VERSION ""

NS_ :

BS_:

BU_:  Inverter  Battery  Charger  Host

BO_ 2626158596 BATT_diagnosticVBricksB_4: 8 Battery
 SG_ BATT_vBrick06_4 : 16|16@1+ (7.6e-05,0) [0|4.98066] "V" Host
 SG_ BATT_vBrick07_4 : 32|16@1+ (7.6e-05,0) [0|4.98066] "V" Host
 SG_ BATT_vBrick05_4 : 0|16@1+ (7.6e-05,0) [0|4.98066] "V" Host
 SG_ BATT_vBrick08_4 : 48|16@1+ (7.6e-05,0) [0|4.98066] "V" Host

BO_ 2626158597 BATT_diagnosticVBricksB_5: 8 Battery
 SG_ BATT_vBrick06_5 : 16|16@1+ (7.6e-05,0) [0|4.98066] "V" Host
 SG_ BATT_vBrick07_5 : 32|16@1+ (7.6e-05,0) [0|4.98066] "V" Host
 SG_ BATT_vBrick05_5 : 0|16@1+ (7.6e-05,0) [0|4.98066] "V" Host
 SG_ BATT_vBrick08_5 : 48|16@1+ (7.6e-05,0) [0|4.98066] "V" Host

BO_ 2626158598 BATT_diagnosticVBricksB_6: 8 Battery
 SG_ BATT_vBrick06_6 : 16|16@1+ (7.6e-05,0) [0|4.98066] "V" Host
 SG_ BATT_vBrick07_6 : 32|16@1+ (7.6e-05,0) [0|4.98066] "V" Host
 SG_ BATT_vBrick05_6 : 0|16@1+ (7.6e-05,0) [0|4.98066] "V" Host
 SG_ BATT_vBrick08_6 : 48|16@1+ (7.6e-05,0) [0|4.98066] "V" Host

BO_ 2626158599 BATT_diagnosticVBricksB_7: 8 Battery
 SG_ BATT_vBrick06_7 : 16|16@1+ (7.6e-05,0) [0|4.98066] "V" Host
 SG_ BATT_vBrick07_7 : 32|16@1+ (7.6e-05,0) [0|4.98066] "V" Host
 SG_ BATT_vBrick05_7 : 0|16@1+ (7.6e-05,0) [0|4.98066] "V" Host
 SG_ BATT_vBrick08_7 : 48|16@1+ (7.6e-05,0) [0|4.98066] "V" Host

BO_ 2626420736 BATT_diagnosticVBricksC_0: 8 Battery
 SG_ BATT_vBrick12_0 : 48|16@1+ (7.6e-05,0) [0|4.98066] "V" Host
 SG_ BATT_vBrick11_0 : 32|16@1+ (7.6e-05,0) [0|4.98066] "V" Host
 SG_ BATT_vBrick10_0 : 16|16@1+ (7.6e-05,0) [0|4.98066] "V" Host
 SG_ BATT_vBrick09_0 : 0|16@1+ (7.6e-05,0) [0|4.98066] "V" Host

BO_ 2626420737 BATT_diagnosticVBricksC_1: 8 Battery
 SG_ BATT_vBrick12_1 : 48|16@1+ (7.6e-05,0) [0|4.98066] "V" Host
 SG_ BATT_vBrick11_1 : 32|16@1+ (7.6e-05,0) [0|4.98066] "V" Host
 SG_ BATT_vBrick10_1 : 16|16@1+ (7.6e-05,0) [0|4.98066] "V" Host
 SG_ BATT_vBrick09_1 : 0|16@1+ (7.6e-05,0) [0|4.98066] "V" Host

BO_ 2626420738 BATT_diagnosticVBricksC_2: 8 Battery
 SG_ BATT_vBrick12_2 : 48|16@1+ (7.6e-05,0) [0|4.98066] "V" Host
 SG_ BATT_vBrick11_2 : 32|16@1+ (7.6e-05,0) [0|4.98066] "V" Host
 SG_ BATT_vBrick10_2 : 16|16@1+ (7.6e-05,0) [0|4.98066] "V" Host
 SG_ BATT_vBrick09_2 : 0|16@1+ (7.6e-05,0) [0|4.98066] "V" Host

BO_ 2626420739 BATT_diagnosticVBricksC_3: 8 Battery
 SG_ BATT_vBrick12_3 : 48|16@1+ (7.6e-05,0) [0|4.98066] "V" Host
 SG_ BATT_vBrick11_3 : 32|16@1+ (7.6e-05,0) [0|4.98066] "V" Host
 SG_ BATT_vBrick10_3 : 16|16@1+ (7.6e-05,0) [0|4.98066] "V" Host
 SG_ BATT_vBrick09_3 : 0|16@1+ (7.6e-05,0) [0|4.98066] "V" Host

BO_ 2626420740 BATT_diagnosticVBricksC_4: 8 Battery
 SG_ BATT_vBrick12_4 : 48|16@1+ (7.6e-05,0) [0|4.98066] "V" Host
 SG_ BATT_vBrick11_4 : 32|16@1+ (7.6e-05,0) [0|4.98066] "V" Host
 SG_ BATT_vBrick10_4 : 16|16@1+ (7.6e-05,0) [0|4.98066] "V" Host
 SG_ BATT_vBrick09_4 : 0|16@1+ (7.6e-05,0) [0|4.98066] "V" Host

BO_ 2626420741 BATT_diagnosticVBricksC_5: 8 Battery
 SG_ BATT_vBrick12_5 : 48|16@1+ (7.6e-05,0) [0|4.98066] "V" Host
 SG_ BATT_vBrick11_5 : 32|16@1+ (7.6e-05,0) [0|4.98066] "V" Host
 SG_ BATT_vBrick10_5 : 16|16@1+ (7.6e-05,0) [0|4.98066] "V" Host
 SG_ BATT_vBrick09_5 : 0|16@1+ (7.6e-05,0) [0|4.98066] "V" Host

BO_ 2626420742 BATT_diagnosticVBricksC_6: 8 Battery
 SG_ BATT_vBrick12_6 : 48|16@1+ (7.6e-05,0) [0|4.98066] "V" Host
 SG_ BATT_vBrick11_6 : 32|16@1+ (7.6e-05,0) [0|4.98066] "V" Host
 SG_ BATT_vBrick10_6 : 16|16@1+ (7.6e-05,0) [0|4.98066] "V" Host
 SG_ BATT_vBrick09_6 : 0|16@1+ (7.6e-05,0) [0|4.98066] "V" Host

BO_ 2626420743 BATT_diagnosticVBricksC_7: 8 Battery
 SG_ BATT_vBrick12_7 : 48|16@1+ (7.6e-05,0) [0|4.98066] "V" Host
 SG_ BATT_vBrick11_7 : 32|16@1+ (7.6e-05,0) [0|4.98066] "V" Host
 SG_ BATT_vBrick10_7 : 16|16@1+ (7.6e-05,0) [0|4.98066] "V" Host
 SG_ BATT_vBrick09_7 : 0|16@1+ (7.6e-05,0) [0|4.98066] "V" Host

BO_ 2626682880 BATT_diagnosticVBricksD_0: 4 Battery
 SG_ BATT_vBrick14_0 : 16|16@1+ (7.6e-05,0) [0|4.98066] "V" Host
 SG_ BATT_vBrick13_0 : 0|16@1+ (7.6e-05,0) [0|4.98066] "V" Host

BO_ 2626682881 BATT_diagnosticVBricksD_1: 4 Battery
 SG_ BATT_vBrick14_1 : 16|16@1+ (7.6e-05,0) [0|4.98066] "V" Host
 SG_ BATT_vBrick13_1 : 0|16@1+ (7.6e-05,0) [0|4.98066] "V" Host

BO_ 2626682882 BATT_diagnosticVBricksD_2: 4 Battery
 SG_ BATT_vBrick14_2 : 16|16@1+ (7.6e-05,0) [0|4.98066] "V" Host
 SG_ BATT_vBrick13_2 : 0|16@1+ (7.6e-05,0) [0|4.98066] "V" Host

BO_ 2626682883 BATT_diagnosticVBricksD_3: 4 Battery
 SG_ BATT_vBrick14_3 : 16|16@1+ (7.6e-05,0) [0|4.98066] "V" Host
 SG_ BATT_vBrick13_3 : 0|16@1+ (7.6e-05,0) [0|4.98066] "V" Host

BO_ 2626682884 BATT_diagnosticVBricksD_4: 4 Battery
 SG_ BATT_vBrick14_4 : 16|16@1+ (7.6e-05,0) [0|4.98066] "V" Host
 SG_ BATT_vBrick13_4 : 0|16@1+ (7.6e-05,0) [0|4.98066] "V" Host

BO_ 2626682885 BATT_diagnosticVBricksD_5: 4 Battery
 SG_ BATT_vBrick14_5 : 16|16@1+ (7.6e-05,0) [0|4.98066] "V" Host
 SG_ BATT_vBrick13_5 : 0|16@1+ (7.6e-05,0) [0|4.98066] "V" Host

BO_ 2626682886 BATT_diagnosticVBricksD_6: 4 Battery
 SG_ BATT_vBrick14_6 : 16|16@1+ (7.6e-05,0) [0|4.98066] "V" Host
 SG_ BATT_vBrick13_6 : 0|16@1+ (7.6e-05,0) [0|4.98066] "V" Host

BO_ 2626682887 BATT_diagnosticVBricksD_7: 4 Battery
 SG_ BATT_vBrick14_7 : 16|16@1+ (7.6e-05,0) [0|4.98066] "V" Host
 SG_ BATT_vBrick13_7 : 0|16@1+ (7.6e-05,0) [0|4.98066] "V" Host

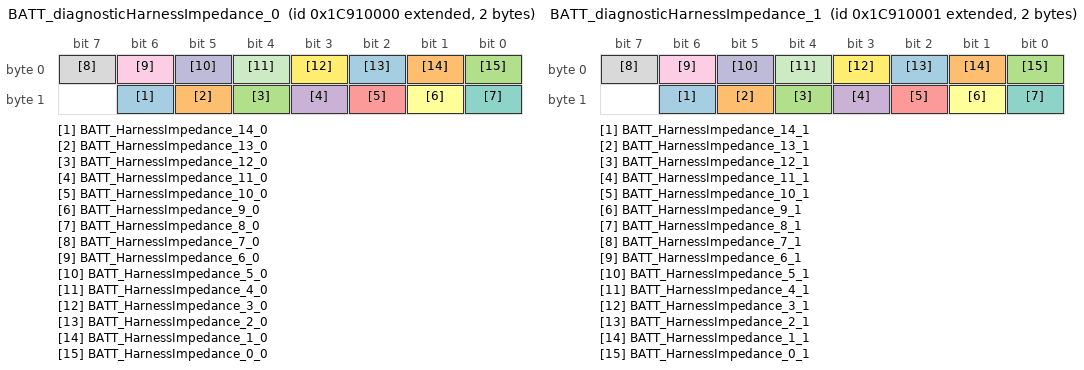
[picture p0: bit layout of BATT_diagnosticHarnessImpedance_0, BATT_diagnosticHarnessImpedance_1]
BO_ 2626748416 BATT_diagnosticHarnessImpedance_0: 2 Battery
 SG_ BATT_HarnessImpedance_14_0 : 14|1@1+ (1,0) [0|1] "mOhms" Host
 SG_ BATT_HarnessImpedance_13_0 : 13|1@1+ (1,0) [0|1] "mOhms" Host
 SG_ BATT_HarnessImpedance_12_0 : 12|1@1+ (1,0) [0|1] "mOhms" Host
 SG_ BATT_HarnessImpedance_11_0 : 11|1@1+ (1,0) [0|1] "mOhms" Host
 SG_ BATT_HarnessImpedance_10_0 : 10|1@1+ (1,0) [0|1] "mOhms" Host
 SG_ BATT_HarnessImpedance_9_0 : 9|1@1+ (1,0) [0|1] "mOhms" Host
 SG_ BATT_HarnessImpedance_8_0 : 8|1@1+ (1,0) [0|1] "mOhms" Host
 SG_ BATT_HarnessImpedance_7_0 : 7|1@1+ (1,0) [0|1] "mOhms" Host
 SG_ BATT_HarnessImpedance_6_0 : 6|1@1+ (1,0) [0|1] "mOhms" Host
 SG_ BATT_HarnessImpedance_5_0 : 5|1@1+ (1,0) [0|1] "mOhms" Host
 SG_ BATT_HarnessImpedance_4_0 : 4|1@1+ (1,0) [0|1] "mOhms" Host
 SG_ BATT_HarnessImpedance_3_0 : 3|1@1+ (1,0) [0|1] "mOhms" Host
 SG_ BATT_HarnessImpedance_2_0 : 2|1@1+ (1,0) [0|1] "mOhms" Host
 SG_ BATT_HarnessImpedance_1_0 : 1|1@1+ (1,0) [0|1] "mOhms" Host
 SG_ BATT_HarnessImpedance_0_0 : 0|1@1+ (1,0) [0|1] "mOhms" Host

BO_ 2626748417 BATT_diagnosticHarnessImpedance_1: 2 Battery
 SG_ BATT_HarnessImpedance_14_1 : 14|1@1+ (1,0) [0|1] "mOhms" Host
 SG_ BATT_HarnessImpedance_13_1 : 13|1@1+ (1,0) [0|1] "mOhms" Host
 SG_ BATT_HarnessImpedance_12_1 : 12|1@1+ (1,0) [0|1] "mOhms" Host
 SG_ BATT_HarnessImpedance_11_1 : 11|1@1+ (1,0) [0|1] "mOhms" Host
 SG_ BATT_HarnessImpedance_10_1 : 10|1@1+ (1,0) [0|1] "mOhms" Host
 SG_ BATT_HarnessImpedance_9_1 : 9|1@1+ (1,0) [0|1] "mOhms" Host
 SG_ BATT_HarnessImpedance_8_1 : 8|1@1+ (1,0) [0|1] "mOhms" Host
 SG_ BATT_HarnessImpedance_7_1 : 7|1@1+ (1,0) [0|1] "mOhms" Host
 SG_ BATT_HarnessImpedance_6_1 : 6|1@1+ (1,0) [0|1] "mOhms" Host
 SG_ BATT_HarnessImpedance_5_1 : 5|1@1+ (1,0) [0|1] "mOhms" Host
 SG_ BATT_HarnessImpedance_4_1 : 4|1@1+ (1,0) [0|1] "mOhms" Host
 SG_ BATT_HarnessImpedance_3_1 : 3|1@1+ (1,0) [0|1] "mOhms" Host
 SG_ BATT_HarnessImpedance_2_1 : 2|1@1+ (1,0) [0|1] "mOhms" Host
 SG_ BATT_HarnessImpedance_1_1 : 1|1@1+ (1,0) [0|1] "mOhms" Host
 SG_ BATT_HarnessImpedance_0_1 : 0|1@1+ (1,0) [0|1] "mOhms" Host

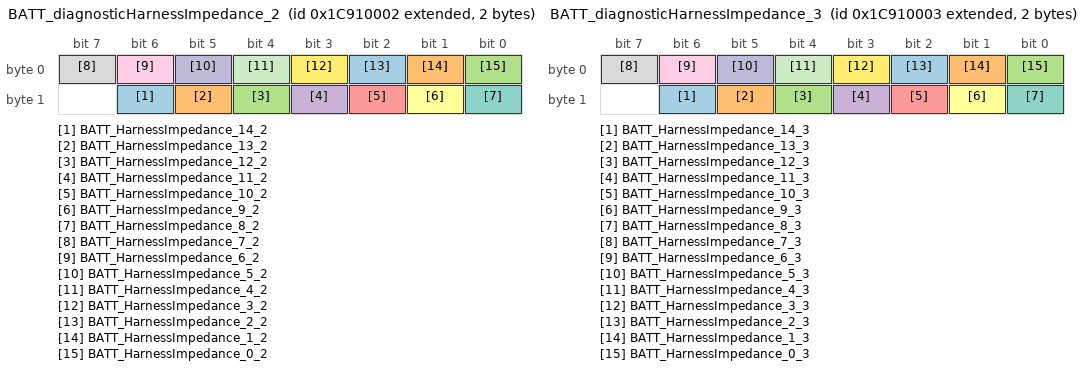
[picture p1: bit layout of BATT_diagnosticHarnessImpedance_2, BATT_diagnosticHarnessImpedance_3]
BO_ 2626748418 BATT_diagnosticHarnessImpedance_2: 2 Battery
 SG_ BATT_HarnessImpedance_14_2 : 14|1@1+ (1,0) [0|1] "mOhms" Host
 SG_ BATT_HarnessImpedance_13_2 : 13|1@1+ (1,0) [0|1] "mOhms" Host
 SG_ BATT_HarnessImpedance_12_2 : 12|1@1+ (1,0) [0|1] "mOhms" Host
 SG_ BATT_HarnessImpedance_11_2 : 11|1@1+ (1,0) [0|1] "mOhms" Host
 SG_ BATT_HarnessImpedance_10_2 : 10|1@1+ (1,0) [0|1] "mOhms" Host
 SG_ BATT_HarnessImpedance_9_2 : 9|1@1+ (1,0) [0|1] "mOhms" Host
 SG_ BATT_HarnessImpedance_8_2 : 8|1@1+ (1,0) [0|1] "mOhms" Host
 SG_ BATT_HarnessImpedance_7_2 : 7|1@1+ (1,0) [0|1] "mOhms" Host
 SG_ BATT_HarnessImpedance_6_2 : 6|1@1+ (1,0) [0|1] "mOhms" Host
 SG_ BATT_HarnessImpedance_5_2 : 5|1@1+ (1,0) [0|1] "mOhms" Host
 SG_ BATT_HarnessImpedance_4_2 : 4|1@1+ (1,0) [0|1] "mOhms" Host
 SG_ BATT_HarnessImpedance_3_2 : 3|1@1+ (1,0) [0|1] "mOhms" Host
 SG_ BATT_HarnessImpedance_2_2 : 2|1@1+ (1,0) [0|1] "mOhms" Host
 SG_ BATT_HarnessImpedance_1_2 : 1|1@1+ (1,0) [0|1] "mOhms" Host
 SG_ BATT_HarnessImpedance_0_2 : 0|1@1+ (1,0) [0|1] "mOhms" Host

BO_ 2626748419 BATT_diagnosticHarnessImpedance_3: 2 Battery
 SG_ BATT_HarnessImpedance_14_3 : 14|1@1+ (1,0) [0|1] "mOhms" Host
 SG_ BATT_HarnessImpedance_13_3 : 13|1@1+ (1,0) [0|1] "mOhms" Host
 SG_ BATT_HarnessImpedance_12_3 : 12|1@1+ (1,0) [0|1] "mOhms" Host
 SG_ BATT_HarnessImpedance_11_3 : 11|1@1+ (1,0) [0|1] "mOhms" Host
 SG_ BATT_HarnessImpedance_10_3 : 10|1@1+ (1,0) [0|1] "mOhms" Host
 SG_ BATT_HarnessImpedance_9_3 : 9|1@1+ (1,0) [0|1] "mOhms" Host
 SG_ BATT_HarnessImpedance_8_3 : 8|1@1+ (1,0) [0|1] "mOhms" Host
 SG_ BATT_HarnessImpedance_7_3 : 7|1@1+ (1,0) [0|1] "mOhms" Host
 SG_ BATT_HarnessImpedance_6_3 : 6|1@1+ (1,0) [0|1] "mOhms" Host
 SG_ BATT_HarnessImpedance_5_3 : 5|1@1+ (1,0) [0|1] "mOhms" Host
 SG_ BATT_HarnessImpedance_4_3 : 4|1@1+ (1,0) [0|1] "mOhms" Host
 SG_ BATT_HarnessImpedance_3_3 : 3|1@1+ (1,0) [0|1] "mOhms" Host
 SG_ BATT_HarnessImpedance_2_3 : 2|1@1+ (1,0) [0|1] "mOhms" Host
 SG_ BATT_HarnessImpedance_1_3 : 1|1@1+ (1,0) [0|1] "mOhms" Host
 SG_ BATT_HarnessImpedance_0_3 : 0|1@1+ (1,0) [0|1] "mOhms" Host

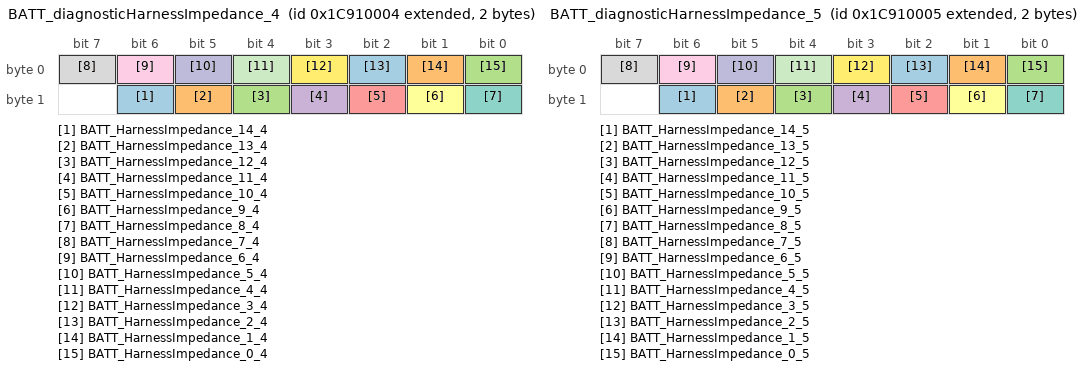
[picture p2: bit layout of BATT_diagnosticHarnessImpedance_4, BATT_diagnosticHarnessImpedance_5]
BO_ 2626748420 BATT_diagnosticHarnessImpedance_4: 2 Battery
 SG_ BATT_HarnessImpedance_14_4 : 14|1@1+ (1,0) [0|1] "mOhms" Host
 SG_ BATT_HarnessImpedance_13_4 : 13|1@1+ (1,0) [0|1] "mOhms" Host
 SG_ BATT_HarnessImpedance_12_4 : 12|1@1+ (1,0) [0|1] "mOhms" Host
 SG_ BATT_HarnessImpedance_11_4 : 11|1@1+ (1,0) [0|1] "mOhms" Host
 SG_ BATT_HarnessImpedance_10_4 : 10|1@1+ (1,0) [0|1] "mOhms" Host
 SG_ BATT_HarnessImpedance_9_4 : 9|1@1+ (1,0) [0|1] "mOhms" Host
 SG_ BATT_HarnessImpedance_8_4 : 8|1@1+ (1,0) [0|1] "mOhms" Host
 SG_ BATT_HarnessImpedance_7_4 : 7|1@1+ (1,0) [0|1] "mOhms" Host
 SG_ BATT_HarnessImpedance_6_4 : 6|1@1+ (1,0) [0|1] "mOhms" Host
 SG_ BATT_HarnessImpedance_5_4 : 5|1@1+ (1,0) [0|1] "mOhms" Host
 SG_ BATT_HarnessImpedance_4_4 : 4|1@1+ (1,0) [0|1] "mOhms" Host
 SG_ BATT_HarnessImpedance_3_4 : 3|1@1+ (1,0) [0|1] "mOhms" Host
 SG_ BATT_HarnessImpedance_2_4 : 2|1@1+ (1,0) [0|1] "mOhms" Host
 SG_ BATT_HarnessImpedance_1_4 : 1|1@1+ (1,0) [0|1] "mOhms" Host
 SG_ BATT_HarnessImpedance_0_4 : 0|1@1+ (1,0) [0|1] "mOhms" Host

BO_ 2626748421 BATT_diagnosticHarnessImpedance_5: 2 Battery
 SG_ BATT_HarnessImpedance_14_5 : 14|1@1+ (1,0) [0|1] "mOhms" Host
 SG_ BATT_HarnessImpedance_13_5 : 13|1@1+ (1,0) [0|1] "mOhms" Host
 SG_ BATT_HarnessImpedance_12_5 : 12|1@1+ (1,0) [0|1] "mOhms" Host
 SG_ BATT_HarnessImpedance_11_5 : 11|1@1+ (1,0) [0|1] "mOhms" Host
 SG_ BATT_HarnessImpedance_10_5 : 10|1@1+ (1,0) [0|1] "mOhms" Host
 SG_ BATT_HarnessImpedance_9_5 : 9|1@1+ (1,0) [0|1] "mOhms" Host
 SG_ BATT_HarnessImpedance_8_5 : 8|1@1+ (1,0) [0|1] "mOhms" Host
 SG_ BATT_HarnessImpedance_7_5 : 7|1@1+ (1,0) [0|1] "mOhms" Host
 SG_ BATT_HarnessImpedance_6_5 : 6|1@1+ (1,0) [0|1] "mOhms" Host
 SG_ BATT_HarnessImpedance_5_5 : 5|1@1+ (1,0) [0|1] "mOhms" Host
 SG_ BATT_HarnessImpedance_4_5 : 4|1@1+ (1,0) [0|1] "mOhms" Host
 SG_ BATT_HarnessImpedance_3_5 : 3|1@1+ (1,0) [0|1] "mOhms" Host
 SG_ BATT_HarnessImpedance_2_5 : 2|1@1+ (1,0) [0|1] "mOhms" Host
 SG_ BATT_HarnessImpedance_1_5 : 1|1@1+ (1,0) [0|1] "mOhms" Host
 SG_ BATT_HarnessImpedance_0_5 : 0|1@1+ (1,0) [0|1] "mOhms" Host

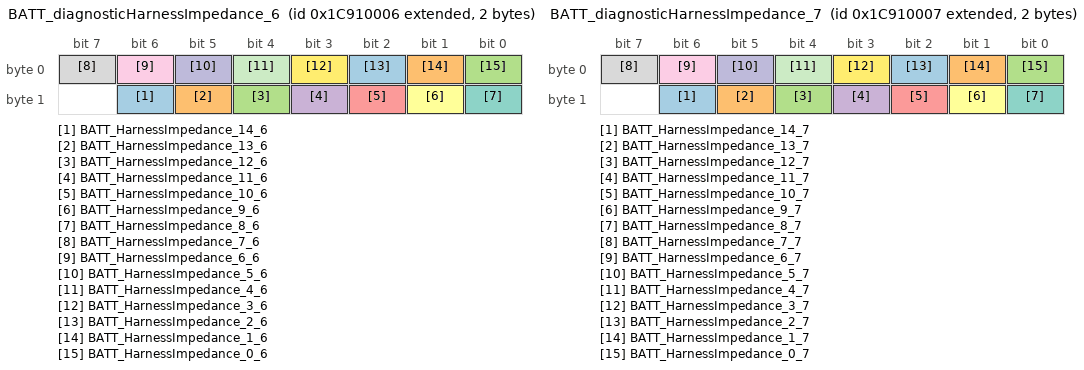
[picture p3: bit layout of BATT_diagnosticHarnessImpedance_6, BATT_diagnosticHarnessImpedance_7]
BO_ 2626748422 BATT_diagnosticHarnessImpedance_6: 2 Battery
 SG_ BATT_HarnessImpedance_14_6 : 14|1@1+ (1,0) [0|1] "mOhms" Host
 SG_ BATT_HarnessImpedance_13_6 : 13|1@1+ (1,0) [0|1] "mOhms" Host
 SG_ BATT_HarnessImpedance_12_6 : 12|1@1+ (1,0) [0|1] "mOhms" Host
 SG_ BATT_HarnessImpedance_11_6 : 11|1@1+ (1,0) [0|1] "mOhms" Host
 SG_ BATT_HarnessImpedance_10_6 : 10|1@1+ (1,0) [0|1] "mOhms" Host
 SG_ BATT_HarnessImpedance_9_6 : 9|1@1+ (1,0) [0|1] "mOhms" Host
 SG_ BATT_HarnessImpedance_8_6 : 8|1@1+ (1,0) [0|1] "mOhms" Host
 SG_ BATT_HarnessImpedance_7_6 : 7|1@1+ (1,0) [0|1] "mOhms" Host
 SG_ BATT_HarnessImpedance_6_6 : 6|1@1+ (1,0) [0|1] "mOhms" Host
 SG_ BATT_HarnessImpedance_5_6 : 5|1@1+ (1,0) [0|1] "mOhms" Host
 SG_ BATT_HarnessImpedance_4_6 : 4|1@1+ (1,0) [0|1] "mOhms" Host
 SG_ BATT_HarnessImpedance_3_6 : 3|1@1+ (1,0) [0|1] "mOhms" Host
 SG_ BATT_HarnessImpedance_2_6 : 2|1@1+ (1,0) [0|1] "mOhms" Host
 SG_ BATT_HarnessImpedance_1_6 : 1|1@1+ (1,0) [0|1] "mOhms" Host
 SG_ BATT_HarnessImpedance_0_6 : 0|1@1+ (1,0) [0|1] "mOhms" Host

BO_ 2626748423 BATT_diagnosticHarnessImpedance_7: 2 Battery
 SG_ BATT_HarnessImpedance_14_7 : 14|1@1+ (1,0) [0|1] "mOhms" Host
 SG_ BATT_HarnessImpedance_13_7 : 13|1@1+ (1,0) [0|1] "mOhms" Host
 SG_ BATT_HarnessImpedance_12_7 : 12|1@1+ (1,0) [0|1] "mOhms" Host
 SG_ BATT_HarnessImpedance_11_7 : 11|1@1+ (1,0) [0|1] "mOhms" Host
 SG_ BATT_HarnessImpedance_10_7 : 10|1@1+ (1,0) [0|1] "mOhms" Host
 SG_ BATT_HarnessImpedance_9_7 : 9|1@1+ (1,0) [0|1] "mOhms" Host
 SG_ BATT_HarnessImpedance_8_7 : 8|1@1+ (1,0) [0|1] "mOhms" Host
 SG_ BATT_HarnessImpedance_7_7 : 7|1@1+ (1,0) [0|1] "mOhms" Host
 SG_ BATT_HarnessImpedance_6_7 : 6|1@1+ (1,0) [0|1] "mOhms" Host
 SG_ BATT_HarnessImpedance_5_7 : 5|1@1+ (1,0) [0|1] "mOhms" Host
 SG_ BATT_HarnessImpedance_4_7 : 4|1@1+ (1,0) [0|1] "mOhms" Host
 SG_ BATT_HarnessImpedance_3_7 : 3|1@1+ (1,0) [0|1] "mOhms" Host
 SG_ BATT_HarnessImpedance_2_7 : 2|1@1+ (1,0) [0|1] "mOhms" Host
 SG_ BATT_HarnessImpedance_1_7 : 1|1@1+ (1,0) [0|1] "mOhms" Host
 SG_ BATT_HarnessImpedance_0_7 : 0|1@1+ (1,0) [0|1] "mOhms" Host

BO_ 2626813952 BATT_diagnosticHrnsImpDleta_0_0: 8 Battery
 SG_ BATT_HrnsImpDelta_3_0 : 48|16@1- (0.001,0) [-32.768|32.767] "mV" Host
 SG_ BATT_HrnsImpDelta_2_0 : 32|16@1- (0.001,0) [-32.768|32.767] "mV" Host
 SG_ BATT_HrnsImpDelta_1_0 : 16|16@1- (0.001,0) [-32.768|32.767] "mV" Host
 SG_ BATT_HrnsImpDelta_0_0 : 0|16@1- (0.001,0) [-32.768|32.767] "mV" Host

BO_ 2626813953 BATT_diagnosticHrnsImpDleta_0_1: 8 Battery
 SG_ BATT_HrnsImpDelta_3_1 : 48|16@1- (0.001,0) [-32.768|32.767] "mV" Host
 SG_ BATT_HrnsImpDelta_2_1 : 32|16@1- (0.001,0) [-32.768|32.767] "mV" Host
 SG_ BATT_HrnsImpDelta_1_1 : 16|16@1- (0.001,0) [-32.768|32.767] "mV" Host
 SG_ BATT_HrnsImpDelta_0_1 : 0|16@1- (0.001,0) [-32.768|32.767] "mV" Host

BO_ 2626813954 BATT_diagnosticHrnsImpDleta_0_2: 8 Battery
 SG_ BATT_HrnsImpDelta_3_2 : 48|16@1- (0.001,0) [-32.768|32.767] "mV" Host
 SG_ BATT_HrnsImpDelta_2_2 : 32|16@1- (0.001,0) [-32.768|32.767] "mV" Host
 SG_ BATT_HrnsImpDelta_1_2 : 16|16@1- (0.001,0) [-32.768|32.767] "mV" Host
 SG_ BATT_HrnsImpDelta_0_2 : 0|16@1- (0.001,0) [-32.768|32.767] "mV" Host

BO_ 2626813955 BATT_diagnosticHrnsImpDleta_0_3: 8 Battery
 SG_ BATT_HrnsImpDelta_3_3 : 48|16@1- (0.001,0) [-32.768|32.767] "mV" Host
 SG_ BATT_HrnsImpDelta_2_3 : 32|16@1- (0.001,0) [-32.768|32.767] "mV" Host
 SG_ BATT_HrnsImpDelta_1_3 : 16|16@1- (0.001,0) [-32.768|32.767] "mV" Host
 SG_ BATT_HrnsImpDelta_0_3 : 0|16@1- (0.001,0) [-32.768|32.767] "mV" Host

BO_ 2626813956 BATT_diagnosticHrnsImpDleta_0_4: 8 Battery
 SG_ BATT_HrnsImpDelta_3_4 : 48|16@1- (0.001,0) [-32.768|32.767] "mV" Host
 SG_ BATT_HrnsImpDelta_2_4 : 32|16@1- (0.001,0) [-32.768|32.767] "mV" Host
 SG_ BATT_HrnsImpDelta_1_4 : 16|16@1- (0.001,0) [-32.768|32.767] "mV" Host
 SG_ BATT_HrnsImpDelta_0_4 : 0|16@1- (0.001,0) [-32.768|32.767] "mV" Host

BO_ 2626813957 BATT_diagnosticHrnsImpDleta_0_5: 8 Battery
 SG_ BATT_HrnsImpDelta_3_5 : 48|16@1- (0.001,0) [-32.768|32.767] "mV" Host
 SG_ BATT_HrnsImpDelta_2_5 : 32|16@1- (0.001,0) [-32.768|32.767] "mV" Host
 SG_ BATT_HrnsImpDelta_1_5 : 16|16@1- (0.001,0) [-32.768|32.767] "mV" Host
 SG_ BATT_HrnsImpDelta_0_5 : 0|16@1- (0.001,0) [-32.768|32.767] "mV" Host

BO_ 2626813958 BATT_diagnosticHrnsImpDleta_0_6: 8 Battery
 SG_ BATT_HrnsImpDelta_3_6 : 48|16@1- (0.001,0) [-32.768|32.767] "mV" Host
 SG_ BATT_HrnsImpDelta_2_6 : 32|16@1- (0.001,0) [-32.768|32.767] "mV" Host
 SG_ BATT_HrnsImpDelta_1_6 : 16|16@1- (0.001,0) [-32.768|32.767] "mV" Host
 SG_ BATT_HrnsImpDelta_0_6 : 0|16@1- (0.001,0) [-32.768|32.767] "mV" Host

BO_ 2626813959 BATT_diagnosticHrnsImpDleta_0_7: 8 Battery
 SG_ BATT_HrnsImpDelta_3_7 : 48|16@1- (0.001,0) [-32.768|32.767] "mV" Host
 SG_ BATT_HrnsImpDelta_2_7 : 32|16@1- (0.001,0) [-32.768|32.767] "mV" Host
 SG_ BATT_HrnsImpDelta_1_7 : 16|16@1- (0.001,0) [-32.768|32.767] "mV" Host
 SG_ BATT_HrnsImpDelta_0_7 : 0|16@1- (0.001,0) [-32.768|32.767] "mV" Host

BO_ 2626818048 BATT_diagnosticHrnsImpDleta_1_0: 8 Battery
 SG_ BATT_HrnsImpDelta_7_0 : 48|16@1- (0.001,0) [-32.768|32.767] "mV" Host
 SG_ BATT_HrnsImpDelta_6_0 : 32|16@1- (0.001,0) [-32.768|32.767] "mV" Host
 SG_ BATT_HrnsImpDelta_5_0 : 16|16@1- (0.001,0) [-32.768|32.767] "mV" Host
 SG_ BATT_HrnsImpDelta_4_0 : 0|16@1- (0.001,0) [-32.768|32.767] "mV" Host

BO_ 2626818049 BATT_diagnosticHrnsImpDleta_1_1: 8 Battery
 SG_ BATT_HrnsImpDelta_7_1 : 48|16@1- (0.001,0) [-32.768|32.767] "mV" Host
 SG_ BATT_HrnsImpDelta_6_1 : 32|16@1- (0.001,0) [-32.768|32.767] "mV" Host
 SG_ BATT_HrnsImpDelta_5_1 : 16|16@1- (0.001,0) [-32.768|32.767] "mV" Host
 SG_ BATT_HrnsImpDelta_4_1 : 0|16@1- (0.001,0) [-32.768|32.767] "mV" Host

BO_ 2626818050 BATT_diagnosticHrnsImpDleta_1_2: 8 Battery
 SG_ BATT_HrnsImpDelta_7_2 : 48|16@1- (0.001,0) [-32.768|32.767] "mV" Host
 SG_ BATT_HrnsImpDelta_6_2 : 32|16@1- (0.001,0) [-32.768|32.767] "mV" Host
 SG_ BATT_HrnsImpDelta_5_2 : 16|16@1- (0.001,0) [-32.768|32.767] "mV" Host
 SG_ BATT_HrnsImpDelta_4_2 : 0|16@1- (0.001,0) [-32.768|32.767] "mV" Host

BO_ 2626818051 BATT_diagnosticHrnsImpDleta_1_3: 8 Battery
 SG_ BATT_HrnsImpDelta_7_3 : 48|16@1- (0.001,0) [-32.768|32.767] "mV" Host
 SG_ BATT_HrnsImpDelta_6_3 : 32|16@1- (0.001,0) [-32.768|32.767] "mV" Host
 SG_ BATT_HrnsImpDelta_5_3 : 16|16@1- (0.001,0) [-32.768|32.767] "mV" Host
 SG_ BATT_HrnsImpDelta_4_3 : 0|16@1- (0.001,0) [-32.768|32.767] "mV" Host

BO_ 2626818052 BATT_diagnosticHrnsImpDleta_1_4: 8 Battery
 SG_ BATT_HrnsImpDelta_7_4 : 48|16@1- (0.001,0) [-32.768|32.767] "mV" Host
 SG_ BATT_HrnsImpDelta_6_4 : 32|16@1- (0.001,0) [-32.768|32.767] "mV" Host
 SG_ BATT_HrnsImpDelta_5_4 : 16|16@1- (0.001,0) [-32.768|32.767] "mV" Host
 SG_ BATT_HrnsImpDelta_4_4 : 0|16@1- (0.001,0) [-32.768|32.767] "mV" Host

BO_ 2626818053 BATT_diagnosticHrnsImpDleta_1_5: 8 Battery
 SG_ BATT_HrnsImpDelta_7_5 : 48|16@1- (0.001,0) [-32.768|32.767] "mV" Host
 SG_ BATT_HrnsImpDelta_6_5 : 32|16@1- (0.001,0) [-32.768|32.767] "mV" Host
 SG_ BATT_HrnsImpDelta_5_5 : 16|16@1- (0.001,0) [-32.768|32.767] "mV" Host
 SG_ BATT_HrnsImpDelta_4_5 : 0|16@1- (0.001,0) [-32.768|32.767] "mV" Host

BO_ 2626818054 BATT_diagnosticHrnsImpDleta_1_6: 8 Battery
 SG_ BATT_HrnsImpDelta_7_6 : 48|16@1- (0.001,0) [-32.768|32.767] "mV" Host
 SG_ BATT_HrnsImpDelta_6_6 : 32|16@1- (0.001,0) [-32.768|32.767] "mV" Host
 SG_ BATT_HrnsImpDelta_5_6 : 16|16@1- (0.001,0) [-32.768|32.767] "mV" Host
 SG_ BATT_HrnsImpDelta_4_6 : 0|16@1- (0.001,0) [-32.768|32.767] "mV" Host

BO_ 2626818055 BATT_diagnosticHrnsImpDleta_1_7: 8 Battery
 SG_ BATT_HrnsImpDelta_7_7 : 48|16@1- (0.001,0) [-32.768|32.767] "mV" Host
 SG_ BATT_HrnsImpDelta_6_7 : 32|16@1- (0.001,0) [-32.768|32.767] "mV" Host
 SG_ BATT_HrnsImpDelta_5_7 : 16|16@1- (0.001,0) [-32.768|32.767] "mV" Host
 SG_ BATT_HrnsImpDelta_4_7 : 0|16@1- (0.001,0) [-32.768|32.767] "mV" Host

BO_ 2626822144 BATT_diagnosticHrnsImpDleta_2_0: 8 Battery
 SG_ BATT_HrnsImpDelta_11_0 : 48|16@1- (0.001,0) [-32.768|32.767] "mV" Host
 SG_ BATT_HrnsImpDelta_10_0 : 32|16@1- (0.001,0) [-32.768|32.767] "mV" Host
 SG_ BATT_HrnsImpDelta_9_0 : 16|16@1- (0.001,0) [-32.768|32.767] "mV" Host
 SG_ BATT_HrnsImpDelta_8_0 : 0|16@1- (0.001,0) [-32.768|32.767] "mV" Host

BO_ 2626822145 BATT_diagnosticHrnsImpDleta_2_1: 8 Battery
 SG_ BATT_HrnsImpDelta_11_1 : 48|16@1- (0.001,0) [-32.768|32.767] "mV" Host
 SG_ BATT_HrnsImpDelta_10_1 : 32|16@1- (0.001,0) [-32.768|32.767] "mV" Host
 SG_ BATT_HrnsImpDelta_9_1 : 16|16@1- (0.001,0) [-32.768|32.767] "mV" Host
 SG_ BATT_HrnsImpDelta_8_1 : 0|16@1- (0.001,0) [-32.768|32.767] "mV" Host

BO_ 2626822146 BATT_diagnosticHrnsImpDleta_2_2: 8 Battery
 SG_ BATT_HrnsImpDelta_11_2 : 48|16@1- (0.001,0) [-32.768|32.767] "mV" Host
 SG_ BATT_HrnsImpDelta_10_2 : 32|16@1- (0.001,0) [-32.768|32.767] "mV" Host
 SG_ BATT_HrnsImpDelta_9_2 : 16|16@1- (0.001,0) [-32.768|32.767] "mV" Host
 SG_ BATT_HrnsImpDelta_8_2 : 0|16@1- (0.001,0) [-32.768|32.767] "mV" Host

BO_ 2626822147 BATT_diagnosticHrnsImpDleta_2_3: 8 Battery
 SG_ BATT_HrnsImpDelta_11_3 : 48|16@1- (0.001,0) [-32.768|32.767] "mV" Host
 SG_ BATT_HrnsImpDelta_10_3 : 32|16@1- (0.001,0) [-32.768|32.767] "mV" Host
 SG_ BATT_HrnsImpDelta_9_3 : 16|16@1- (0.001,0) [-32.768|32.767] "mV" Host
 SG_ BATT_HrnsImpDelta_8_3 : 0|16@1- (0.001,0) [-32.768|32.767] "mV" Host

BO_ 2626822148 BATT_diagnosticHrnsImpDleta_2_4: 8 Battery
 SG_ BATT_HrnsImpDelta_11_4 : 48|16@1- (0.001,0) [-32.768|32.767] "mV" Host
 SG_ BATT_HrnsImpDelta_10_4 : 32|16@1- (0.001,0) [-32.768|32.767] "mV" Host
 SG_ BATT_HrnsImpDelta_9_4 : 16|16@1- (0.001,0) [-32.768|32.767] "mV" Host
 SG_ BATT_HrnsImpDelta_8_4 : 0|16@1- (0.001,0) [-32.768|32.767] "mV" Host

BO_ 2626822149 BATT_diagnosticHrnsImpDleta_2_5: 8 Battery
 SG_ BATT_HrnsImpDelta_11_5 : 48|16@1- (0.001,0) [-32.768|32.767] "mV" Host
 SG_ BATT_HrnsImpDelta_10_5 : 32|16@1- (0.001,0) [-32.768|32.767] "mV" Host
 SG_ BATT_HrnsImpDelta_9_5 : 16|16@1- (0.001,0) [-32.768|32.767] "mV" Host
 SG_ BATT_HrnsImpDelta_8_5 : 0|16@1- (0.001,0) [-32.768|32.767] "mV" Host

BO_ 2626822150 BATT_diagnosticHrnsImpDleta_2_6: 8 Battery
 SG_ BATT_HrnsImpDelta_11_6 : 48|16@1- (0.001,0) [-32.768|32.767] "mV" Host
 SG_ BATT_HrnsImpDelta_10_6 : 32|16@1- (0.001,0) [-32.768|32.767] "mV" Host
 SG_ BATT_HrnsImpDelta_9_6 : 16|16@1- (0.001,0) [-32.768|32.767] "mV" Host
 SG_ BATT_HrnsImpDelta_8_6 : 0|16@1- (0.001,0) [-32.768|32.767] "mV" Host

BO_ 2626822151 BATT_diagnosticHrnsImpDleta_2_7: 8 Battery
 SG_ BATT_HrnsImpDelta_11_7 : 48|16@1- (0.001,0) [-32.768|32.767] "mV" Host
 SG_ BATT_HrnsImpDelta_10_7 : 32|16@1- (0.001,0) [-32.768|32.767] "mV" Host
 SG_ BATT_HrnsImpDelta_9_7 : 16|16@1- (0.001,0) [-32.768|32.767] "mV" Host
 SG_ BATT_HrnsImpDelta_8_7 : 0|16@1- (0.001,0) [-32.768|32.767] "mV" Host

BO_ 2626826240 BATT_diagnosticHrnsImpDleta_3_0: 6 Battery
 SG_ BATT_HrnsImpDelta_14_0 : 32|16@1- (0.001,0) [-32.768|32.767] "mV" Host
 SG_ BATT_HrnsImpDelta_13_0 : 16|16@1- (0.001,0) [-32.768|32.767] "mV" Host
 SG_ BATT_HrnsImpDelta_12_0 : 0|16@1- (0.001,0) [-32.768|32.767] "mV" Host

BO_ 2626826241 BATT_diagnosticHrnsImpDleta_3_1: 6 Battery
 SG_ BATT_HrnsImpDelta_14_1 : 32|16@1- (0.001,0) [-32.768|32.767] "mV" Host
 SG_ BATT_HrnsImpDelta_13_1 : 16|16@1- (0.001,0) [-32.768|32.767] "mV" Host
 SG_ BATT_HrnsImpDelta_12_1 : 0|16@1- (0.001,0) [-32.768|32.767] "mV" Host

BO_ 2626826242 BATT_diagnosticHrnsImpDleta_3_2: 6 Battery
 SG_ BATT_HrnsImpDelta_14_2 : 32|16@1- (0.001,0) [-32.768|32.767] "mV" Host
 SG_ BATT_HrnsImpDelta_13_2 : 16|16@1- (0.001,0) [-32.768|32.767] "mV" Host
 SG_ BATT_HrnsImpDelta_12_2 : 0|16@1- (0.001,0) [-32.768|32.767] "mV" Host

BO_ 2626826243 BATT_diagnosticHrnsImpDleta_3_3: 6 Battery
 SG_ BATT_HrnsImpDelta_14_3 : 32|16@1- (0.001,0) [-32.768|32.767] "mV" Host
 SG_ BATT_HrnsImpDelta_13_3 : 16|16@1- (0.001,0) [-32.768|32.767] "mV" Host
 SG_ BATT_HrnsImpDelta_12_3 : 0|16@1- (0.001,0) [-32.768|32.767] "mV" Host

BO_ 2626826244 BATT_diagnosticHrnsImpDleta_3_4: 6 Battery
 SG_ BATT_HrnsImpDelta_14_4 : 32|16@1- (0.001,0) [-32.768|32.767] "mV" Host
 SG_ BATT_HrnsImpDelta_13_4 : 16|16@1- (0.001,0) [-32.768|32.767] "mV" Host
 SG_ BATT_HrnsImpDelta_12_4 : 0|16@1- (0.001,0) [-32.768|32.767] "mV" Host

BO_ 2626826245 BATT_diagnosticHrnsImpDleta_3_5: 6 Battery
 SG_ BATT_HrnsImpDelta_14_5 : 32|16@1- (0.001,0) [-32.768|32.767] "mV" Host
 SG_ BATT_HrnsImpDelta_13_5 : 16|16@1- (0.001,0) [-32.768|32.767] "mV" Host
 SG_ BATT_HrnsImpDelta_12_5 : 0|16@1- (0.001,0) [-32.768|32.767] "mV" Host

BO_ 2626826246 BATT_diagnosticHrnsImpDleta_3_6: 6 Battery
 SG_ BATT_HrnsImpDelta_14_6 : 32|16@1- (0.001,0) [-32.768|32.767] "mV" Host
 SG_ BATT_HrnsImpDelta_13_6 : 16|16@1- (0.001,0) [-32.768|32.767] "mV" Host
 SG_ BATT_HrnsImpDelta_12_6 : 0|16@1- (0.001,0) [-32.768|32.767] "mV" Host

BO_ 2626826247 BATT_diagnosticHrnsImpDleta_3_7: 6 Battery
 SG_ BATT_HrnsImpDelta_14_7 : 32|16@1- (0.001,0) [-32.768|32.767] "mV" Host
 SG_ BATT_HrnsImpDelta_13_7 : 16|16@1- (0.001,0) [-32.768|32.767] "mV" Host
 SG_ BATT_HrnsImpDelta_12_7 : 0|16@1- (0.001,0) [-32.768|32.767] "mV" Host

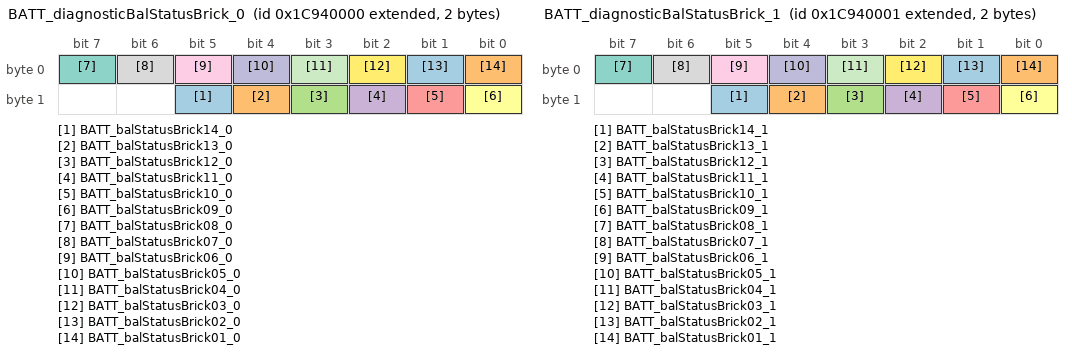
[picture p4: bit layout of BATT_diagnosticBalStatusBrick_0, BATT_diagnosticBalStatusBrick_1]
BO_ 2626945024 BATT_diagnosticBalStatusBrick_0: 2 Battery
 SG_ BATT_balStatusBrick14_0 : 13|1@1+ (1,0) [0|1] "" Host
 SG_ BATT_balStatusBrick13_0 : 12|1@1+ (1,0) [0|1] "" Host
 SG_ BATT_balStatusBrick12_0 : 11|1@1+ (1,0) [0|1] "" Host
 SG_ BATT_balStatusBrick11_0 : 10|1@1+ (1,0) [0|1] "" Host
 SG_ BATT_balStatusBrick10_0 : 9|1@1+ (1,0) [0|1] "" Host
 SG_ BATT_balStatusBrick09_0 : 8|1@1+ (1,0) [0|1] "" Host
 SG_ BATT_balStatusBrick08_0 : 7|1@1+ (1,0) [0|1] "" Host
 SG_ BATT_balStatusBrick07_0 : 6|1@1+ (1,0) [0|1] "" Host
 SG_ BATT_balStatusBrick06_0 : 5|1@1+ (1,0) [0|1] "" Host
 SG_ BATT_balStatusBrick05_0 : 4|1@1+ (1,0) [0|1] "" Host
 SG_ BATT_balStatusBrick04_0 : 3|1@1+ (1,0) [0|1] "" Host
 SG_ BATT_balStatusBrick03_0 : 2|1@1+ (1,0) [0|1] "" Host
 SG_ BATT_balStatusBrick02_0 : 1|1@1+ (1,0) [0|1] "" Host
 SG_ BATT_balStatusBrick01_0 : 0|1@1+ (1,0) [0|1] "" Host

BO_ 2626945025 BATT_diagnosticBalStatusBrick_1: 2 Battery
 SG_ BATT_balStatusBrick14_1 : 13|1@1+ (1,0) [0|1] "" Host
 SG_ BATT_balStatusBrick13_1 : 12|1@1+ (1,0) [0|1] "" Host
 SG_ BATT_balStatusBrick12_1 : 11|1@1+ (1,0) [0|1] "" Host
 SG_ BATT_balStatusBrick11_1 : 10|1@1+ (1,0) [0|1] "" Host
 SG_ BATT_balStatusBrick10_1 : 9|1@1+ (1,0) [0|1] "" Host
 SG_ BATT_balStatusBrick09_1 : 8|1@1+ (1,0) [0|1] "" Host
 SG_ BATT_balStatusBrick08_1 : 7|1@1+ (1,0) [0|1] "" Host
 SG_ BATT_balStatusBrick07_1 : 6|1@1+ (1,0) [0|1] "" Host
 SG_ BATT_balStatusBrick06_1 : 5|1@1+ (1,0) [0|1] "" Host
 SG_ BATT_balStatusBrick05_1 : 4|1@1+ (1,0) [0|1] "" Host
 SG_ BATT_balStatusBrick04_1 : 3|1@1+ (1,0) [0|1] "" Host
 SG_ BATT_balStatusBrick03_1 : 2|1@1+ (1,0) [0|1] "" Host
 SG_ BATT_balStatusBrick02_1 : 1|1@1+ (1,0) [0|1] "" Host
 SG_ BATT_balStatusBrick01_1 : 0|1@1+ (1,0) [0|1] "" Host

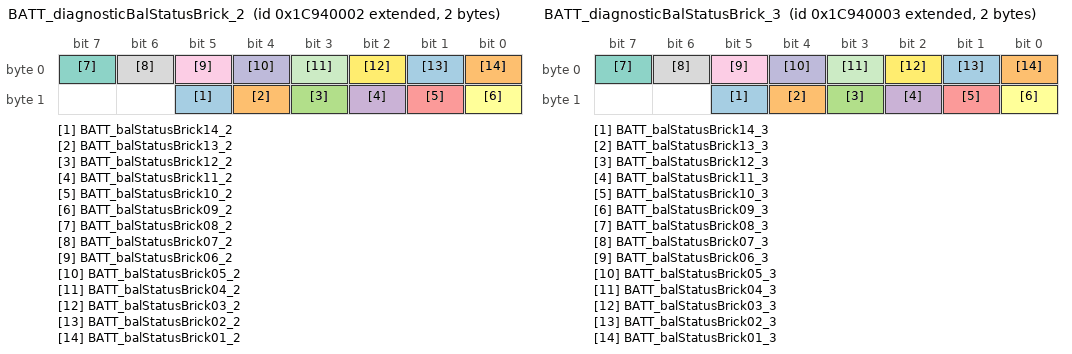
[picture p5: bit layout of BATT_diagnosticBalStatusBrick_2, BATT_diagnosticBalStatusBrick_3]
BO_ 2626945026 BATT_diagnosticBalStatusBrick_2: 2 Battery
 SG_ BATT_balStatusBrick14_2 : 13|1@1+ (1,0) [0|1] "" Host
 SG_ BATT_balStatusBrick13_2 : 12|1@1+ (1,0) [0|1] "" Host
 SG_ BATT_balStatusBrick12_2 : 11|1@1+ (1,0) [0|1] "" Host
 SG_ BATT_balStatusBrick11_2 : 10|1@1+ (1,0) [0|1] "" Host
 SG_ BATT_balStatusBrick10_2 : 9|1@1+ (1,0) [0|1] "" Host
 SG_ BATT_balStatusBrick09_2 : 8|1@1+ (1,0) [0|1] "" Host
 SG_ BATT_balStatusBrick08_2 : 7|1@1+ (1,0) [0|1] "" Host
 SG_ BATT_balStatusBrick07_2 : 6|1@1+ (1,0) [0|1] "" Host
 SG_ BATT_balStatusBrick06_2 : 5|1@1+ (1,0) [0|1] "" Host
 SG_ BATT_balStatusBrick05_2 : 4|1@1+ (1,0) [0|1] "" Host
 SG_ BATT_balStatusBrick04_2 : 3|1@1+ (1,0) [0|1] "" Host
 SG_ BATT_balStatusBrick03_2 : 2|1@1+ (1,0) [0|1] "" Host
 SG_ BATT_balStatusBrick02_2 : 1|1@1+ (1,0) [0|1] "" Host
 SG_ BATT_balStatusBrick01_2 : 0|1@1+ (1,0) [0|1] "" Host

BO_ 2626945027 BATT_diagnosticBalStatusBrick_3: 2 Battery
 SG_ BATT_balStatusBrick14_3 : 13|1@1+ (1,0) [0|1] "" Host
 SG_ BATT_balStatusBrick13_3 : 12|1@1+ (1,0) [0|1] "" Host
 SG_ BATT_balStatusBrick12_3 : 11|1@1+ (1,0) [0|1] "" Host
 SG_ BATT_balStatusBrick11_3 : 10|1@1+ (1,0) [0|1] "" Host
 SG_ BATT_balStatusBrick10_3 : 9|1@1+ (1,0) [0|1] "" Host
 SG_ BATT_balStatusBrick09_3 : 8|1@1+ (1,0) [0|1] "" Host
 SG_ BATT_balStatusBrick08_3 : 7|1@1+ (1,0) [0|1] "" Host
 SG_ BATT_balStatusBrick07_3 : 6|1@1+ (1,0) [0|1] "" Host
 SG_ BATT_balStatusBrick06_3 : 5|1@1+ (1,0) [0|1] "" Host
 SG_ BATT_balStatusBrick05_3 : 4|1@1+ (1,0) [0|1] "" Host
 SG_ BATT_balStatusBrick04_3 : 3|1@1+ (1,0) [0|1] "" Host
 SG_ BATT_balStatusBrick03_3 : 2|1@1+ (1,0) [0|1] "" Host
 SG_ BATT_balStatusBrick02_3 : 1|1@1+ (1,0) [0|1] "" Host
 SG_ BATT_balStatusBrick01_3 : 0|1@1+ (1,0) [0|1] "" Host

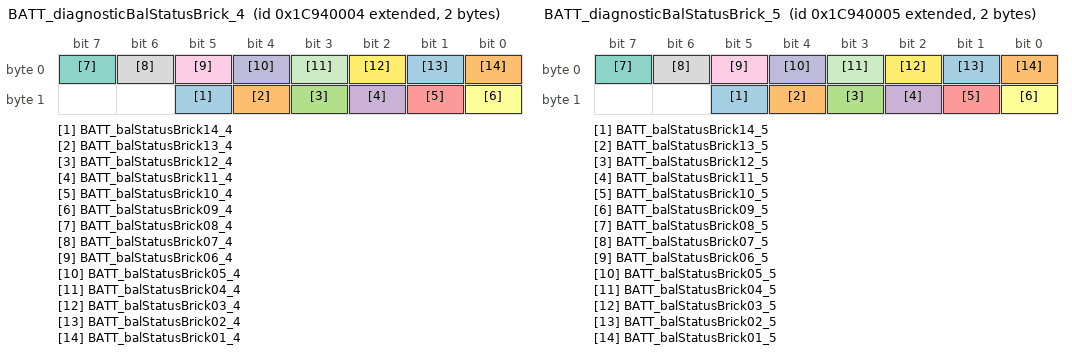
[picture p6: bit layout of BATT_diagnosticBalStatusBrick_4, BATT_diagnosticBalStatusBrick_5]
BO_ 2626945028 BATT_diagnosticBalStatusBrick_4: 2 Battery
 SG_ BATT_balStatusBrick14_4 : 13|1@1+ (1,0) [0|1] "" Host
 SG_ BATT_balStatusBrick13_4 : 12|1@1+ (1,0) [0|1] "" Host
 SG_ BATT_balStatusBrick12_4 : 11|1@1+ (1,0) [0|1] "" Host
 SG_ BATT_balStatusBrick11_4 : 10|1@1+ (1,0) [0|1] "" Host
 SG_ BATT_balStatusBrick10_4 : 9|1@1+ (1,0) [0|1] "" Host
 SG_ BATT_balStatusBrick09_4 : 8|1@1+ (1,0) [0|1] "" Host
 SG_ BATT_balStatusBrick08_4 : 7|1@1+ (1,0) [0|1] "" Host
 SG_ BATT_balStatusBrick07_4 : 6|1@1+ (1,0) [0|1] "" Host
 SG_ BATT_balStatusBrick06_4 : 5|1@1+ (1,0) [0|1] "" Host
 SG_ BATT_balStatusBrick05_4 : 4|1@1+ (1,0) [0|1] "" Host
 SG_ BATT_balStatusBrick04_4 : 3|1@1+ (1,0) [0|1] "" Host
 SG_ BATT_balStatusBrick03_4 : 2|1@1+ (1,0) [0|1] "" Host
 SG_ BATT_balStatusBrick02_4 : 1|1@1+ (1,0) [0|1] "" Host
 SG_ BATT_balStatusBrick01_4 : 0|1@1+ (1,0) [0|1] "" Host

BO_ 2626945029 BATT_diagnosticBalStatusBrick_5: 2 Battery
 SG_ BATT_balStatusBrick14_5 : 13|1@1+ (1,0) [0|1] "" Host
 SG_ BATT_balStatusBrick13_5 : 12|1@1+ (1,0) [0|1] "" Host
 SG_ BATT_balStatusBrick12_5 : 11|1@1+ (1,0) [0|1] "" Host
 SG_ BATT_balStatusBrick11_5 : 10|1@1+ (1,0) [0|1] "" Host
 SG_ BATT_balStatusBrick10_5 : 9|1@1+ (1,0) [0|1] "" Host
 SG_ BATT_balStatusBrick09_5 : 8|1@1+ (1,0) [0|1] "" Host
 SG_ BATT_balStatusBrick08_5 : 7|1@1+ (1,0) [0|1] "" Host
 SG_ BATT_balStatusBrick07_5 : 6|1@1+ (1,0) [0|1] "" Host
 SG_ BATT_balStatusBrick06_5 : 5|1@1+ (1,0) [0|1] "" Host
 SG_ BATT_balStatusBrick05_5 : 4|1@1+ (1,0) [0|1] "" Host
 SG_ BATT_balStatusBrick04_5 : 3|1@1+ (1,0) [0|1] "" Host
 SG_ BATT_balStatusBrick03_5 : 2|1@1+ (1,0) [0|1] "" Host
 SG_ BATT_balStatusBrick02_5 : 1|1@1+ (1,0) [0|1] "" Host
 SG_ BATT_balStatusBrick01_5 : 0|1@1+ (1,0) [0|1] "" Host

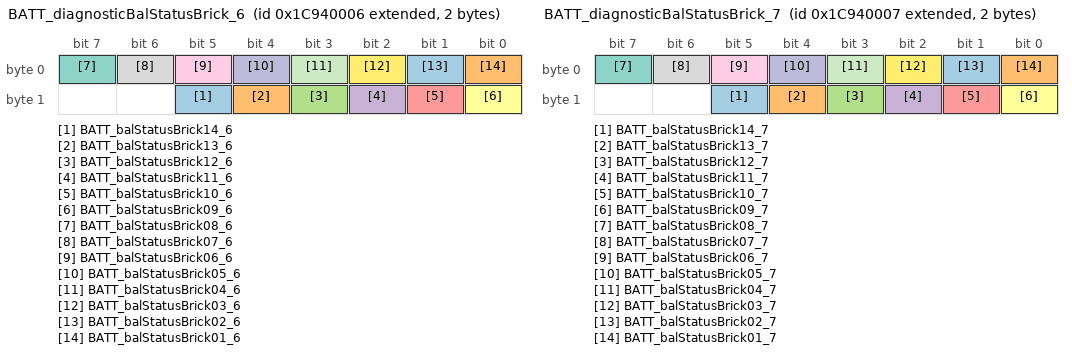
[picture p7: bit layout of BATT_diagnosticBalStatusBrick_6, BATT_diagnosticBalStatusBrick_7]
BO_ 2626945030 BATT_diagnosticBalStatusBrick_6: 2 Battery
 SG_ BATT_balStatusBrick14_6 : 13|1@1+ (1,0) [0|1] "" Host
 SG_ BATT_balStatusBrick13_6 : 12|1@1+ (1,0) [0|1] "" Host
 SG_ BATT_balStatusBrick12_6 : 11|1@1+ (1,0) [0|1] "" Host
 SG_ BATT_balStatusBrick11_6 : 10|1@1+ (1,0) [0|1] "" Host
 SG_ BATT_balStatusBrick10_6 : 9|1@1+ (1,0) [0|1] "" Host
 SG_ BATT_balStatusBrick09_6 : 8|1@1+ (1,0) [0|1] "" Host
 SG_ BATT_balStatusBrick08_6 : 7|1@1+ (1,0) [0|1] "" Host
 SG_ BATT_balStatusBrick07_6 : 6|1@1+ (1,0) [0|1] "" Host
 SG_ BATT_balStatusBrick06_6 : 5|1@1+ (1,0) [0|1] "" Host
 SG_ BATT_balStatusBrick05_6 : 4|1@1+ (1,0) [0|1] "" Host
 SG_ BATT_balStatusBrick04_6 : 3|1@1+ (1,0) [0|1] "" Host
 SG_ BATT_balStatusBrick03_6 : 2|1@1+ (1,0) [0|1] "" Host
 SG_ BATT_balStatusBrick02_6 : 1|1@1+ (1,0) [0|1] "" Host
 SG_ BATT_balStatusBrick01_6 : 0|1@1+ (1,0) [0|1] "" Host

BO_ 2626945031 BATT_diagnosticBalStatusBrick_7: 2 Battery
 SG_ BATT_balStatusBrick14_7 : 13|1@1+ (1,0) [0|1] "" Host
 SG_ BATT_balStatusBrick13_7 : 12|1@1+ (1,0) [0|1] "" Host
 SG_ BATT_balStatusBrick12_7 : 11|1@1+ (1,0) [0|1] "" Host
 SG_ BATT_balStatusBrick11_7 : 10|1@1+ (1,0) [0|1] "" Host
 SG_ BATT_balStatusBrick10_7 : 9|1@1+ (1,0) [0|1] "" Host
 SG_ BATT_balStatusBrick09_7 : 8|1@1+ (1,0) [0|1] "" Host
 SG_ BATT_balStatusBrick08_7 : 7|1@1+ (1,0) [0|1] "" Host
 SG_ BATT_balStatusBrick07_7 : 6|1@1+ (1,0) [0|1] "" Host
 SG_ BATT_balStatusBrick06_7 : 5|1@1+ (1,0) [0|1] "" Host
 SG_ BATT_balStatusBrick05_7 : 4|1@1+ (1,0) [0|1] "" Host
 SG_ BATT_balStatusBrick04_7 : 3|1@1+ (1,0) [0|1] "" Host
 SG_ BATT_balStatusBrick03_7 : 2|1@1+ (1,0) [0|1] "" Host
 SG_ BATT_balStatusBrick02_7 : 1|1@1+ (1,0) [0|1] "" Host
 SG_ BATT_balStatusBrick01_7 : 0|1@1+ (1,0) [0|1] "" Host

BO_ 2629828608 BATT_diagnosticAhTotal_0: 8 Battery
 SG_ BATT_ahDchTotal_0 : 32|32@1+ (0.1,0) [0|500000] "Ah" Host
 SG_ BATT_ahChgTotal_0 : 0|32@1+ (0.1,0) [0|500000] "Ah" Host

BO_ 2629828609 BATT_diagnosticAhTotal_1: 8 Battery
 SG_ BATT_ahDchTotal_1 : 32|32@1+ (0.1,0) [0|500000] "Ah" Host
 SG_ BATT_ahChgTotal_1 : 0|32@1+ (0.1,0) [0|500000] "Ah" Host

BO_ 2629828610 BATT_diagnosticAhTotal_2: 8 Battery
 SG_ BATT_ahDchTotal_2 : 32|32@1+ (0.1,0) [0|500000] "Ah" Host
 SG_ BATT_ahChgTotal_2 : 0|32@1+ (0.1,0) [0|500000] "Ah" Host

BO_ 2629828611 BATT_diagnosticAhTotal_3: 8 Battery
 SG_ BATT_ahDchTotal_3 : 32|32@1+ (0.1,0) [0|500000] "Ah" Host
 SG_ BATT_ahChgTotal_3 : 0|32@1+ (0.1,0) [0|500000] "Ah" Host

BO_ 2629828612 BATT_diagnosticAhTotal_4: 8 Battery
 SG_ BATT_ahDchTotal_4 : 32|32@1+ (0.1,0) [0|500000] "Ah" Host
 SG_ BATT_ahChgTotal_4 : 0|32@1+ (0.1,0) [0|500000] "Ah" Host

BO_ 2629828613 BATT_diagnosticAhTotal_5: 8 Battery
 SG_ BATT_ahDchTotal_5 : 32|32@1+ (0.1,0) [0|500000] "Ah" Host
 SG_ BATT_ahChgTotal_5 : 0|32@1+ (0.1,0) [0|500000] "Ah" Host

BO_ 2629828614 BATT_diagnosticAhTotal_6: 8 Battery
 SG_ BATT_ahDchTotal_6 : 32|32@1+ (0.1,0) [0|500000] "Ah" Host
 SG_ BATT_ahChgTotal_6 : 0|32@1+ (0.1,0) [0|500000] "Ah" Host

BO_ 2629828615 BATT_diagnosticAhTotal_7: 8 Battery
 SG_ BATT_ahDchTotal_7 : 32|32@1+ (0.1,0) [0|500000] "Ah" Host
 SG_ BATT_ahChgTotal_7 : 0|32@1+ (0.1,0) [0|500000] "Ah" Host

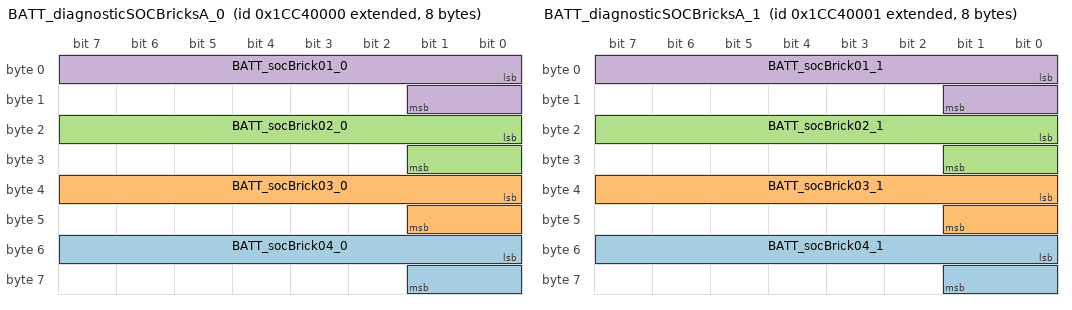
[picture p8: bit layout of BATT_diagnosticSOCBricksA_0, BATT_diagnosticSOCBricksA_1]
BO_ 2630090752 BATT_diagnosticSOCBricksA_0: 8 Battery
 SG_ BATT_socBrick04_0 : 48|10@1+ (0.1,0) [0|102.3] "%" Host
 SG_ BATT_socBrick03_0 : 32|10@1+ (0.1,0) [0|102.3] "%" Host
 SG_ BATT_socBrick02_0 : 16|10@1+ (0.1,0) [0|102.3] "%" Host
 SG_ BATT_socBrick01_0 : 0|10@1+ (0.1,0) [0|102.3] "%" Host

BO_ 2630090753 BATT_diagnosticSOCBricksA_1: 8 Battery
 SG_ BATT_socBrick04_1 : 48|10@1+ (0.1,0) [0|102.3] "%" Host
 SG_ BATT_socBrick03_1 : 32|10@1+ (0.1,0) [0|102.3] "%" Host
 SG_ BATT_socBrick02_1 : 16|10@1+ (0.1,0) [0|102.3] "%" Host
 SG_ BATT_socBrick01_1 : 0|10@1+ (0.1,0) [0|102.3] "%" Host

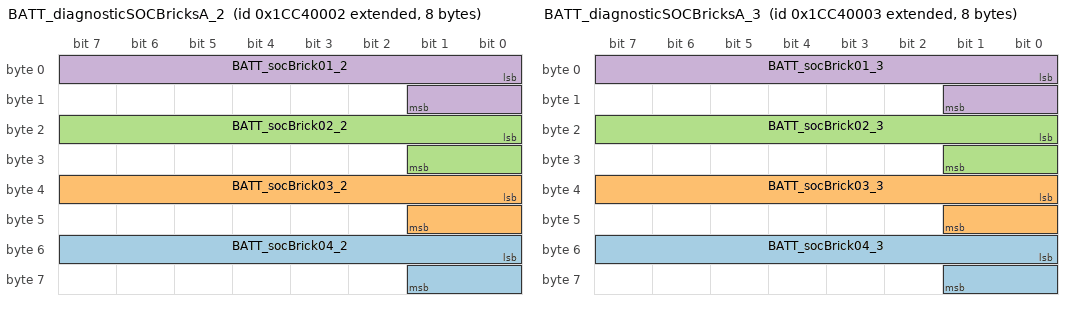
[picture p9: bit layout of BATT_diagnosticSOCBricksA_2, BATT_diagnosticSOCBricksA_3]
BO_ 2630090754 BATT_diagnosticSOCBricksA_2: 8 Battery
 SG_ BATT_socBrick04_2 : 48|10@1+ (0.1,0) [0|102.3] "%" Host
 SG_ BATT_socBrick03_2 : 32|10@1+ (0.1,0) [0|102.3] "%" Host
 SG_ BATT_socBrick02_2 : 16|10@1+ (0.1,0) [0|102.3] "%" Host
 SG_ BATT_socBrick01_2 : 0|10@1+ (0.1,0) [0|102.3] "%" Host

BO_ 2630090755 BATT_diagnosticSOCBricksA_3: 8 Battery
 SG_ BATT_socBrick04_3 : 48|10@1+ (0.1,0) [0|102.3] "%" Host
 SG_ BATT_socBrick03_3 : 32|10@1+ (0.1,0) [0|102.3] "%" Host
 SG_ BATT_socBrick02_3 : 16|10@1+ (0.1,0) [0|102.3] "%" Host
 SG_ BATT_socBrick01_3 : 0|10@1+ (0.1,0) [0|102.3] "%" Host

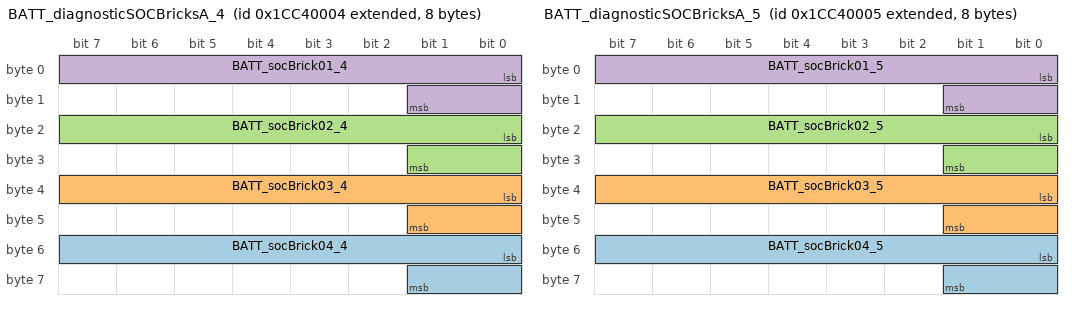
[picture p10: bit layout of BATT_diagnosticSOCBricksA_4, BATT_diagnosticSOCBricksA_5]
BO_ 2630090756 BATT_diagnosticSOCBricksA_4: 8 Battery
 SG_ BATT_socBrick04_4 : 48|10@1+ (0.1,0) [0|102.3] "%" Host
 SG_ BATT_socBrick03_4 : 32|10@1+ (0.1,0) [0|102.3] "%" Host
 SG_ BATT_socBrick02_4 : 16|10@1+ (0.1,0) [0|102.3] "%" Host
 SG_ BATT_socBrick01_4 : 0|10@1+ (0.1,0) [0|102.3] "%" Host

BO_ 2630090757 BATT_diagnosticSOCBricksA_5: 8 Battery
 SG_ BATT_socBrick04_5 : 48|10@1+ (0.1,0) [0|102.3] "%" Host
 SG_ BATT_socBrick03_5 : 32|10@1+ (0.1,0) [0|102.3] "%" Host
 SG_ BATT_socBrick02_5 : 16|10@1+ (0.1,0) [0|102.3] "%" Host
 SG_ BATT_socBrick01_5 : 0|10@1+ (0.1,0) [0|102.3] "%" Host

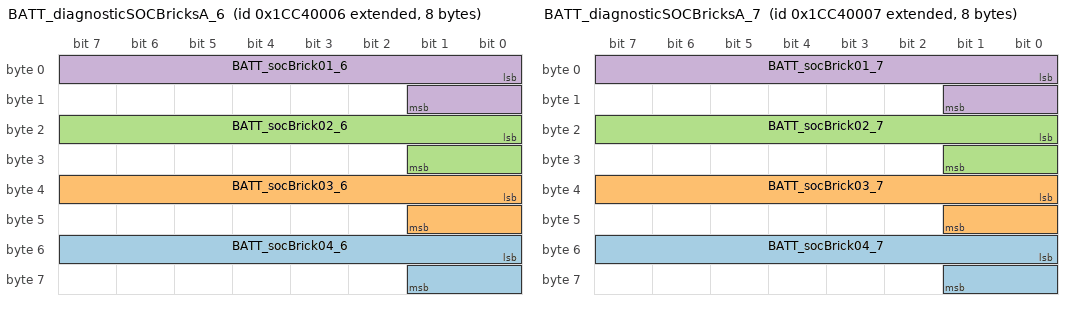
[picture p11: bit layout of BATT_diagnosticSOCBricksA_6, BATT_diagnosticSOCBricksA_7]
BO_ 2630090758 BATT_diagnosticSOCBricksA_6: 8 Battery
 SG_ BATT_socBrick04_6 : 48|10@1+ (0.1,0) [0|102.3] "%" Host
 SG_ BATT_socBrick03_6 : 32|10@1+ (0.1,0) [0|102.3] "%" Host
 SG_ BATT_socBrick02_6 : 16|10@1+ (0.1,0) [0|102.3] "%" Host
 SG_ BATT_socBrick01_6 : 0|10@1+ (0.1,0) [0|102.3] "%" Host

BO_ 2630090759 BATT_diagnosticSOCBricksA_7: 8 Battery
 SG_ BATT_socBrick04_7 : 48|10@1+ (0.1,0) [0|102.3] "%" Host
 SG_ BATT_socBrick03_7 : 32|10@1+ (0.1,0) [0|102.3] "%" Host
 SG_ BATT_socBrick02_7 : 16|10@1+ (0.1,0) [0|102.3] "%" Host
 SG_ BATT_socBrick01_7 : 0|10@1+ (0.1,0) [0|102.3] "%" Host

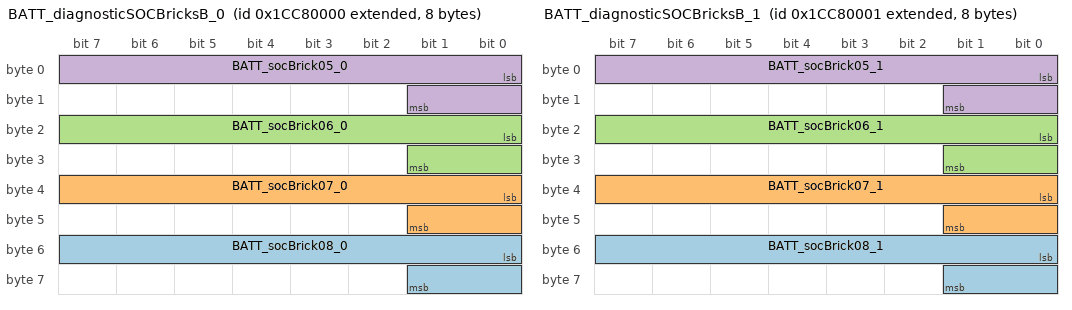
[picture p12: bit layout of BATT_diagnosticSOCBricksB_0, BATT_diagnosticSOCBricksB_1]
BO_ 2630352896 BATT_diagnosticSOCBricksB_0: 8 Battery
 SG_ BATT_socBrick08_0 : 48|10@1+ (0.1,0) [0|102.3] "%" Host
 SG_ BATT_socBrick07_0 : 32|10@1+ (0.1,0) [0|102.3] "%" Host
 SG_ BATT_socBrick06_0 : 16|10@1+ (0.1,0) [0|102.3] "%" Host
 SG_ BATT_socBrick05_0 : 0|10@1+ (0.1,0) [0|102.3] "%" Host

BO_ 2630352897 BATT_diagnosticSOCBricksB_1: 8 Battery
 SG_ BATT_socBrick08_1 : 48|10@1+ (0.1,0) [0|102.3] "%" Host
 SG_ BATT_socBrick07_1 : 32|10@1+ (0.1,0) [0|102.3] "%" Host
 SG_ BATT_socBrick06_1 : 16|10@1+ (0.1,0) [0|102.3] "%" Host
 SG_ BATT_socBrick05_1 : 0|10@1+ (0.1,0) [0|102.3] "%" Host

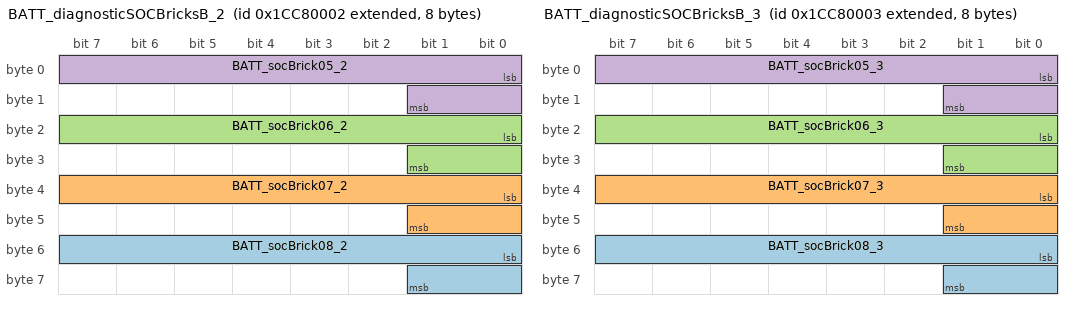
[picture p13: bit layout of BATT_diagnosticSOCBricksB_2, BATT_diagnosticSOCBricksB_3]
BO_ 2630352898 BATT_diagnosticSOCBricksB_2: 8 Battery
 SG_ BATT_socBrick08_2 : 48|10@1+ (0.1,0) [0|102.3] "%" Host
 SG_ BATT_socBrick07_2 : 32|10@1+ (0.1,0) [0|102.3] "%" Host
 SG_ BATT_socBrick06_2 : 16|10@1+ (0.1,0) [0|102.3] "%" Host
 SG_ BATT_socBrick05_2 : 0|10@1+ (0.1,0) [0|102.3] "%" Host

BO_ 2630352899 BATT_diagnosticSOCBricksB_3: 8 Battery
 SG_ BATT_socBrick08_3 : 48|10@1+ (0.1,0) [0|102.3] "%" Host
 SG_ BATT_socBrick07_3 : 32|10@1+ (0.1,0) [0|102.3] "%" Host
 SG_ BATT_socBrick06_3 : 16|10@1+ (0.1,0) [0|102.3] "%" Host
 SG_ BATT_socBrick05_3 : 0|10@1+ (0.1,0) [0|102.3] "%" Host

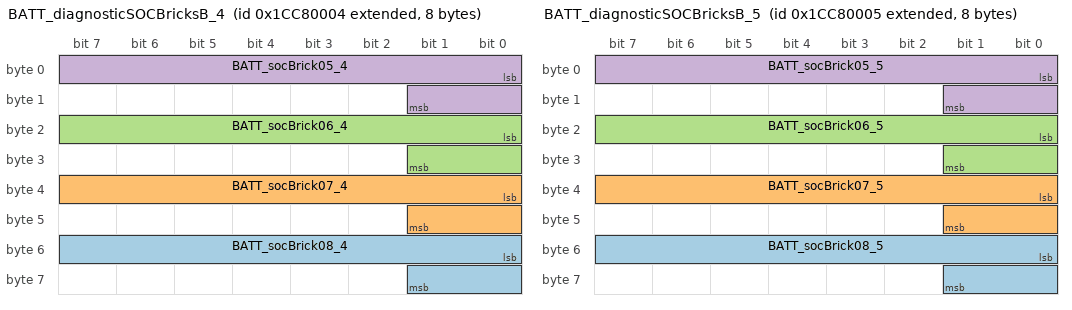
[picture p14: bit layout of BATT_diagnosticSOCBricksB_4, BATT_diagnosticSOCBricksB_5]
BO_ 2630352900 BATT_diagnosticSOCBricksB_4: 8 Battery
 SG_ BATT_socBrick08_4 : 48|10@1+ (0.1,0) [0|102.3] "%" Host
 SG_ BATT_socBrick07_4 : 32|10@1+ (0.1,0) [0|102.3] "%" Host
 SG_ BATT_socBrick06_4 : 16|10@1+ (0.1,0) [0|102.3] "%" Host
 SG_ BATT_socBrick05_4 : 0|10@1+ (0.1,0) [0|102.3] "%" Host

BO_ 2630352901 BATT_diagnosticSOCBricksB_5: 8 Battery
 SG_ BATT_socBrick08_5 : 48|10@1+ (0.1,0) [0|102.3] "%" Host
 SG_ BATT_socBrick07_5 : 32|10@1+ (0.1,0) [0|102.3] "%" Host
 SG_ BATT_socBrick06_5 : 16|10@1+ (0.1,0) [0|102.3] "%" Host
 SG_ BATT_socBrick05_5 : 0|10@1+ (0.1,0) [0|102.3] "%" Host

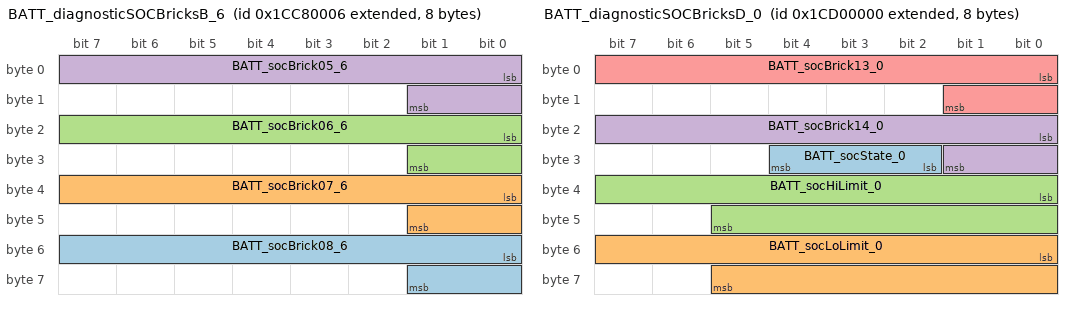
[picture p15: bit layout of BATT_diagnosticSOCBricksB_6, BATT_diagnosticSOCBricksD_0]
BO_ 2630352902 BATT_diagnosticSOCBricksB_6: 8 Battery
 SG_ BATT_socBrick08_6 : 48|10@1+ (0.1,0) [0|102.3] "%" Host
 SG_ BATT_socBrick07_6 : 32|10@1+ (0.1,0) [0|102.3] "%" Host
 SG_ BATT_socBrick06_6 : 16|10@1+ (0.1,0) [0|102.3] "%" Host
 SG_ BATT_socBrick05_6 : 0|10@1+ (0.1,0) [0|102.3] "%" Host

BO_ 2630352903 BATT_diagnosticSOCBricksB_7: 8 Battery
 SG_ BATT_socBrick08_7 : 48|10@1+ (0.1,0) [0|102.3] "%" Host
 SG_ BATT_socBrick07_7 : 32|10@1+ (0.1,0) [0|102.3] "%" Host
 SG_ BATT_socBrick06_7 : 16|10@1+ (0.1,0) [0|102.3] "%" Host
 SG_ BATT_socBrick05_7 : 0|10@1+ (0.1,0) [0|102.3] "%" Host

BO_ 2630615040 BATT_diagnosticSOCBricksC_0: 8 Battery
 SG_ BATT_socBrick12_0 : 48|10@1+ (0.1,0) [0|102.3] "%" Host
 SG_ BATT_socBrick11_0 : 32|10@1+ (0.1,0) [0|102.3] "%" Host
 SG_ BATT_socBrick09_0 : 0|10@1+ (0.1,0) [0|102.3] "%" Host
 SG_ BATT_socBrick10_0 : 16|10@1+ (0.1,0) [0|102.3] "%" Host

BO_ 2630615041 BATT_diagnosticSOCBricksC_1: 8 Battery
 SG_ BATT_socBrick12_1 : 48|10@1+ (0.1,0) [0|102.3] "%" Host
 SG_ BATT_socBrick11_1 : 32|10@1+ (0.1,0) [0|102.3] "%" Host
 SG_ BATT_socBrick09_1 : 0|10@1+ (0.1,0) [0|102.3] "%" Host
 SG_ BATT_socBrick10_1 : 16|10@1+ (0.1,0) [0|102.3] "%" Host

BO_ 2630615042 BATT_diagnosticSOCBricksC_2: 8 Battery
 SG_ BATT_socBrick12_2 : 48|10@1+ (0.1,0) [0|102.3] "%" Host
 SG_ BATT_socBrick11_2 : 32|10@1+ (0.1,0) [0|102.3] "%" Host
 SG_ BATT_socBrick09_2 : 0|10@1+ (0.1,0) [0|102.3] "%" Host
 SG_ BATT_socBrick10_2 : 16|10@1+ (0.1,0) [0|102.3] "%" Host

BO_ 2630615043 BATT_diagnosticSOCBricksC_3: 8 Battery
 SG_ BATT_socBrick12_3 : 48|10@1+ (0.1,0) [0|102.3] "%" Host
 SG_ BATT_socBrick11_3 : 32|10@1+ (0.1,0) [0|102.3] "%" Host
 SG_ BATT_socBrick09_3 : 0|10@1+ (0.1,0) [0|102.3] "%" Host
 SG_ BATT_socBrick10_3 : 16|10@1+ (0.1,0) [0|102.3] "%" Host

BO_ 2630615044 BATT_diagnosticSOCBricksC_4: 8 Battery
 SG_ BATT_socBrick12_4 : 48|10@1+ (0.1,0) [0|102.3] "%" Host
 SG_ BATT_socBrick11_4 : 32|10@1+ (0.1,0) [0|102.3] "%" Host
 SG_ BATT_socBrick09_4 : 0|10@1+ (0.1,0) [0|102.3] "%" Host
 SG_ BATT_socBrick10_4 : 16|10@1+ (0.1,0) [0|102.3] "%" Host

BO_ 2630615045 BATT_diagnosticSOCBricksC_5: 8 Battery
 SG_ BATT_socBrick12_5 : 48|10@1+ (0.1,0) [0|102.3] "%" Host
 SG_ BATT_socBrick11_5 : 32|10@1+ (0.1,0) [0|102.3] "%" Host
 SG_ BATT_socBrick09_5 : 0|10@1+ (0.1,0) [0|102.3] "%" Host
 SG_ BATT_socBrick10_5 : 16|10@1+ (0.1,0) [0|102.3] "%" Host

BO_ 2630615046 BATT_diagnosticSOCBricksC_6: 8 Battery
 SG_ BATT_socBrick12_6 : 48|10@1+ (0.1,0) [0|102.3] "%" Host
 SG_ BATT_socBrick11_6 : 32|10@1+ (0.1,0) [0|102.3] "%" Host
 SG_ BATT_socBrick09_6 : 0|10@1+ (0.1,0) [0|102.3] "%" Host
 SG_ BATT_socBrick10_6 : 16|10@1+ (0.1,0) [0|102.3] "%" Host

BO_ 2630615047 BATT_diagnosticSOCBricksC_7: 8 Battery
 SG_ BATT_socBrick12_7 : 48|10@1+ (0.1,0) [0|102.3] "%" Host
 SG_ BATT_socBrick11_7 : 32|10@1+ (0.1,0) [0|102.3] "%" Host
 SG_ BATT_socBrick09_7 : 0|10@1+ (0.1,0) [0|102.3] "%" Host
 SG_ BATT_socBrick10_7 : 16|10@1+ (0.1,0) [0|102.3] "%" Host

BO_ 2630877184 BATT_diagnosticSOCBricksD_0: 8 Battery
 SG_ BATT_socState_0 : 26|3@1+ (1,0) [0|7] "" Host
 SG_ BATT_socLoLimit_0 : 48|14@1+ (1,0) [0|16383] "" Host
 SG_ BATT_socHiLimit_0 : 32|14@1+ (1,0) [0|16383] "" Host
 SG_ BATT_socBrick14_0 : 16|10@1+ (0.1,0) [0|102.3] "%" Host
 SG_ BATT_socBrick13_0 : 0|10@1+ (0.1,0) [0|102.3] "%" Host

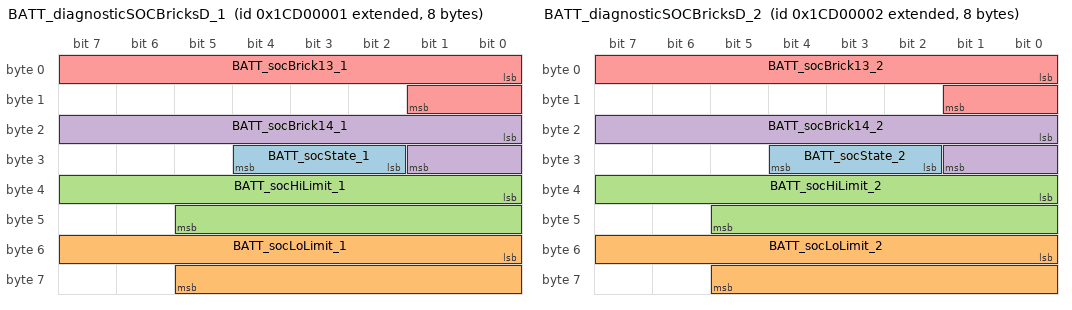
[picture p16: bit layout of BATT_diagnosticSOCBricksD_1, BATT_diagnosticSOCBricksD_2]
BO_ 2630877185 BATT_diagnosticSOCBricksD_1: 8 Battery
 SG_ BATT_socState_1 : 26|3@1+ (1,0) [0|7] "" Host
 SG_ BATT_socLoLimit_1 : 48|14@1+ (1,0) [0|16383] "" Host
 SG_ BATT_socHiLimit_1 : 32|14@1+ (1,0) [0|16383] "" Host
 SG_ BATT_socBrick14_1 : 16|10@1+ (0.1,0) [0|102.3] "%" Host
 SG_ BATT_socBrick13_1 : 0|10@1+ (0.1,0) [0|102.3] "%" Host

BO_ 2630877186 BATT_diagnosticSOCBricksD_2: 8 Battery
 SG_ BATT_socState_2 : 26|3@1+ (1,0) [0|7] "" Host
 SG_ BATT_socLoLimit_2 : 48|14@1+ (1,0) [0|16383] "" Host
 SG_ BATT_socHiLimit_2 : 32|14@1+ (1,0) [0|16383] "" Host
 SG_ BATT_socBrick14_2 : 16|10@1+ (0.1,0) [0|102.3] "%" Host
 SG_ BATT_socBrick13_2 : 0|10@1+ (0.1,0) [0|102.3] "%" Host

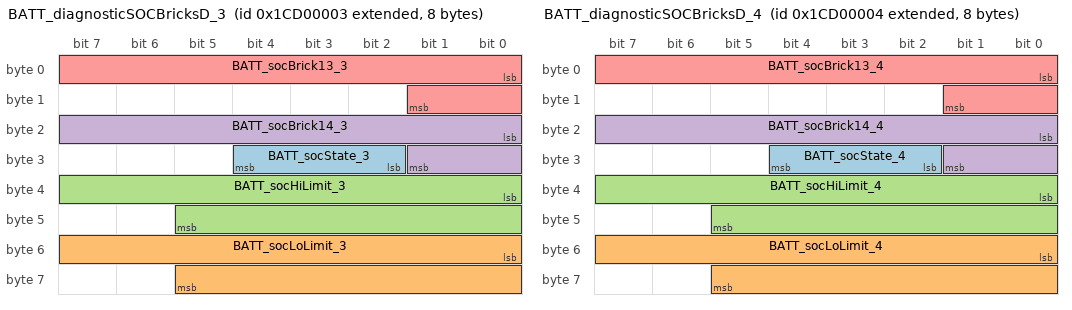
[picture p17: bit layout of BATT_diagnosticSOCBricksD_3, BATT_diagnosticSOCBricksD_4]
BO_ 2630877187 BATT_diagnosticSOCBricksD_3: 8 Battery
 SG_ BATT_socState_3 : 26|3@1+ (1,0) [0|7] "" Host
 SG_ BATT_socLoLimit_3 : 48|14@1+ (1,0) [0|16383] "" Host
 SG_ BATT_socHiLimit_3 : 32|14@1+ (1,0) [0|16383] "" Host
 SG_ BATT_socBrick14_3 : 16|10@1+ (0.1,0) [0|102.3] "%" Host
 SG_ BATT_socBrick13_3 : 0|10@1+ (0.1,0) [0|102.3] "%" Host

BO_ 2630877188 BATT_diagnosticSOCBricksD_4: 8 Battery
 SG_ BATT_socState_4 : 26|3@1+ (1,0) [0|7] "" Host
 SG_ BATT_socLoLimit_4 : 48|14@1+ (1,0) [0|16383] "" Host
 SG_ BATT_socHiLimit_4 : 32|14@1+ (1,0) [0|16383] "" Host
 SG_ BATT_socBrick14_4 : 16|10@1+ (0.1,0) [0|102.3] "%" Host
 SG_ BATT_socBrick13_4 : 0|10@1+ (0.1,0) [0|102.3] "%" Host

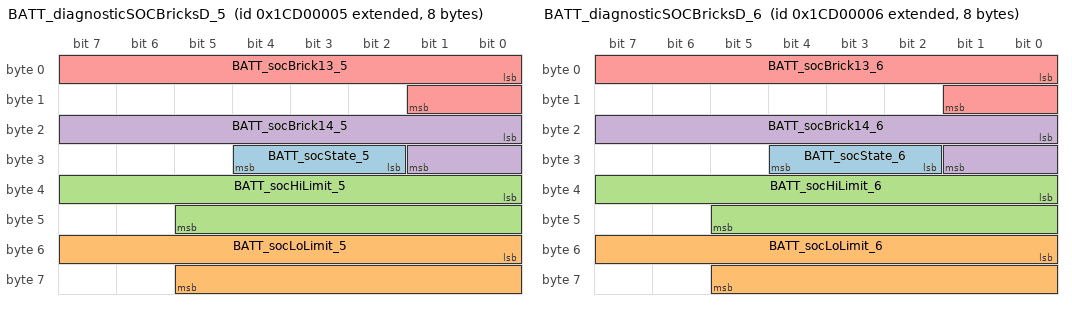
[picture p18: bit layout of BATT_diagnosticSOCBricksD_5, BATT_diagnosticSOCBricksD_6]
BO_ 2630877189 BATT_diagnosticSOCBricksD_5: 8 Battery
 SG_ BATT_socState_5 : 26|3@1+ (1,0) [0|7] "" Host
 SG_ BATT_socLoLimit_5 : 48|14@1+ (1,0) [0|16383] "" Host
 SG_ BATT_socHiLimit_5 : 32|14@1+ (1,0) [0|16383] "" Host
 SG_ BATT_socBrick14_5 : 16|10@1+ (0.1,0) [0|102.3] "%" Host
 SG_ BATT_socBrick13_5 : 0|10@1+ (0.1,0) [0|102.3] "%" Host

BO_ 2630877190 BATT_diagnosticSOCBricksD_6: 8 Battery
 SG_ BATT_socState_6 : 26|3@1+ (1,0) [0|7] "" Host
 SG_ BATT_socLoLimit_6 : 48|14@1+ (1,0) [0|16383] "" Host
 SG_ BATT_socHiLimit_6 : 32|14@1+ (1,0) [0|16383] "" Host
 SG_ BATT_socBrick14_6 : 16|10@1+ (0.1,0) [0|102.3] "%" Host
 SG_ BATT_socBrick13_6 : 0|10@1+ (0.1,0) [0|102.3] "%" Host

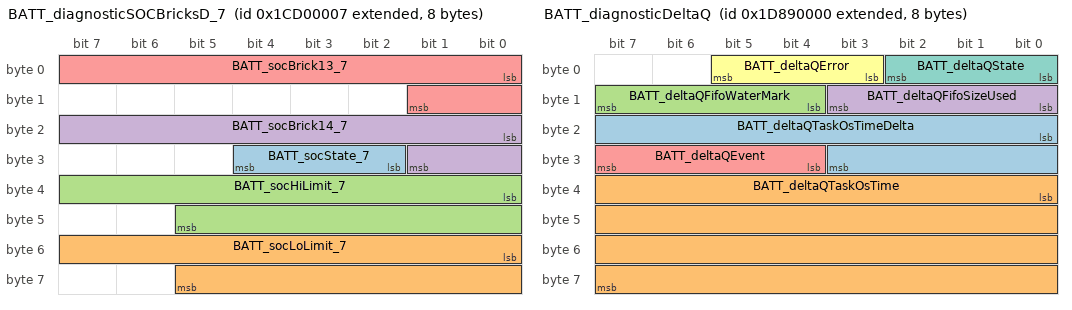
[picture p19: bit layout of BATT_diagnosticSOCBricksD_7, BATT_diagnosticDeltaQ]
BO_ 2630877191 BATT_diagnosticSOCBricksD_7: 8 Battery
 SG_ BATT_socState_7 : 26|3@1+ (1,0) [0|7] "" Host
 SG_ BATT_socLoLimit_7 : 48|14@1+ (1,0) [0|16383] "" Host
 SG_ BATT_socHiLimit_7 : 32|14@1+ (1,0) [0|16383] "" Host
 SG_ BATT_socBrick14_7 : 16|10@1+ (0.1,0) [0|102.3] "%" Host
 SG_ BATT_socBrick13_7 : 0|10@1+ (0.1,0) [0|102.3] "%" Host

BO_ 2642411520 BATT_taskStackDiag_0: 8 Battery
 SG_ BATT_canTaskStack_0 : 48|8@1+ (1,0) [0|100] "%" Host
 SG_ BATT_afeTaskStack_0 : 40|8@1+ (1,0) [0|100] "%" Host
 SG_ BATT_nvmTaskStack_0 : 32|8@1+ (1,0) [0|100] "%" Host
 SG_ BATT_10hzTaskStack_0 : 16|8@1+ (1,0) [0|100] "%" Host
 SG_ BATT_100hzTaskStack_0 : 8|8@1+ (1,0) [0|100] "%" Host
 SG_ BATT_1000hzTaskStack_0 : 0|8@1+ (1,0) [0|100] "%" Host

BO_ 2642411521 BATT_taskStackDiag_1: 8 Battery
 SG_ BATT_canTaskStack_1 : 48|8@1+ (1,0) [0|100] "%" Host
 SG_ BATT_afeTaskStack_1 : 40|8@1+ (1,0) [0|100] "%" Host
 SG_ BATT_nvmTaskStack_1 : 32|8@1+ (1,0) [0|100] "%" Host
 SG_ BATT_10hzTaskStack_1 : 16|8@1+ (1,0) [0|100] "%" Host
 SG_ BATT_100hzTaskStack_1 : 8|8@1+ (1,0) [0|100] "%" Host
 SG_ BATT_1000hzTaskStack_1 : 0|8@1+ (1,0) [0|100] "%" Host

BO_ 2642411522 BATT_taskStackDiag_2: 8 Battery
 SG_ BATT_canTaskStack_2 : 48|8@1+ (1,0) [0|100] "%" Host
 SG_ BATT_afeTaskStack_2 : 40|8@1+ (1,0) [0|100] "%" Host
 SG_ BATT_nvmTaskStack_2 : 32|8@1+ (1,0) [0|100] "%" Host
 SG_ BATT_10hzTaskStack_2 : 16|8@1+ (1,0) [0|100] "%" Host
 SG_ BATT_100hzTaskStack_2 : 8|8@1+ (1,0) [0|100] "%" Host
 SG_ BATT_1000hzTaskStack_2 : 0|8@1+ (1,0) [0|100] "%" Host

BO_ 2642411523 BATT_taskStackDiag_3: 8 Battery
 SG_ BATT_canTaskStack_3 : 48|8@1+ (1,0) [0|100] "%" Host
 SG_ BATT_afeTaskStack_3 : 40|8@1+ (1,0) [0|100] "%" Host
 SG_ BATT_nvmTaskStack_3 : 32|8@1+ (1,0) [0|100] "%" Host
 SG_ BATT_10hzTaskStack_3 : 16|8@1+ (1,0) [0|100] "%" Host
 SG_ BATT_100hzTaskStack_3 : 8|8@1+ (1,0) [0|100] "%" Host
 SG_ BATT_1000hzTaskStack_3 : 0|8@1+ (1,0) [0|100] "%" Host

BO_ 2642411524 BATT_taskStackDiag_4: 8 Battery
 SG_ BATT_canTaskStack_4 : 48|8@1+ (1,0) [0|100] "%" Host
 SG_ BATT_afeTaskStack_4 : 40|8@1+ (1,0) [0|100] "%" Host
 SG_ BATT_nvmTaskStack_4 : 32|8@1+ (1,0) [0|100] "%" Host
 SG_ BATT_10hzTaskStack_4 : 16|8@1+ (1,0) [0|100] "%" Host
 SG_ BATT_100hzTaskStack_4 : 8|8@1+ (1,0) [0|100] "%" Host
 SG_ BATT_1000hzTaskStack_4 : 0|8@1+ (1,0) [0|100] "%" Host

BO_ 2642411525 BATT_taskStackDiag_5: 8 Battery
 SG_ BATT_canTaskStack_5 : 48|8@1+ (1,0) [0|100] "%" Host
 SG_ BATT_afeTaskStack_5 : 40|8@1+ (1,0) [0|100] "%" Host
 SG_ BATT_nvmTaskStack_5 : 32|8@1+ (1,0) [0|100] "%" Host
 SG_ BATT_10hzTaskStack_5 : 16|8@1+ (1,0) [0|100] "%" Host
 SG_ BATT_100hzTaskStack_5 : 8|8@1+ (1,0) [0|100] "%" Host
 SG_ BATT_1000hzTaskStack_5 : 0|8@1+ (1,0) [0|100] "%" Host

BO_ 2642411526 BATT_taskStackDiag_6: 8 Battery
 SG_ BATT_canTaskStack_6 : 48|8@1+ (1,0) [0|100] "%" Host
 SG_ BATT_afeTaskStack_6 : 40|8@1+ (1,0) [0|100] "%" Host
 SG_ BATT_nvmTaskStack_6 : 32|8@1+ (1,0) [0|100] "%" Host
 SG_ BATT_10hzTaskStack_6 : 16|8@1+ (1,0) [0|100] "%" Host
 SG_ BATT_100hzTaskStack_6 : 8|8@1+ (1,0) [0|100] "%" Host
 SG_ BATT_1000hzTaskStack_6 : 0|8@1+ (1,0) [0|100] "%" Host

BO_ 2642411527 BATT_taskStackDiag_7: 8 Battery
 SG_ BATT_canTaskStack_7 : 48|8@1+ (1,0) [0|100] "%" Host
 SG_ BATT_afeTaskStack_7 : 40|8@1+ (1,0) [0|100] "%" Host
 SG_ BATT_nvmTaskStack_7 : 32|8@1+ (1,0) [0|100] "%" Host
 SG_ BATT_10hzTaskStack_7 : 16|8@1+ (1,0) [0|100] "%" Host
 SG_ BATT_100hzTaskStack_7 : 8|8@1+ (1,0) [0|100] "%" Host
 SG_ BATT_1000hzTaskStack_7 : 0|8@1+ (1,0) [0|100] "%" Host

BO_ 2642935808 BATT_diagnosticCan_0: 4 Battery
 SG_ BATT_canTXFifoSizeUsed_0 : 24|8@1+ (1,0) [0|255] "" Host
 SG_ BATT_canRXFifoSizeUsed_0 : 8|8@1+ (1,0) [0|255] "" Host
 SG_ BATT_canTXFifoWaterMark_0 : 16|8@1+ (1,0) [0|65535] "" Host
 SG_ BATT_canRXFifoWaterMark_0 : 0|8@1+ (1,0) [0|255] "" Host

BO_ 2642935809 BATT_diagnosticCan_1: 4 Battery
 SG_ BATT_canTXFifoSizeUsed_1 : 24|8@1+ (1,0) [0|255] "" Host
 SG_ BATT_canRXFifoSizeUsed_1 : 8|8@1+ (1,0) [0|255] "" Host
 SG_ BATT_canTXFifoWaterMark_1 : 16|8@1+ (1,0) [0|65535] "" Host
 SG_ BATT_canRXFifoWaterMark_1 : 0|8@1+ (1,0) [0|255] "" Host

BO_ 2642935810 BATT_diagnosticCan_2: 4 Battery
 SG_ BATT_canTXFifoSizeUsed_2 : 24|8@1+ (1,0) [0|255] "" Host
 SG_ BATT_canRXFifoSizeUsed_2 : 8|8@1+ (1,0) [0|255] "" Host
 SG_ BATT_canTXFifoWaterMark_2 : 16|8@1+ (1,0) [0|65535] "" Host
 SG_ BATT_canRXFifoWaterMark_2 : 0|8@1+ (1,0) [0|255] "" Host

BO_ 2642935811 BATT_diagnosticCan_3: 4 Battery
 SG_ BATT_canTXFifoSizeUsed_3 : 24|8@1+ (1,0) [0|255] "" Host
 SG_ BATT_canRXFifoSizeUsed_3 : 8|8@1+ (1,0) [0|255] "" Host
 SG_ BATT_canTXFifoWaterMark_3 : 16|8@1+ (1,0) [0|65535] "" Host
 SG_ BATT_canRXFifoWaterMark_3 : 0|8@1+ (1,0) [0|255] "" Host

BO_ 2642935812 BATT_diagnosticCan_4: 4 Battery
 SG_ BATT_canTXFifoSizeUsed_4 : 24|8@1+ (1,0) [0|255] "" Host
 SG_ BATT_canRXFifoSizeUsed_4 : 8|8@1+ (1,0) [0|255] "" Host
 SG_ BATT_canTXFifoWaterMark_4 : 16|8@1+ (1,0) [0|65535] "" Host
 SG_ BATT_canRXFifoWaterMark_4 : 0|8@1+ (1,0) [0|255] "" Host

BO_ 2642935813 BATT_diagnosticCan_5: 4 Battery
 SG_ BATT_canTXFifoSizeUsed_5 : 24|8@1+ (1,0) [0|255] "" Host
 SG_ BATT_canRXFifoSizeUsed_5 : 8|8@1+ (1,0) [0|255] "" Host
 SG_ BATT_canTXFifoWaterMark_5 : 16|8@1+ (1,0) [0|65535] "" Host
 SG_ BATT_canRXFifoWaterMark_5 : 0|8@1+ (1,0) [0|255] "" Host

BO_ 2642935814 BATT_diagnosticCan_6: 4 Battery
 SG_ BATT_canTXFifoSizeUsed_6 : 24|8@1+ (1,0) [0|255] "" Host
 SG_ BATT_canRXFifoSizeUsed_6 : 8|8@1+ (1,0) [0|255] "" Host
 SG_ BATT_canTXFifoWaterMark_6 : 16|8@1+ (1,0) [0|65535] "" Host
 SG_ BATT_canRXFifoWaterMark_6 : 0|8@1+ (1,0) [0|255] "" Host

BO_ 2642935815 BATT_diagnosticCan_7: 4 Battery
 SG_ BATT_canTXFifoSizeUsed_7 : 24|8@1+ (1,0) [0|255] "" Host
 SG_ BATT_canRXFifoSizeUsed_7 : 8|8@1+ (1,0) [0|255] "" Host
 SG_ BATT_canTXFifoWaterMark_7 : 16|8@1+ (1,0) [0|65535] "" Host
 SG_ BATT_canRXFifoWaterMark_7 : 0|8@1+ (1,0) [0|255] "" Host

BO_ 2643001344 BATT_diagnosticDeltaQ: 8 Battery
 SG_ BATT_deltaQTaskOsTimeDelta : 16|12@1+ (1,0) [0|4095] "" Host
 SG_ BATT_deltaQTaskOsTime : 32|32@1+ (1,0) [0|4294967295] "" Host
 SG_ BATT_deltaQFifoWaterMark : 12|4@1+ (1,0) [0|15] "" Host
 SG_ BATT_deltaQFifoSizeUsed : 8|4@1+ (1,0) [0|15] "" Host
 SG_ BATT_deltaQEvent : 28|4@1+ (1,0) [0|15] "" Host
 SG_ BATT_deltaQError : 3|3@1+ (1,0) [0|3] "" Host
 SG_ BATT_deltaQState : 0|3@1+ (1,0) [0|3] "" Host

BO_ 2671771648 BATT_boardADC_1_0: 6 Battery
 SG_ BATT_boardADC_LOAD_0 : 32|16@1- (0.01,0) [0|100] "V" Host
 SG_ BATT_boardADC_COMMON_DRAIN_0 : 16|16@1- (0.01,0) [0|100] "V" Host
 SG_ BATT_boardADC_PACK_0 : 0|16@1- (0.01,0) [0|100] "V" Host

BO_ 2671771649 BATT_boardADC_1_1: 6 Battery
 SG_ BATT_boardADC_LOAD_1 : 32|16@1- (0.01,0) [0|100] "V" Host
 SG_ BATT_boardADC_COMMON_DRAIN_1 : 16|16@1- (0.01,0) [0|100] "V" Host
 SG_ BATT_boardADC_PACK_1 : 0|16@1- (0.01,0) [0|100] "V" Host

BO_ 2671771650 BATT_boardADC_1_2: 6 Battery
 SG_ BATT_boardADC_LOAD_2 : 32|16@1- (0.01,0) [0|100] "V" Host
 SG_ BATT_boardADC_COMMON_DRAIN_2 : 16|16@1- (0.01,0) [0|100] "V" Host
 SG_ BATT_boardADC_PACK_2 : 0|16@1- (0.01,0) [0|100] "V" Host

BO_ 2671771651 BATT_boardADC_1_3: 6 Battery
 SG_ BATT_boardADC_LOAD_3 : 32|16@1- (0.01,0) [0|100] "V" Host
 SG_ BATT_boardADC_COMMON_DRAIN_3 : 16|16@1- (0.01,0) [0|100] "V" Host
 SG_ BATT_boardADC_PACK_3 : 0|16@1- (0.01,0) [0|100] "V" Host

BO_ 2671771652 BATT_boardADC_1_4: 6 Battery
 SG_ BATT_boardADC_LOAD_4 : 32|16@1- (0.01,0) [0|100] "V" Host
 SG_ BATT_boardADC_COMMON_DRAIN_4 : 16|16@1- (0.01,0) [0|100] "V" Host
 SG_ BATT_boardADC_PACK_4 : 0|16@1- (0.01,0) [0|100] "V" Host

BO_ 2671771653 BATT_boardADC_1_5: 6 Battery
 SG_ BATT_boardADC_LOAD_5 : 32|16@1- (0.01,0) [0|100] "V" Host
 SG_ BATT_boardADC_COMMON_DRAIN_5 : 16|16@1- (0.01,0) [0|100] "V" Host
 SG_ BATT_boardADC_PACK_5 : 0|16@1- (0.01,0) [0|100] "V" Host

BO_ 2671771654 BATT_boardADC_1_6: 6 Battery
 SG_ BATT_boardADC_LOAD_6 : 32|16@1- (0.01,0) [0|100] "V" Host
 SG_ BATT_boardADC_COMMON_DRAIN_6 : 16|16@1- (0.01,0) [0|100] "V" Host
 SG_ BATT_boardADC_PACK_6 : 0|16@1- (0.01,0) [0|100] "V" Host

BO_ 2671771655 BATT_boardADC_1_7: 6 Battery
 SG_ BATT_boardADC_LOAD_7 : 32|16@1- (0.01,0) [0|100] "V" Host
 SG_ BATT_boardADC_COMMON_DRAIN_7 : 16|16@1- (0.01,0) [0|100] "V" Host
 SG_ BATT_boardADC_PACK_7 : 0|16@1- (0.01,0) [0|100] "V" Host

BO_ 2672033792 BATT_boardADC_2_0: 6 Battery
 SG_ BATT_boardADC_12V_0 : 16|16@1- (0.01,0) [0|100] "V" Host
 SG_ BATT_boardADC_5V_0 : 0|16@1- (0.01,0) [0|100] "V" Host
 SG_ BATT_boardADC_3V3_0 : 32|16@1- (0.01,0) [0|100] "V" Host

BO_ 2672033793 BATT_boardADC_2_1: 6 Battery
 SG_ BATT_boardADC_12V_1 : 16|16@1- (0.01,0) [0|100] "V" Host
 SG_ BATT_boardADC_5V_1 : 0|16@1- (0.01,0) [0|100] "V" Host
 SG_ BATT_boardADC_3V3_1 : 32|16@1- (0.01,0) [0|100] "V" Host

BO_ 2672033794 BATT_boardADC_2_2: 6 Battery
 SG_ BATT_boardADC_12V_2 : 16|16@1- (0.01,0) [0|100] "V" Host
 SG_ BATT_boardADC_5V_2 : 0|16@1- (0.01,0) [0|100] "V" Host
 SG_ BATT_boardADC_3V3_2 : 32|16@1- (0.01,0) [0|100] "V" Host

BO_ 2672033795 BATT_boardADC_2_3: 6 Battery
 SG_ BATT_boardADC_12V_3 : 16|16@1- (0.01,0) [0|100] "V" Host
 SG_ BATT_boardADC_5V_3 : 0|16@1- (0.01,0) [0|100] "V" Host
 SG_ BATT_boardADC_3V3_3 : 32|16@1- (0.01,0) [0|100] "V" Host

BO_ 2672033796 BATT_boardADC_2_4: 6 Battery
 SG_ BATT_boardADC_12V_4 : 16|16@1- (0.01,0) [0|100] "V" Host
 SG_ BATT_boardADC_5V_4 : 0|16@1- (0.01,0) [0|100] "V" Host
 SG_ BATT_boardADC_3V3_4 : 32|16@1- (0.01,0) [0|100] "V" Host

BO_ 2672033797 BATT_boardADC_2_5: 6 Battery
 SG_ BATT_boardADC_12V_5 : 16|16@1- (0.01,0) [0|100] "V" Host
 SG_ BATT_boardADC_5V_5 : 0|16@1- (0.01,0) [0|100] "V" Host
 SG_ BATT_boardADC_3V3_5 : 32|16@1- (0.01,0) [0|100] "V" Host

BO_ 2672033798 BATT_boardADC_2_6: 6 Battery
 SG_ BATT_boardADC_12V_6 : 16|16@1- (0.01,0) [0|100] "V" Host
 SG_ BATT_boardADC_5V_6 : 0|16@1- (0.01,0) [0|100] "V" Host
 SG_ BATT_boardADC_3V3_6 : 32|16@1- (0.01,0) [0|100] "V" Host

BO_ 2672033799 BATT_boardADC_2_7: 6 Battery
 SG_ BATT_boardADC_12V_7 : 16|16@1- (0.01,0) [0|100] "V" Host
 SG_ BATT_boardADC_5V_7 : 0|16@1- (0.01,0) [0|100] "V" Host
 SG_ BATT_boardADC_3V3_7 : 32|16@1- (0.01,0) [0|100] "V" Host

BO_ 2672295936 BATT_boardADC_3_0: 6 Battery
 SG_ BATT_boardADC_SHUNT_TEMP_0 : 16|16@1- (0.01,0) [0|100] "V" Host
 SG_ BATT_boardADC_FET_TEMP_0 : 0|16@1- (0.01,0) [0|100] "V" Host
 SG_ BATT_boardADC_AMB_TEMP_0 : 32|16@1- (0.01,0) [0|100] "V" Host

BO_ 2672295937 BATT_boardADC_3_1: 6 Battery
 SG_ BATT_boardADC_SHUNT_TEMP_1 : 16|16@1- (0.01,0) [0|100] "V" Host
 SG_ BATT_boardADC_FET_TEMP_1 : 0|16@1- (0.01,0) [0|100] "V" Host
 SG_ BATT_boardADC_AMB_TEMP_1 : 32|16@1- (0.01,0) [0|100] "V" Host

BO_ 2672295938 BATT_boardADC_3_2: 6 Battery
 SG_ BATT_boardADC_SHUNT_TEMP_2 : 16|16@1- (0.01,0) [0|100] "V" Host
 SG_ BATT_boardADC_FET_TEMP_2 : 0|16@1- (0.01,0) [0|100] "V" Host
 SG_ BATT_boardADC_AMB_TEMP_2 : 32|16@1- (0.01,0) [0|100] "V" Host

BO_ 2672295939 BATT_boardADC_3_3: 6 Battery
 SG_ BATT_boardADC_SHUNT_TEMP_3 : 16|16@1- (0.01,0) [0|100] "V" Host
 SG_ BATT_boardADC_FET_TEMP_3 : 0|16@1- (0.01,0) [0|100] "V" Host
 SG_ BATT_boardADC_AMB_TEMP_3 : 32|16@1- (0.01,0) [0|100] "V" Host

BO_ 2672295940 BATT_boardADC_3_4: 6 Battery
 SG_ BATT_boardADC_SHUNT_TEMP_4 : 16|16@1- (0.01,0) [0|100] "V" Host
 SG_ BATT_boardADC_FET_TEMP_4 : 0|16@1- (0.01,0) [0|100] "V" Host
 SG_ BATT_boardADC_AMB_TEMP_4 : 32|16@1- (0.01,0) [0|100] "V" Host

BO_ 2672295941 BATT_boardADC_3_5: 6 Battery
 SG_ BATT_boardADC_SHUNT_TEMP_5 : 16|16@1- (0.01,0) [0|100] "V" Host
 SG_ BATT_boardADC_FET_TEMP_5 : 0|16@1- (0.01,0) [0|100] "V" Host
 SG_ BATT_boardADC_AMB_TEMP_5 : 32|16@1- (0.01,0) [0|100] "V" Host

BO_ 2672295942 BATT_boardADC_3_6: 6 Battery
 SG_ BATT_boardADC_SHUNT_TEMP_6 : 16|16@1- (0.01,0) [0|100] "V" Host
 SG_ BATT_boardADC_FET_TEMP_6 : 0|16@1- (0.01,0) [0|100] "V" Host
 SG_ BATT_boardADC_AMB_TEMP_6 : 32|16@1- (0.01,0) [0|100] "V" Host

BO_ 2672295943 BATT_boardADC_3_7: 6 Battery
 SG_ BATT_boardADC_SHUNT_TEMP_7 : 16|16@1- (0.01,0) [0|100] "V" Host
 SG_ BATT_boardADC_FET_TEMP_7 : 0|16@1- (0.01,0) [0|100] "V" Host
 SG_ BATT_boardADC_AMB_TEMP_7 : 32|16@1- (0.01,0) [0|100] "V" Host

CM_ BO_ 2626158596 "Voltages of bricks 5-8";
CM_ SG_ 2626158596 BATT_vBrick06_4 "Voltage of brick 6";
CM_ SG_ 2626158596 BATT_vBrick07_4 "Voltage of brick 7";
CM_ SG_ 2626158596 BATT_vBrick05_4 "Voltage of brick 5";
CM_ SG_ 2626158596 BATT_vBrick08_4 "Voltage of brick 8";
CM_ BO_ 2626158597 "Voltages of bricks 5-8";
CM_ SG_ 2626158597 BATT_vBrick06_5 "Voltage of brick 6";
CM_ SG_ 2626158597 BATT_vBrick07_5 "Voltage of brick 7";
CM_ SG_ 2626158597 BATT_vBrick05_5 "Voltage of brick 5";
CM_ SG_ 2626158597 BATT_vBrick08_5 "Voltage of brick 8";
CM_ BO_ 2626158598 "Voltages of bricks 5-8";
CM_ SG_ 2626158598 BATT_vBrick06_6 "Voltage of brick 6";
CM_ SG_ 2626158598 BATT_vBrick07_6 "Voltage of brick 7";
CM_ SG_ 2626158598 BATT_vBrick05_6 "Voltage of brick 5";
CM_ SG_ 2626158598 BATT_vBrick08_6 "Voltage of brick 8";
CM_ BO_ 2626158599 "Voltages of bricks 5-8";
CM_ SG_ 2626158599 BATT_vBrick06_7 "Voltage of brick 6";
CM_ SG_ 2626158599 BATT_vBrick07_7 "Voltage of brick 7";
CM_ SG_ 2626158599 BATT_vBrick05_7 "Voltage of brick 5";
CM_ SG_ 2626158599 BATT_vBrick08_7 "Voltage of brick 8";
CM_ BO_ 2626420736 "Voltages of bricks 9-12";
CM_ SG_ 2626420736 BATT_vBrick12_0 "Voltage of brick 12";
CM_ SG_ 2626420736 BATT_vBrick11_0 "Voltage of brick 11";
CM_ SG_ 2626420736 BATT_vBrick10_0 "Voltage of brick 10";
CM_ SG_ 2626420736 BATT_vBrick09_0 "Voltage of brick 9";
CM_ BO_ 2626420737 "Voltages of bricks 9-12";
CM_ SG_ 2626420737 BATT_vBrick12_1 "Voltage of brick 12";
CM_ SG_ 2626420737 BATT_vBrick11_1 "Voltage of brick 11";
CM_ SG_ 2626420737 BATT_vBrick10_1 "Voltage of brick 10";
CM_ SG_ 2626420737 BATT_vBrick09_1 "Voltage of brick 9";
CM_ BO_ 2626420738 "Voltages of bricks 9-12";
CM_ SG_ 2626420738 BATT_vBrick12_2 "Voltage of brick 12";
CM_ SG_ 2626420738 BATT_vBrick11_2 "Voltage of brick 11";
CM_ SG_ 2626420738 BATT_vBrick10_2 "Voltage of brick 10";
CM_ SG_ 2626420738 BATT_vBrick09_2 "Voltage of brick 9";
CM_ BO_ 2626420739 "Voltages of bricks 9-12";
CM_ SG_ 2626420739 BATT_vBrick12_3 "Voltage of brick 12";
CM_ SG_ 2626420739 BATT_vBrick11_3 "Voltage of brick 11";
CM_ SG_ 2626420739 BATT_vBrick10_3 "Voltage of brick 10";
CM_ SG_ 2626420739 BATT_vBrick09_3 "Voltage of brick 9";
CM_ BO_ 2626420740 "Voltages of bricks 9-12";
CM_ SG_ 2626420740 BATT_vBrick12_4 "Voltage of brick 12";
CM_ SG_ 2626420740 BATT_vBrick11_4 "Voltage of brick 11";
CM_ SG_ 2626420740 BATT_vBrick10_4 "Voltage of brick 10";
CM_ SG_ 2626420740 BATT_vBrick09_4 "Voltage of brick 9";
CM_ BO_ 2626420741 "Voltages of bricks 9-12";
CM_ SG_ 2626420741 BATT_vBrick12_5 "Voltage of brick 12";
CM_ SG_ 2626420741 BATT_vBrick11_5 "Voltage of brick 11";
CM_ SG_ 2626420741 BATT_vBrick10_5 "Voltage of brick 10";
CM_ SG_ 2626420741 BATT_vBrick09_5 "Voltage of brick 9";
CM_ BO_ 2626420742 "Voltages of bricks 9-12";
CM_ SG_ 2626420742 BATT_vBrick12_6 "Voltage of brick 12";
CM_ SG_ 2626420742 BATT_vBrick11_6 "Voltage of brick 11";
CM_ SG_ 2626420742 BATT_vBrick10_6 "Voltage of brick 10";
CM_ SG_ 2626420742 BATT_vBrick09_6 "Voltage of brick 9";
CM_ BO_ 2626420743 "Voltages of bricks 9-12";
CM_ SG_ 2626420743 BATT_vBrick12_7 "Voltage of brick 12";
CM_ SG_ 2626420743 BATT_vBrick11_7 "Voltage of brick 11";
CM_ SG_ 2626420743 BATT_vBrick10_7 "Voltage of brick 10";
CM_ SG_ 2626420743 BATT_vBrick09_7 "Voltage of brick 9";
CM_ BO_ 2626682880 "Voltages of bricks 13-14";
CM_ SG_ 2626682880 BATT_vBrick14_0 "Voltage of brick 14";
CM_ SG_ 2626682880 BATT_vBrick13_0 "Voltage of brick 13";
CM_ BO_ 2626682881 "Voltages of bricks 13-14";
CM_ SG_ 2626682881 BATT_vBrick14_1 "Voltage of brick 14";
CM_ SG_ 2626682881 BATT_vBrick13_1 "Voltage of brick 13";
CM_ BO_ 2626682882 "Voltages of bricks 13-14";
CM_ SG_ 2626682882 BATT_vBrick14_2 "Voltage of brick 14";
CM_ SG_ 2626682882 BATT_vBrick13_2 "Voltage of brick 13";
CM_ BO_ 2626682883 "Voltages of bricks 13-14";
CM_ SG_ 2626682883 BATT_vBrick14_3 "Voltage of brick 14";
CM_ SG_ 2626682883 BATT_vBrick13_3 "Voltage of brick 13";
CM_ BO_ 2626682884 "Voltages of bricks 13-14";
CM_ SG_ 2626682884 BATT_vBrick14_4 "Voltage of brick 14";
CM_ SG_ 2626682884 BATT_vBrick13_4 "Voltage of brick 13";
CM_ BO_ 2626682885 "Voltages of bricks 13-14";
CM_ SG_ 2626682885 BATT_vBrick14_5 "Voltage of brick 14";
CM_ SG_ 2626682885 BATT_vBrick13_5 "Voltage of brick 13";
CM_ BO_ 2626682886 "Voltages of bricks 13-14";
CM_ SG_ 2626682886 BATT_vBrick14_6 "Voltage of brick 14";
CM_ SG_ 2626682886 BATT_vBrick13_6 "Voltage of brick 13";
CM_ BO_ 2626682887 "Voltages of bricks 13-14";
CM_ SG_ 2626682887 BATT_vBrick14_7 "Voltage of brick 14";
CM_ SG_ 2626682887 BATT_vBrick13_7 "Voltage of brick 13";
CM_ BO_ 2626748416 "Harness Impedance";
CM_ SG_ 2626748416 BATT_HarnessImpedance_14_0 "Impedance of Harness
";
CM_ SG_ 2626748416 BATT_HarnessImpedance_13_0 "Impedance of Harness
";
CM_ SG_ 2626748416 BATT_HarnessImpedance_12_0 "Impedance of Harness
";
CM_ SG_ 2626748416 BATT_HarnessImpedance_11_0 "Impedance of Harness
";
CM_ SG_ 2626748416 BATT_HarnessImpedance_10_0 "Impedance of Harness
";
CM_ SG_ 2626748416 BATT_HarnessImpedance_9_0 "Impedance of Harness
";
CM_ SG_ 2626748416 BATT_HarnessImpedance_8_0 "Impedance of Harness
";
CM_ SG_ 2626748416 BATT_HarnessImpedance_7_0 "Impedance of Harness
";
CM_ SG_ 2626748416 BATT_HarnessImpedance_6_0 "Impedance of Harness
";
CM_ SG_ 2626748416 BATT_HarnessImpedance_5_0 "Impedance of Harness
";
CM_ SG_ 2626748416 BATT_HarnessImpedance_4_0 "Impedance of Harness
";
CM_ SG_ 2626748416 BATT_HarnessImpedance_3_0 "Impedance of Harness
";
CM_ SG_ 2626748416 BATT_HarnessImpedance_2_0 "Impedance of Harness
";
CM_ SG_ 2626748416 BATT_HarnessImpedance_1_0 "Impedance of Harness
";
CM_ SG_ 2626748416 BATT_HarnessImpedance_0_0 "Impedance of Harness
";
CM_ BO_ 2626748417 "Harness Impedance";
CM_ SG_ 2626748417 BATT_HarnessImpedance_14_1 "Impedance of Harness
";
CM_ SG_ 2626748417 BATT_HarnessImpedance_13_1 "Impedance of Harness
";
CM_ SG_ 2626748417 BATT_HarnessImpedance_12_1 "Impedance of Harness
";
CM_ SG_ 2626748417 BATT_HarnessImpedance_11_1 "Impedance of Harness
";
CM_ SG_ 2626748417 BATT_HarnessImpedance_10_1 "Impedance of Harness
";
CM_ SG_ 2626748417 BATT_HarnessImpedance_9_1 "Impedance of Harness
";
CM_ SG_ 2626748417 BATT_HarnessImpedance_8_1 "Impedance of Harness
";
CM_ SG_ 2626748417 BATT_HarnessImpedance_7_1 "Impedance of Harness
";
CM_ SG_ 2626748417 BATT_HarnessImpedance_6_1 "Impedance of Harness
";
CM_ SG_ 2626748417 BATT_HarnessImpedance_5_1 "Impedance of Harness
";
CM_ SG_ 2626748417 BATT_HarnessImpedance_4_1 "Impedance of Harness
";
CM_ SG_ 2626748417 BATT_HarnessImpedance_3_1 "Impedance of Harness
";
CM_ SG_ 2626748417 BATT_HarnessImpedance_2_1 "Impedance of Harness
";
CM_ SG_ 2626748417 BATT_HarnessImpedance_1_1 "Impedance of Harness
";
CM_ SG_ 2626748417 BATT_HarnessImpedance_0_1 "Impedance of Harness
";
CM_ BO_ 2626748418 "Harness Impedance";
CM_ SG_ 2626748418 BATT_HarnessImpedance_14_2 "Impedance of Harness
";
CM_ SG_ 2626748418 BATT_HarnessImpedance_13_2 "Impedance of Harness
";
CM_ SG_ 2626748418 BATT_HarnessImpedance_12_2 "Impedance of Harness
";
CM_ SG_ 2626748418 BATT_HarnessImpedance_11_2 "Impedance of Harness
";
CM_ SG_ 2626748418 BATT_HarnessImpedance_10_2 "Impedance of Harness
";
CM_ SG_ 2626748418 BATT_HarnessImpedance_9_2 "Impedance of Harness
";
CM_ SG_ 2626748418 BATT_HarnessImpedance_8_2 "Impedance of Harness
";
CM_ SG_ 2626748418 BATT_HarnessImpedance_7_2 "Impedance of Harness
";
CM_ SG_ 2626748418 BATT_HarnessImpedance_6_2 "Impedance of Harness
";
CM_ SG_ 2626748418 BATT_HarnessImpedance_5_2 "Impedance of Harness
";
CM_ SG_ 2626748418 BATT_HarnessImpedance_4_2 "Impedance of Harness
";
CM_ SG_ 2626748418 BATT_HarnessImpedance_3_2 "Impedance of Harness
";
CM_ SG_ 2626748418 BATT_HarnessImpedance_2_2 "Impedance of Harness
";
CM_ SG_ 2626748418 BATT_HarnessImpedance_1_2 "Impedance of Harness
";
CM_ SG_ 2626748418 BATT_HarnessImpedance_0_2 "Impedance of Harness
";
CM_ BO_ 2626748419 "Harness Impedance";
CM_ SG_ 2626748419 BATT_HarnessImpedance_14_3 "Impedance of Harness
";
CM_ SG_ 2626748419 BATT_HarnessImpedance_13_3 "Impedance of Harness
";
CM_ SG_ 2626748419 BATT_HarnessImpedance_12_3 "Impedance of Harness
";
CM_ SG_ 2626748419 BATT_HarnessImpedance_11_3 "Impedance of Harness
";
CM_ SG_ 2626748419 BATT_HarnessImpedance_10_3 "Impedance of Harness
";
CM_ SG_ 2626748419 BATT_HarnessImpedance_9_3 "Impedance of Harness
";
CM_ SG_ 2626748419 BATT_HarnessImpedance_8_3 "Impedance of Harness
";
CM_ SG_ 2626748419 BATT_HarnessImpedance_7_3 "Impedance of Harness
";
CM_ SG_ 2626748419 BATT_HarnessImpedance_6_3 "Impedance of Harness
";
CM_ SG_ 2626748419 BATT_HarnessImpedance_5_3 "Impedance of Harness
";
CM_ SG_ 2626748419 BATT_HarnessImpedance_4_3 "Impedance of Harness
";
CM_ SG_ 2626748419 BATT_HarnessImpedance_3_3 "Impedance of Harness
";
CM_ SG_ 2626748419 BATT_HarnessImpedance_2_3 "Impedance of Harness
";
CM_ SG_ 2626748419 BATT_HarnessImpedance_1_3 "Impedance of Harness
";
CM_ SG_ 2626748419 BATT_HarnessImpedance_0_3 "Impedance of Harness
";
CM_ BO_ 2626748420 "Harness Impedance";
CM_ SG_ 2626748420 BATT_HarnessImpedance_14_4 "Impedance of Harness
";
CM_ SG_ 2626748420 BATT_HarnessImpedance_13_4 "Impedance of Harness
";
CM_ SG_ 2626748420 BATT_HarnessImpedance_12_4 "Impedance of Harness
";
CM_ SG_ 2626748420 BATT_HarnessImpedance_11_4 "Impedance of Harness
";
CM_ SG_ 2626748420 BATT_HarnessImpedance_10_4 "Impedance of Harness
";
CM_ SG_ 2626748420 BATT_HarnessImpedance_9_4 "Impedance of Harness
";
CM_ SG_ 2626748420 BATT_HarnessImpedance_8_4 "Impedance of Harness
";
CM_ SG_ 2626748420 BATT_HarnessImpedance_7_4 "Impedance of Harness
";
CM_ SG_ 2626748420 BATT_HarnessImpedance_6_4 "Impedance of Harness
";
CM_ SG_ 2626748420 BATT_HarnessImpedance_5_4 "Impedance of Harness
";
CM_ SG_ 2626748420 BATT_HarnessImpedance_4_4 "Impedance of Harness
";
CM_ SG_ 2626748420 BATT_HarnessImpedance_3_4 "Impedance of Harness
";
CM_ SG_ 2626748420 BATT_HarnessImpedance_2_4 "Impedance of Harness
";
CM_ SG_ 2626748420 BATT_HarnessImpedance_1_4 "Impedance of Harness
";
CM_ SG_ 2626748420 BATT_HarnessImpedance_0_4 "Impedance of Harness
";
CM_ BO_ 2626748421 "Harness Impedance";
CM_ SG_ 2626748421 BATT_HarnessImpedance_14_5 "Impedance of Harness
";
CM_ SG_ 2626748421 BATT_HarnessImpedance_13_5 "Impedance of Harness
";
CM_ SG_ 2626748421 BATT_HarnessImpedance_12_5 "Impedance of Harness
";
CM_ SG_ 2626748421 BATT_HarnessImpedance_11_5 "Impedance of Harness
";
CM_ SG_ 2626748421 BATT_HarnessImpedance_10_5 "Impedance of Harness
";
CM_ SG_ 2626748421 BATT_HarnessImpedance_9_5 "Impedance of Harness
";
CM_ SG_ 2626748421 BATT_HarnessImpedance_8_5 "Impedance of Harness
";
CM_ SG_ 2626748421 BATT_HarnessImpedance_7_5 "Impedance of Harness
";
CM_ SG_ 2626748421 BATT_HarnessImpedance_6_5 "Impedance of Harness
";
CM_ SG_ 2626748421 BATT_HarnessImpedance_5_5 "Impedance of Harness
";
CM_ SG_ 2626748421 BATT_HarnessImpedance_4_5 "Impedance of Harness
";
CM_ SG_ 2626748421 BATT_HarnessImpedance_3_5 "Impedance of Harness
";
CM_ SG_ 2626748421 BATT_HarnessImpedance_2_5 "Impedance of Harness
";
CM_ SG_ 2626748421 BATT_HarnessImpedance_1_5 "Impedance of Harness
";
CM_ SG_ 2626748421 BATT_HarnessImpedance_0_5 "Impedance of Harness
";
CM_ BO_ 2626748422 "Harness Impedance";
CM_ SG_ 2626748422 BATT_HarnessImpedance_14_6 "Impedance of Harness
";
CM_ SG_ 2626748422 BATT_HarnessImpedance_13_6 "Impedance of Harness
";
CM_ SG_ 2626748422 BATT_HarnessImpedance_12_6 "Impedance of Harness
";
CM_ SG_ 2626748422 BATT_HarnessImpedance_11_6 "Impedance of Harness
";
CM_ SG_ 2626748422 BATT_HarnessImpedance_10_6 "Impedance of Harness
";
CM_ SG_ 2626748422 BATT_HarnessImpedance_9_6 "Impedance of Harness
";
CM_ SG_ 2626748422 BATT_HarnessImpedance_8_6 "Impedance of Harness
";
CM_ SG_ 2626748422 BATT_HarnessImpedance_7_6 "Impedance of Harness
";
CM_ SG_ 2626748422 BATT_HarnessImpedance_6_6 "Impedance of Harness
";
CM_ SG_ 2626748422 BATT_HarnessImpedance_5_6 "Impedance of Harness
";
CM_ SG_ 2626748422 BATT_HarnessImpedance_4_6 "Impedance of Harness
";
CM_ SG_ 2626748422 BATT_HarnessImpedance_3_6 "Impedance of Harness
";
CM_ SG_ 2626748422 BATT_HarnessImpedance_2_6 "Impedance of Harness
";
CM_ SG_ 2626748422 BATT_HarnessImpedance_1_6 "Impedance of Harness
";
CM_ SG_ 2626748422 BATT_HarnessImpedance_0_6 "Impedance of Harness
";
CM_ BO_ 2626748423 "Harness Impedance";
CM_ SG_ 2626748423 BATT_HarnessImpedance_14_7 "Impedance of Harness
";
CM_ SG_ 2626748423 BATT_HarnessImpedance_13_7 "Impedance of Harness
";
CM_ SG_ 2626748423 BATT_HarnessImpedance_12_7 "Impedance of Harness
";
CM_ SG_ 2626748423 BATT_HarnessImpedance_11_7 "Impedance of Harness
";
CM_ SG_ 2626748423 BATT_HarnessImpedance_10_7 "Impedance of Harness
";
CM_ SG_ 2626748423 BATT_HarnessImpedance_9_7 "Impedance of Harness
";
CM_ SG_ 2626748423 BATT_HarnessImpedance_8_7 "Impedance of Harness
";
CM_ SG_ 2626748423 BATT_HarnessImpedance_7_7 "Impedance of Harness
";
CM_ SG_ 2626748423 BATT_HarnessImpedance_6_7 "Impedance of Harness
";
CM_ SG_ 2626748423 BATT_HarnessImpedance_5_7 "Impedance of Harness
";
CM_ SG_ 2626748423 BATT_HarnessImpedance_4_7 "Impedance of Harness
";
CM_ SG_ 2626748423 BATT_HarnessImpedance_3_7 "Impedance of Harness
";
CM_ SG_ 2626748423 BATT_HarnessImpedance_2_7 "Impedance of Harness
";
CM_ SG_ 2626748423 BATT_HarnessImpedance_1_7 "Impedance of Harness
";
CM_ SG_ 2626748423 BATT_HarnessImpedance_0_7 "Impedance of Harness
";
CM_ BO_ 2626813952 "Harness impedance Delta ";
CM_ SG_ 2626813952 BATT_HrnsImpDelta_3_0 "Delat value of Harness Impedance
";
CM_ SG_ 2626813952 BATT_HrnsImpDelta_2_0 "Delat value of Harness Impedance
";
CM_ SG_ 2626813952 BATT_HrnsImpDelta_1_0 "Delat value of Harness Impedance
";
CM_ SG_ 2626813952 BATT_HrnsImpDelta_0_0 "Delat value of Harness Impedance
";
CM_ BO_ 2626813953 "Harness impedance Delta ";
CM_ SG_ 2626813953 BATT_HrnsImpDelta_3_1 "Delat value of Harness Impedance
";
CM_ SG_ 2626813953 BATT_HrnsImpDelta_2_1 "Delat value of Harness Impedance
";
CM_ SG_ 2626813953 BATT_HrnsImpDelta_1_1 "Delat value of Harness Impedance
";
CM_ SG_ 2626813953 BATT_HrnsImpDelta_0_1 "Delat value of Harness Impedance
";
CM_ BO_ 2626813954 "Harness impedance Delta ";
CM_ SG_ 2626813954 BATT_HrnsImpDelta_3_2 "Delat value of Harness Impedance
";
CM_ SG_ 2626813954 BATT_HrnsImpDelta_2_2 "Delat value of Harness Impedance
";
CM_ SG_ 2626813954 BATT_HrnsImpDelta_1_2 "Delat value of Harness Impedance
";
CM_ SG_ 2626813954 BATT_HrnsImpDelta_0_2 "Delat value of Harness Impedance
";
CM_ BO_ 2626813955 "Harness impedance Delta ";
CM_ SG_ 2626813955 BATT_HrnsImpDelta_3_3 "Delat value of Harness Impedance
";
CM_ SG_ 2626813955 BATT_HrnsImpDelta_2_3 "Delat value of Harness Impedance
";
CM_ SG_ 2626813955 BATT_HrnsImpDelta_1_3 "Delat value of Harness Impedance
";
CM_ SG_ 2626813955 BATT_HrnsImpDelta_0_3 "Delat value of Harness Impedance
";
CM_ BO_ 2626813956 "Harness impedance Delta ";
CM_ SG_ 2626813956 BATT_HrnsImpDelta_3_4 "Delat value of Harness Impedance
";
CM_ SG_ 2626813956 BATT_HrnsImpDelta_2_4 "Delat value of Harness Impedance
";
CM_ SG_ 2626813956 BATT_HrnsImpDelta_1_4 "Delat value of Harness Impedance
";
CM_ SG_ 2626813956 BATT_HrnsImpDelta_0_4 "Delat value of Harness Impedance
";
CM_ BO_ 2626813957 "Harness impedance Delta ";
CM_ SG_ 2626813957 BATT_HrnsImpDelta_3_5 "Delat value of Harness Impedance
";
CM_ SG_ 2626813957 BATT_HrnsImpDelta_2_5 "Delat value of Harness Impedance
";
CM_ SG_ 2626813957 BATT_HrnsImpDelta_1_5 "Delat value of Harness Impedance
";
CM_ SG_ 2626813957 BATT_HrnsImpDelta_0_5 "Delat value of Harness Impedance
";
CM_ BO_ 2626813958 "Harness impedance Delta ";
CM_ SG_ 2626813958 BATT_HrnsImpDelta_3_6 "Delat value of Harness Impedance
";
CM_ SG_ 2626813958 BATT_HrnsImpDelta_2_6 "Delat value of Harness Impedance
";
CM_ SG_ 2626813958 BATT_HrnsImpDelta_1_6 "Delat value of Harness Impedance
";
CM_ SG_ 2626813958 BATT_HrnsImpDelta_0_6 "Delat value of Harness Impedance
";
CM_ BO_ 2626813959 "Harness impedance Delta ";
CM_ SG_ 2626813959 BATT_HrnsImpDelta_3_7 "Delat value of Harness Impedance
";
CM_ SG_ 2626813959 BATT_HrnsImpDelta_2_7 "Delat value of Harness Impedance
";
CM_ SG_ 2626813959 BATT_HrnsImpDelta_1_7 "Delat value of Harness Impedance
";
CM_ SG_ 2626813959 BATT_HrnsImpDelta_0_7 "Delat value of Harness Impedance
";
CM_ BO_ 2626818048 "Harness impedance Delta ";
CM_ SG_ 2626818048 BATT_HrnsImpDelta_7_0 "Delat value of Harness Impedance
";
CM_ SG_ 2626818048 BATT_HrnsImpDelta_6_0 "Delat value of Harness Impedance
";
CM_ SG_ 2626818048 BATT_HrnsImpDelta_5_0 "Delat value of Harness Impedance
";
CM_ SG_ 2626818048 BATT_HrnsImpDelta_4_0 "Delat value of Harness Impedance
";
CM_ BO_ 2626818049 "Harness impedance Delta ";
CM_ SG_ 2626818049 BATT_HrnsImpDelta_7_1 "Delat value of Harness Impedance
";
CM_ SG_ 2626818049 BATT_HrnsImpDelta_6_1 "Delat value of Harness Impedance
";
CM_ SG_ 2626818049 BATT_HrnsImpDelta_5_1 "Delat value of Harness Impedance
";
CM_ SG_ 2626818049 BATT_HrnsImpDelta_4_1 "Delat value of Harness Impedance
";
CM_ BO_ 2626818050 "Harness impedance Delta ";
CM_ SG_ 2626818050 BATT_HrnsImpDelta_7_2 "Delat value of Harness Impedance
";
CM_ SG_ 2626818050 BATT_HrnsImpDelta_6_2 "Delat value of Harness Impedance
";
CM_ SG_ 2626818050 BATT_HrnsImpDelta_5_2 "Delat value of Harness Impedance
";
CM_ SG_ 2626818050 BATT_HrnsImpDelta_4_2 "Delat value of Harness Impedance
";
CM_ BO_ 2626818051 "Harness impedance Delta ";
CM_ SG_ 2626818051 BATT_HrnsImpDelta_7_3 "Delat value of Harness Impedance
";
CM_ SG_ 2626818051 BATT_HrnsImpDelta_6_3 "Delat value of Harness Impedance
";
CM_ SG_ 2626818051 BATT_HrnsImpDelta_5_3 "Delat value of Harness Impedance
";
CM_ SG_ 2626818051 BATT_HrnsImpDelta_4_3 "Delat value of Harness Impedance
";
CM_ BO_ 2626818052 "Harness impedance Delta ";
CM_ SG_ 2626818052 BATT_HrnsImpDelta_7_4 "Delat value of Harness Impedance
";
CM_ SG_ 2626818052 BATT_HrnsImpDelta_6_4 "Delat value of Harness Impedance
";
CM_ SG_ 2626818052 BATT_HrnsImpDelta_5_4 "Delat value of Harness Impedance
";
CM_ SG_ 2626818052 BATT_HrnsImpDelta_4_4 "Delat value of Harness Impedance
";
CM_ BO_ 2626818053 "Harness impedance Delta ";
CM_ SG_ 2626818053 BATT_HrnsImpDelta_7_5 "Delat value of Harness Impedance
";
CM_ SG_ 2626818053 BATT_HrnsImpDelta_6_5 "Delat value of Harness Impedance
";
CM_ SG_ 2626818053 BATT_HrnsImpDelta_5_5 "Delat value of Harness Impedance
";
CM_ SG_ 2626818053 BATT_HrnsImpDelta_4_5 "Delat value of Harness Impedance
";
CM_ BO_ 2626818054 "Harness impedance Delta ";
CM_ SG_ 2626818054 BATT_HrnsImpDelta_7_6 "Delat value of Harness Impedance
";
CM_ SG_ 2626818054 BATT_HrnsImpDelta_6_6 "Delat value of Harness Impedance
";
CM_ SG_ 2626818054 BATT_HrnsImpDelta_5_6 "Delat value of Harness Impedance
";
CM_ SG_ 2626818054 BATT_HrnsImpDelta_4_6 "Delat value of Harness Impedance
";
CM_ BO_ 2626818055 "Harness impedance Delta ";
CM_ SG_ 2626818055 BATT_HrnsImpDelta_7_7 "Delat value of Harness Impedance
";
CM_ SG_ 2626818055 BATT_HrnsImpDelta_6_7 "Delat value of Harness Impedance
";
CM_ SG_ 2626818055 BATT_HrnsImpDelta_5_7 "Delat value of Harness Impedance
";
CM_ SG_ 2626818055 BATT_HrnsImpDelta_4_7 "Delat value of Harness Impedance
";
CM_ BO_ 2626822144 "Harness impedance Delta ";
CM_ SG_ 2626822144 BATT_HrnsImpDelta_11_0 "Delat value of Harness Impedance
";
CM_ SG_ 2626822144 BATT_HrnsImpDelta_10_0 "Delat value of Harness Impedance
";
CM_ SG_ 2626822144 BATT_HrnsImpDelta_9_0 "Delat value of Harness Impedance
";
CM_ SG_ 2626822144 BATT_HrnsImpDelta_8_0 "Delat value of Harness Impedance
";
CM_ BO_ 2626822145 "Harness impedance Delta ";
CM_ SG_ 2626822145 BATT_HrnsImpDelta_11_1 "Delat value of Harness Impedance
";
CM_ SG_ 2626822145 BATT_HrnsImpDelta_10_1 "Delat value of Harness Impedance
";
CM_ SG_ 2626822145 BATT_HrnsImpDelta_9_1 "Delat value of Harness Impedance
";
CM_ SG_ 2626822145 BATT_HrnsImpDelta_8_1 "Delat value of Harness Impedance
";
CM_ BO_ 2626822146 "Harness impedance Delta ";
CM_ SG_ 2626822146 BATT_HrnsImpDelta_11_2 "Delat value of Harness Impedance
";
CM_ SG_ 2626822146 BATT_HrnsImpDelta_10_2 "Delat value of Harness Impedance
";
CM_ SG_ 2626822146 BATT_HrnsImpDelta_9_2 "Delat value of Harness Impedance
";
CM_ SG_ 2626822146 BATT_HrnsImpDelta_8_2 "Delat value of Harness Impedance
";
CM_ BO_ 2626822147 "Harness impedance Delta ";
CM_ SG_ 2626822147 BATT_HrnsImpDelta_11_3 "Delat value of Harness Impedance
";
CM_ SG_ 2626822147 BATT_HrnsImpDelta_10_3 "Delat value of Harness Impedance
";
CM_ SG_ 2626822147 BATT_HrnsImpDelta_9_3 "Delat value of Harness Impedance
";
CM_ SG_ 2626822147 BATT_HrnsImpDelta_8_3 "Delat value of Harness Impedance
";
CM_ BO_ 2626822148 "Harness impedance Delta ";
CM_ SG_ 2626822148 BATT_HrnsImpDelta_11_4 "Delat value of Harness Impedance
";
CM_ SG_ 2626822148 BATT_HrnsImpDelta_10_4 "Delat value of Harness Impedance
";
CM_ SG_ 2626822148 BATT_HrnsImpDelta_9_4 "Delat value of Harness Impedance
";
CM_ SG_ 2626822148 BATT_HrnsImpDelta_8_4 "Delat value of Harness Impedance
";
CM_ BO_ 2626822149 "Harness impedance Delta ";
CM_ SG_ 2626822149 BATT_HrnsImpDelta_11_5 "Delat value of Harness Impedance
";
CM_ SG_ 2626822149 BATT_HrnsImpDelta_10_5 "Delat value of Harness Impedance
";
CM_ SG_ 2626822149 BATT_HrnsImpDelta_9_5 "Delat value of Harness Impedance
";
CM_ SG_ 2626822149 BATT_HrnsImpDelta_8_5 "Delat value of Harness Impedance
";
CM_ BO_ 2626822150 "Harness impedance Delta ";
CM_ SG_ 2626822150 BATT_HrnsImpDelta_11_6 "Delat value of Harness Impedance
";
CM_ SG_ 2626822150 BATT_HrnsImpDelta_10_6 "Delat value of Harness Impedance
";
CM_ SG_ 2626822150 BATT_HrnsImpDelta_9_6 "Delat value of Harness Impedance
";
CM_ SG_ 2626822150 BATT_HrnsImpDelta_8_6 "Delat value of Harness Impedance
";
CM_ BO_ 2626822151 "Harness impedance Delta ";
CM_ SG_ 2626822151 BATT_HrnsImpDelta_11_7 "Delat value of Harness Impedance
";
CM_ SG_ 2626822151 BATT_HrnsImpDelta_10_7 "Delat value of Harness Impedance
";
CM_ SG_ 2626822151 BATT_HrnsImpDelta_9_7 "Delat value of Harness Impedance
";
CM_ SG_ 2626822151 BATT_HrnsImpDelta_8_7 "Delat value of Harness Impedance
";
CM_ BO_ 2626826240 "Harness impedance Delta ";
CM_ SG_ 2626826240 BATT_HrnsImpDelta_14_0 "Delat value of Harness Impedance
";
CM_ SG_ 2626826240 BATT_HrnsImpDelta_13_0 "Delat value of Harness Impedance
";
CM_ SG_ 2626826240 BATT_HrnsImpDelta_12_0 "Delat value of Harness Impedance
";
CM_ BO_ 2626826241 "Harness impedance Delta ";
CM_ SG_ 2626826241 BATT_HrnsImpDelta_14_1 "Delat value of Harness Impedance
";
CM_ SG_ 2626826241 BATT_HrnsImpDelta_13_1 "Delat value of Harness Impedance
";
CM_ SG_ 2626826241 BATT_HrnsImpDelta_12_1 "Delat value of Harness Impedance
";
CM_ BO_ 2626826242 "Harness impedance Delta ";
CM_ SG_ 2626826242 BATT_HrnsImpDelta_14_2 "Delat value of Harness Impedance
";
CM_ SG_ 2626826242 BATT_HrnsImpDelta_13_2 "Delat value of Harness Impedance
";
CM_ SG_ 2626826242 BATT_HrnsImpDelta_12_2 "Delat value of Harness Impedance
";
CM_ BO_ 2626826243 "Harness impedance Delta ";
CM_ SG_ 2626826243 BATT_HrnsImpDelta_14_3 "Delat value of Harness Impedance
";
CM_ SG_ 2626826243 BATT_HrnsImpDelta_13_3 "Delat value of Harness Impedance
";
CM_ SG_ 2626826243 BATT_HrnsImpDelta_12_3 "Delat value of Harness Impedance
";
CM_ BO_ 2626826244 "Harness impedance Delta ";
CM_ SG_ 2626826244 BATT_HrnsImpDelta_14_4 "Delat value of Harness Impedance
";
CM_ SG_ 2626826244 BATT_HrnsImpDelta_13_4 "Delat value of Harness Impedance
";
CM_ SG_ 2626826244 BATT_HrnsImpDelta_12_4 "Delat value of Harness Impedance
";
CM_ BO_ 2626826245 "Harness impedance Delta ";
CM_ SG_ 2626826245 BATT_HrnsImpDelta_14_5 "Delat value of Harness Impedance
";
CM_ SG_ 2626826245 BATT_HrnsImpDelta_13_5 "Delat value of Harness Impedance
";
CM_ SG_ 2626826245 BATT_HrnsImpDelta_12_5 "Delat value of Harness Impedance
";
CM_ BO_ 2626826246 "Harness impedance Delta ";
CM_ SG_ 2626826246 BATT_HrnsImpDelta_14_6 "Delat value of Harness Impedance
";
CM_ SG_ 2626826246 BATT_HrnsImpDelta_13_6 "Delat value of Harness Impedance
";
CM_ SG_ 2626826246 BATT_HrnsImpDelta_12_6 "Delat value of Harness Impedance
";
CM_ BO_ 2626826247 "Harness impedance Delta ";
CM_ SG_ 2626826247 BATT_HrnsImpDelta_14_7 "Delat value of Harness Impedance
";
CM_ SG_ 2626826247 BATT_HrnsImpDelta_13_7 "Delat value of Harness Impedance
";
CM_ SG_ 2626826247 BATT_HrnsImpDelta_12_7 "Delat value of Harness Impedance
";
CM_ BO_ 2626945024 "Balancing status";
CM_ BO_ 2626945025 "Balancing status";
CM_ BO_ 2626945026 "Balancing status";
CM_ BO_ 2626945027 "Balancing status";
CM_ BO_ 2626945028 "Balancing status";
CM_ BO_ 2626945029 "Balancing status";
CM_ BO_ 2626945030 "Balancing status";
CM_ BO_ 2626945031 "Balancing status";
CM_ BO_ 2629828608 "Total Ah charged and discharged counters";
CM_ SG_ 2629828608 BATT_ahDchTotal_0 "Total Ah discharged";
CM_ SG_ 2629828608 BATT_ahChgTotal_0 "Total Ah charged";
CM_ BO_ 2629828609 "Total Ah charged and discharged counters";
CM_ SG_ 2629828609 BATT_ahDchTotal_1 "Total Ah discharged";
CM_ SG_ 2629828609 BATT_ahChgTotal_1 "Total Ah charged";
CM_ BO_ 2629828610 "Total Ah charged and discharged counters";
CM_ SG_ 2629828610 BATT_ahDchTotal_2 "Total Ah discharged";
CM_ SG_ 2629828610 BATT_ahChgTotal_2 "Total Ah charged";
CM_ BO_ 2629828611 "Total Ah charged and discharged counters";
CM_ SG_ 2629828611 BATT_ahDchTotal_3 "Total Ah discharged";
CM_ SG_ 2629828611 BATT_ahChgTotal_3 "Total Ah charged";
CM_ BO_ 2629828612 "Total Ah charged and discharged counters";
CM_ SG_ 2629828612 BATT_ahDchTotal_4 "Total Ah discharged";
CM_ SG_ 2629828612 BATT_ahChgTotal_4 "Total Ah charged";
CM_ BO_ 2629828613 "Total Ah charged and discharged counters";
CM_ SG_ 2629828613 BATT_ahDchTotal_5 "Total Ah discharged";
CM_ SG_ 2629828613 BATT_ahChgTotal_5 "Total Ah charged";
CM_ BO_ 2629828614 "Total Ah charged and discharged counters";
CM_ SG_ 2629828614 BATT_ahDchTotal_6 "Total Ah discharged";
CM_ SG_ 2629828614 BATT_ahChgTotal_6 "Total Ah charged";
CM_ BO_ 2629828615 "Total Ah charged and discharged counters";
CM_ SG_ 2629828615 BATT_ahDchTotal_7 "Total Ah discharged";
CM_ SG_ 2629828615 BATT_ahChgTotal_7 "Total Ah charged";
CM_ BO_ 2630090752 "State of charge of bricks 1-4";
CM_ SG_ 2630090752 BATT_socBrick04_0 "State of charge of brick 4";
CM_ SG_ 2630090752 BATT_socBrick03_0 "State of charge of brick 3";
CM_ SG_ 2630090752 BATT_socBrick02_0 "State of charge of brick 2";
CM_ SG_ 2630090752 BATT_socBrick01_0 "State of charge of brick 1";
CM_ BO_ 2630090753 "State of charge of bricks 1-4";
CM_ SG_ 2630090753 BATT_socBrick04_1 "State of charge of brick 4";
CM_ SG_ 2630090753 BATT_socBrick03_1 "State of charge of brick 3";
CM_ SG_ 2630090753 BATT_socBrick02_1 "State of charge of brick 2";
CM_ SG_ 2630090753 BATT_socBrick01_1 "State of charge of brick 1";
CM_ BO_ 2630090754 "State of charge of bricks 1-4";
CM_ SG_ 2630090754 BATT_socBrick04_2 "State of charge of brick 4";
CM_ SG_ 2630090754 BATT_socBrick03_2 "State of charge of brick 3";
CM_ SG_ 2630090754 BATT_socBrick02_2 "State of charge of brick 2";
CM_ SG_ 2630090754 BATT_socBrick01_2 "State of charge of brick 1";
CM_ BO_ 2630090755 "State of charge of bricks 1-4";
CM_ SG_ 2630090755 BATT_socBrick04_3 "State of charge of brick 4";
CM_ SG_ 2630090755 BATT_socBrick03_3 "State of charge of brick 3";
CM_ SG_ 2630090755 BATT_socBrick02_3 "State of charge of brick 2";
CM_ SG_ 2630090755 BATT_socBrick01_3 "State of charge of brick 1";
CM_ BO_ 2630090756 "State of charge of bricks 1-4";
CM_ SG_ 2630090756 BATT_socBrick04_4 "State of charge of brick 4";
CM_ SG_ 2630090756 BATT_socBrick03_4 "State of charge of brick 3";
CM_ SG_ 2630090756 BATT_socBrick02_4 "State of charge of brick 2";
CM_ SG_ 2630090756 BATT_socBrick01_4 "State of charge of brick 1";
CM_ BO_ 2630090757 "State of charge of bricks 1-4";
CM_ SG_ 2630090757 BATT_socBrick04_5 "State of charge of brick 4";
CM_ SG_ 2630090757 BATT_socBrick03_5 "State of charge of brick 3";
CM_ SG_ 2630090757 BATT_socBrick02_5 "State of charge of brick 2";
CM_ SG_ 2630090757 BATT_socBrick01_5 "State of charge of brick 1";
CM_ BO_ 2630090758 "State of charge of bricks 1-4";
CM_ SG_ 2630090758 BATT_socBrick04_6 "State of charge of brick 4";
CM_ SG_ 2630090758 BATT_socBrick03_6 "State of charge of brick 3";
CM_ SG_ 2630090758 BATT_socBrick02_6 "State of charge of brick 2";
CM_ SG_ 2630090758 BATT_socBrick01_6 "State of charge of brick 1";
CM_ BO_ 2630090759 "State of charge of bricks 1-4";
CM_ SG_ 2630090759 BATT_socBrick04_7 "State of charge of brick 4";
CM_ SG_ 2630090759 BATT_socBrick03_7 "State of charge of brick 3";
CM_ SG_ 2630090759 BATT_socBrick02_7 "State of charge of brick 2";
CM_ SG_ 2630090759 BATT_socBrick01_7 "State of charge of brick 1";
CM_ BO_ 2630352896 "State of charge of bricks 5-8";
CM_ SG_ 2630352896 BATT_socBrick08_0 "State of charge of brick 8";
CM_ SG_ 2630352896 BATT_socBrick07_0 "State of charge of brick 7";
CM_ SG_ 2630352896 BATT_socBrick06_0 "State of charge of brick 6";
CM_ SG_ 2630352896 BATT_socBrick05_0 "State of charge of brick 5";
CM_ BO_ 2630352897 "State of charge of bricks 5-8";
CM_ SG_ 2630352897 BATT_socBrick08_1 "State of charge of brick 8";
CM_ SG_ 2630352897 BATT_socBrick07_1 "State of charge of brick 7";
CM_ SG_ 2630352897 BATT_socBrick06_1 "State of charge of brick 6";
CM_ SG_ 2630352897 BATT_socBrick05_1 "State of charge of brick 5";
CM_ BO_ 2630352898 "State of charge of bricks 5-8";
CM_ SG_ 2630352898 BATT_socBrick08_2 "State of charge of brick 8";
CM_ SG_ 2630352898 BATT_socBrick07_2 "State of charge of brick 7";
CM_ SG_ 2630352898 BATT_socBrick06_2 "State of charge of brick 6";
CM_ SG_ 2630352898 BATT_socBrick05_2 "State of charge of brick 5";
CM_ BO_ 2630352899 "State of charge of bricks 5-8";
CM_ SG_ 2630352899 BATT_socBrick08_3 "State of charge of brick 8";
CM_ SG_ 2630352899 BATT_socBrick07_3 "State of charge of brick 7";
CM_ SG_ 2630352899 BATT_socBrick06_3 "State of charge of brick 6";
CM_ SG_ 2630352899 BATT_socBrick05_3 "State of charge of brick 5";
CM_ BO_ 2630352900 "State of charge of bricks 5-8";
CM_ SG_ 2630352900 BATT_socBrick08_4 "State of charge of brick 8";
CM_ SG_ 2630352900 BATT_socBrick07_4 "State of charge of brick 7";
CM_ SG_ 2630352900 BATT_socBrick06_4 "State of charge of brick 6";
CM_ SG_ 2630352900 BATT_socBrick05_4 "State of charge of brick 5";
CM_ BO_ 2630352901 "State of charge of bricks 5-8";
CM_ SG_ 2630352901 BATT_socBrick08_5 "State of charge of brick 8";
CM_ SG_ 2630352901 BATT_socBrick07_5 "State of charge of brick 7";
CM_ SG_ 2630352901 BATT_socBrick06_5 "State of charge of brick 6";
CM_ SG_ 2630352901 BATT_socBrick05_5 "State of charge of brick 5";
CM_ BO_ 2630352902 "State of charge of bricks 5-8";
CM_ SG_ 2630352902 BATT_socBrick08_6 "State of charge of brick 8";
CM_ SG_ 2630352902 BATT_socBrick07_6 "State of charge of brick 7";
CM_ SG_ 2630352902 BATT_socBrick06_6 "State of charge of brick 6";
CM_ SG_ 2630352902 BATT_socBrick05_6 "State of charge of brick 5";
CM_ BO_ 2630352903 "State of charge of bricks 5-8";
CM_ SG_ 2630352903 BATT_socBrick08_7 "State of charge of brick 8";
CM_ SG_ 2630352903 BATT_socBrick07_7 "State of charge of brick 7";
CM_ SG_ 2630352903 BATT_socBrick06_7 "State of charge of brick 6";
CM_ SG_ 2630352903 BATT_socBrick05_7 "State of charge of brick 5";
CM_ BO_ 2630615040 "State of charge of bricks 9-12";
CM_ SG_ 2630615040 BATT_socBrick12_0 "State of charge of brick 12";
CM_ SG_ 2630615040 BATT_socBrick11_0 "State of charge of brick 11";
CM_ SG_ 2630615040 BATT_socBrick09_0 "State of charge of brick 9";
CM_ SG_ 2630615040 BATT_socBrick10_0 "State of charge of brick 10";
CM_ BO_ 2630615041 "State of charge of bricks 9-12";
CM_ SG_ 2630615041 BATT_socBrick12_1 "State of charge of brick 12";
CM_ SG_ 2630615041 BATT_socBrick11_1 "State of charge of brick 11";
CM_ SG_ 2630615041 BATT_socBrick09_1 "State of charge of brick 9";
CM_ SG_ 2630615041 BATT_socBrick10_1 "State of charge of brick 10";
CM_ BO_ 2630615042 "State of charge of bricks 9-12";
CM_ SG_ 2630615042 BATT_socBrick12_2 "State of charge of brick 12";
CM_ SG_ 2630615042 BATT_socBrick11_2 "State of charge of brick 11";
CM_ SG_ 2630615042 BATT_socBrick09_2 "State of charge of brick 9";
CM_ SG_ 2630615042 BATT_socBrick10_2 "State of charge of brick 10";
CM_ BO_ 2630615043 "State of charge of bricks 9-12";
CM_ SG_ 2630615043 BATT_socBrick12_3 "State of charge of brick 12";
CM_ SG_ 2630615043 BATT_socBrick11_3 "State of charge of brick 11";
CM_ SG_ 2630615043 BATT_socBrick09_3 "State of charge of brick 9";
CM_ SG_ 2630615043 BATT_socBrick10_3 "State of charge of brick 10";
CM_ BO_ 2630615044 "State of charge of bricks 9-12";
CM_ SG_ 2630615044 BATT_socBrick12_4 "State of charge of brick 12";
CM_ SG_ 2630615044 BATT_socBrick11_4 "State of charge of brick 11";
CM_ SG_ 2630615044 BATT_socBrick09_4 "State of charge of brick 9";
CM_ SG_ 2630615044 BATT_socBrick10_4 "State of charge of brick 10";
CM_ BO_ 2630615045 "State of charge of bricks 9-12";
CM_ SG_ 2630615045 BATT_socBrick12_5 "State of charge of brick 12";
CM_ SG_ 2630615045 BATT_socBrick11_5 "State of charge of brick 11";
CM_ SG_ 2630615045 BATT_socBrick09_5 "State of charge of brick 9";
CM_ SG_ 2630615045 BATT_socBrick10_5 "State of charge of brick 10";
CM_ BO_ 2630615046 "State of charge of bricks 9-12";
CM_ SG_ 2630615046 BATT_socBrick12_6 "State of charge of brick 12";
CM_ SG_ 2630615046 BATT_socBrick11_6 "State of charge of brick 11";
CM_ SG_ 2630615046 BATT_socBrick09_6 "State of charge of brick 9";
CM_ SG_ 2630615046 BATT_socBrick10_6 "State of charge of brick 10";
CM_ BO_ 2630615047 "State of charge of bricks 9-12";
CM_ SG_ 2630615047 BATT_socBrick12_7 "State of charge of brick 12";
CM_ SG_ 2630615047 BATT_socBrick11_7 "State of charge of brick 11";
CM_ SG_ 2630615047 BATT_socBrick09_7 "State of charge of brick 9";
CM_ SG_ 2630615047 BATT_socBrick10_7 "State of charge of brick 10";
CM_ BO_ 2630877184 "State of charge of bricks 13-14";
CM_ SG_ 2630877184 BATT_socState_0 "SOC State";
CM_ SG_ 2630877184 BATT_socLoLimit_0 "SOC Low Limit Mask";
CM_ SG_ 2630877184 BATT_socHiLimit_0 "SOC Low Limit Mask";
CM_ SG_ 2630877184 BATT_socBrick14_0 "State of charge of brick 14";
CM_ SG_ 2630877184 BATT_socBrick13_0 "State of charge of brick 13";
CM_ BO_ 2630877185 "State of charge of bricks 13-14";
CM_ SG_ 2630877185 BATT_socState_1 "SOC State";
CM_ SG_ 2630877185 BATT_socLoLimit_1 "SOC Low Limit Mask";
CM_ SG_ 2630877185 BATT_socHiLimit_1 "SOC Low Limit Mask";
CM_ SG_ 2630877185 BATT_socBrick14_1 "State of charge of brick 14";
CM_ SG_ 2630877185 BATT_socBrick13_1 "State of charge of brick 13";
CM_ BO_ 2630877186 "State of charge of bricks 13-14";
CM_ SG_ 2630877186 BATT_socState_2 "SOC State";
CM_ SG_ 2630877186 BATT_socLoLimit_2 "SOC Low Limit Mask";
CM_ SG_ 2630877186 BATT_socHiLimit_2 "SOC Low Limit Mask";
CM_ SG_ 2630877186 BATT_socBrick14_2 "State of charge of brick 14";
CM_ SG_ 2630877186 BATT_socBrick13_2 "State of charge of brick 13";
CM_ BO_ 2630877187 "State of charge of bricks 13-14";
CM_ SG_ 2630877187 BATT_socState_3 "SOC State";
CM_ SG_ 2630877187 BATT_socLoLimit_3 "SOC Low Limit Mask";
CM_ SG_ 2630877187 BATT_socHiLimit_3 "SOC Low Limit Mask";
CM_ SG_ 2630877187 BATT_socBrick14_3 "State of charge of brick 14";
CM_ SG_ 2630877187 BATT_socBrick13_3 "State of charge of brick 13";
CM_ BO_ 2630877188 "State of charge of bricks 13-14";
CM_ SG_ 2630877188 BATT_socState_4 "SOC State";
CM_ SG_ 2630877188 BATT_socLoLimit_4 "SOC Low Limit Mask";
CM_ SG_ 2630877188 BATT_socHiLimit_4 "SOC Low Limit Mask";
CM_ SG_ 2630877188 BATT_socBrick14_4 "State of charge of brick 14";
CM_ SG_ 2630877188 BATT_socBrick13_4 "State of charge of brick 13";
CM_ BO_ 2630877189 "State of charge of bricks 13-14";
CM_ SG_ 2630877189 BATT_socState_5 "SOC State";
CM_ SG_ 2630877189 BATT_socLoLimit_5 "SOC Low Limit Mask";
CM_ SG_ 2630877189 BATT_socHiLimit_5 "SOC Low Limit Mask";
CM_ SG_ 2630877189 BATT_socBrick14_5 "State of charge of brick 14";
CM_ SG_ 2630877189 BATT_socBrick13_5 "State of charge of brick 13";
CM_ BO_ 2630877190 "State of charge of bricks 13-14";
CM_ SG_ 2630877190 BATT_socState_6 "SOC State";
CM_ SG_ 2630877190 BATT_socLoLimit_6 "SOC Low Limit Mask";
CM_ SG_ 2630877190 BATT_socHiLimit_6 "SOC Low Limit Mask";
CM_ SG_ 2630877190 BATT_socBrick14_6 "State of charge of brick 14";
CM_ SG_ 2630877190 BATT_socBrick13_6 "State of charge of brick 13";
CM_ BO_ 2630877191 "State of charge of bricks 13-14";
CM_ SG_ 2630877191 BATT_socState_7 "SOC State";
CM_ SG_ 2630877191 BATT_socLoLimit_7 "SOC Low Limit Mask";
CM_ SG_ 2630877191 BATT_socHiLimit_7 "SOC Low Limit Mask";
CM_ SG_ 2630877191 BATT_socBrick14_7 "State of charge of brick 14";
CM_ SG_ 2630877191 BATT_socBrick13_7 "State of charge of brick 13";
CM_ SG_ 2643001344 BATT_deltaQTaskOsTimeDelta "Delta Q Charger Task OS Time Delta";
CM_ SG_ 2643001344 BATT_deltaQTaskOsTime "Delta Q Charger Task OS Time";
CM_ SG_ 2643001344 BATT_deltaQFifoWaterMark "Delta Q Charger Event Queue Water Mark";
CM_ SG_ 2643001344 BATT_deltaQFifoSizeUsed "Delta Q Charger Event Queue Size Used";
CM_ SG_ 2643001344 BATT_deltaQEvent "Delta Q Charger Event";
CM_ SG_ 2643001344 BATT_deltaQError "Delta Q Charger Error";
CM_ SG_ 2643001344 BATT_deltaQState "Delta Q Charger State";
CM_ BO_ 2671771648 "ADC 1 message just for inhouse testing";
CM_ BO_ 2671771649 "ADC 1 message just for inhouse testing";
CM_ BO_ 2671771650 "ADC 1 message just for inhouse testing";
CM_ BO_ 2671771651 "ADC 1 message just for inhouse testing";
CM_ BO_ 2671771652 "ADC 1 message just for inhouse testing";
CM_ BO_ 2671771653 "ADC 1 message just for inhouse testing";
CM_ BO_ 2671771654 "ADC 1 message just for inhouse testing";
CM_ BO_ 2671771655 "ADC 1 message just for inhouse testing";
CM_ BO_ 2672033792 "ADC 1 message just for inhouse testing";
CM_ BO_ 2672033793 "ADC 1 message just for inhouse testing";
CM_ BO_ 2672033794 "ADC 1 message just for inhouse testing";
CM_ BO_ 2672033795 "ADC 1 message just for inhouse testing";
CM_ BO_ 2672033796 "ADC 1 message just for inhouse testing";
CM_ BO_ 2672033797 "ADC 1 message just for inhouse testing";
CM_ BO_ 2672033798 "ADC 1 message just for inhouse testing";
CM_ BO_ 2672033799 "ADC 1 message just for inhouse testing";
CM_ BO_ 2672295936 "ADC 1 message just for inhouse testing";
CM_ BO_ 2672295937 "ADC 1 message just for inhouse testing";
CM_ BO_ 2672295938 "ADC 1 message just for inhouse testing";
CM_ BO_ 2672295939 "ADC 1 message just for inhouse testing";
CM_ BO_ 2672295940 "ADC 1 message just for inhouse testing";
CM_ BO_ 2672295941 "ADC 1 message just for inhouse testing";
CM_ BO_ 2672295942 "ADC 1 message just for inhouse testing";
CM_ BO_ 2672295943 "ADC 1 message just for inhouse testing";

BA_DEF_ BO_  "GenMsgDiag" ENUM "No","Yes";
BA_DEF_ BO_  "GenMsgInstanced" STRING ;
BA_DEF_ SG_  "GenSigType" ENUM "Extended","Diagnostic","Standard","Modified";
BA_DEF_ BO_  "GenMsgCycleTime" INT 0 0;
BA_DEF_ SG_  "GenSigSNA" INT 0 65535;
BA_DEF_ SG_  "Access" ENUM "r","rw";
BA_DEF_DEF_  "GenMsgDiag" "No";
BA_DEF_DEF_  "GenMsgInstanced" "No";
BA_DEF_DEF_  "GenSigType" "Standard";
BA_DEF_DEF_  "GenMsgCycleTime" 0;
BA_DEF_DEF_  "GenSigSNA" 0;
BA_DEF_DEF_  "Access" "r";
BA_ "GenMsgDiag" BO_ 2626158596 1;
BA_ "GenMsgDiag" BO_ 2626158597 1;
BA_ "GenMsgDiag" BO_ 2626158598 1;
BA_ "GenMsgDiag" BO_ 2626158599 1;
BA_ "GenMsgDiag" BO_ 2626748416 1;
BA_ "GenMsgDiag" BO_ 2626748417 1;
BA_ "GenMsgDiag" BO_ 2626748418 1;
BA_ "GenMsgDiag" BO_ 2626748419 1;
BA_ "GenMsgDiag" BO_ 2626748420 1;
BA_ "GenMsgDiag" BO_ 2626748421 1;
BA_ "GenMsgDiag" BO_ 2626748422 1;
BA_ "GenMsgDiag" BO_ 2626748423 1;
BA_ "GenMsgDiag" BO_ 2626813952 1;
BA_ "GenMsgDiag" BO_ 2626813953 1;
BA_ "GenMsgDiag" BO_ 2626813954 1;
BA_ "GenMsgDiag" BO_ 2626813955 1;
BA_ "GenMsgDiag" BO_ 2626813956 1;
BA_ "GenMsgDiag" BO_ 2626813957 1;
BA_ "GenMsgDiag" BO_ 2626813958 1;
BA_ "GenMsgDiag" BO_ 2626813959 1;
BA_ "GenMsgDiag" BO_ 2626818048 1;
BA_ "GenMsgDiag" BO_ 2626818049 1;
BA_ "GenMsgDiag" BO_ 2626818050 1;
BA_ "GenMsgDiag" BO_ 2626818051 1;
BA_ "GenMsgDiag" BO_ 2626818052 1;
BA_ "GenMsgDiag" BO_ 2626818053 1;
BA_ "GenMsgDiag" BO_ 2626818054 1;
BA_ "GenMsgDiag" BO_ 2626818055 1;
BA_ "GenMsgDiag" BO_ 2626822144 1;
BA_ "GenMsgDiag" BO_ 2626822145 1;
BA_ "GenMsgDiag" BO_ 2626822146 1;
BA_ "GenMsgDiag" BO_ 2626822147 1;
BA_ "GenMsgDiag" BO_ 2626822148 1;
BA_ "GenMsgDiag" BO_ 2626822149 1;
BA_ "GenMsgDiag" BO_ 2626822150 1;
BA_ "GenMsgDiag" BO_ 2626822151 1;
BA_ "GenMsgDiag" BO_ 2626826240 1;
BA_ "GenMsgDiag" BO_ 2626826241 1;
BA_ "GenMsgDiag" BO_ 2626826242 1;
BA_ "GenMsgDiag" BO_ 2626826243 1;
BA_ "GenMsgDiag" BO_ 2626826244 1;
BA_ "GenMsgDiag" BO_ 2626826245 1;
BA_ "GenMsgDiag" BO_ 2626826246 1;
BA_ "GenMsgDiag" BO_ 2626826247 1;
BA_ "GenMsgDiag" BO_ 2629828608 1;
BA_ "GenMsgDiag" BO_ 2629828609 1;
BA_ "GenMsgDiag" BO_ 2629828610 1;
BA_ "GenMsgDiag" BO_ 2629828611 1;
BA_ "GenMsgDiag" BO_ 2629828612 1;
BA_ "GenMsgDiag" BO_ 2629828613 1;
BA_ "GenMsgDiag" BO_ 2629828614 1;
BA_ "GenMsgDiag" BO_ 2629828615 1;
BA_ "GenMsgDiag" BO_ 2630090752 1;
BA_ "GenMsgDiag" BO_ 2630090753 1;
BA_ "GenMsgDiag" BO_ 2630090754 1;
BA_ "GenMsgDiag" BO_ 2630090755 1;
BA_ "GenMsgDiag" BO_ 2630090756 1;
BA_ "GenMsgDiag" BO_ 2630090757 1;
BA_ "GenMsgDiag" BO_ 2630090758 1;
BA_ "GenMsgDiag" BO_ 2630090759 1;
BA_ "GenMsgDiag" BO_ 2630352896 1;
BA_ "GenMsgDiag" BO_ 2630352897 1;
BA_ "GenMsgDiag" BO_ 2630352898 1;
BA_ "GenMsgDiag" BO_ 2630352899 1;
BA_ "GenMsgDiag" BO_ 2630352900 1;
BA_ "GenMsgDiag" BO_ 2630352901 1;
BA_ "GenMsgDiag" BO_ 2630352902 1;
BA_ "GenMsgDiag" BO_ 2630352903 1;
BA_ "GenMsgDiag" BO_ 2630615040 1;
BA_ "GenMsgDiag" BO_ 2630615041 1;
BA_ "GenMsgDiag" BO_ 2630615042 1;
BA_ "GenMsgDiag" BO_ 2630615043 1;
BA_ "GenMsgDiag" BO_ 2630615044 1;
BA_ "GenMsgDiag" BO_ 2630615045 1;
BA_ "GenMsgDiag" BO_ 2630615046 1;
BA_ "GenMsgDiag" BO_ 2630615047 1;
BA_ "GenMsgDiag" BO_ 2630877184 1;
BA_ "GenMsgDiag" BO_ 2630877185 1;
BA_ "GenMsgDiag" BO_ 2630877186 1;
BA_ "GenMsgDiag" BO_ 2630877187 1;
BA_ "GenMsgDiag" BO_ 2630877188 1;
BA_ "GenMsgDiag" BO_ 2630877189 1;
BA_ "GenMsgDiag" BO_ 2630877190 1;
BA_ "GenMsgDiag" BO_ 2630877191 1;
BA_ "GenMsgDiag" BO_ 2671771648 1;
BA_ "GenMsgDiag" BO_ 2671771649 1;
BA_ "GenMsgDiag" BO_ 2671771650 1;
BA_ "GenMsgDiag" BO_ 2671771651 1;
BA_ "GenMsgDiag" BO_ 2671771652 1;
BA_ "GenMsgDiag" BO_ 2671771653 1;
BA_ "GenMsgDiag" BO_ 2671771654 1;
BA_ "GenMsgDiag" BO_ 2671771655 1;
BA_ "GenMsgDiag" BO_ 2672033792 1;
BA_ "GenMsgDiag" BO_ 2672033793 1;
BA_ "GenMsgDiag" BO_ 2672033794 1;
BA_ "GenMsgDiag" BO_ 2672033795 1;
BA_ "GenMsgDiag" BO_ 2672033796 1;
BA_ "GenMsgDiag" BO_ 2672033797 1;
BA_ "GenMsgDiag" BO_ 2672033798 1;
BA_ "GenMsgDiag" BO_ 2672033799 1;
BA_ "GenMsgDiag" BO_ 2672295936 1;
BA_ "GenMsgDiag" BO_ 2672295937 1;
BA_ "GenMsgDiag" BO_ 2672295938 1;
BA_ "GenMsgDiag" BO_ 2672295939 1;
BA_ "GenMsgDiag" BO_ 2672295940 1;
BA_ "GenMsgDiag" BO_ 2672295941 1;
BA_ "GenMsgDiag" BO_ 2672295942 1;
BA_ "GenMsgDiag" BO_ 2672295943 1;
BA_ "GenMsgInstanced" BO_ 2626158596 "False";
BA_ "GenMsgInstanced" BO_ 2626158597 "False";
BA_ "GenMsgInstanced" BO_ 2626158598 "False";
BA_ "GenMsgInstanced" BO_ 2626158599 "False";
BA_ "GenMsgInstanced" BO_ 2626420736 "False";
BA_ "GenMsgInstanced" BO_ 2626420737 "False";
BA_ "GenMsgInstanced" BO_ 2626420738 "False";
BA_ "GenMsgInstanced" BO_ 2626420739 "False";
BA_ "GenMsgInstanced" BO_ 2626420740 "False";
BA_ "GenMsgInstanced" BO_ 2626420741 "False";
BA_ "GenMsgInstanced" BO_ 2626420742 "False";
BA_ "GenMsgInstanced" BO_ 2626420743 "False";
BA_ "GenMsgInstanced" BO_ 2626682880 "False";
BA_ "GenMsgInstanced" BO_ 2626682881 "False";
BA_ "GenMsgInstanced" BO_ 2626682882 "False";
BA_ "GenMsgInstanced" BO_ 2626682883 "False";
BA_ "GenMsgInstanced" BO_ 2626682884 "False";
BA_ "GenMsgInstanced" BO_ 2626682885 "False";
BA_ "GenMsgInstanced" BO_ 2626682886 "False";
BA_ "GenMsgInstanced" BO_ 2626682887 "False";
BA_ "GenMsgInstanced" BO_ 2626748416 "False";
BA_ "GenMsgInstanced" BO_ 2626748417 "False";
BA_ "GenMsgInstanced" BO_ 2626748418 "False";
BA_ "GenMsgInstanced" BO_ 2626748419 "False";
BA_ "GenMsgInstanced" BO_ 2626748420 "False";
BA_ "GenMsgInstanced" BO_ 2626748421 "False";
BA_ "GenMsgInstanced" BO_ 2626748422 "False";
BA_ "GenMsgInstanced" BO_ 2626748423 "False";
BA_ "GenMsgInstanced" BO_ 2626813952 "False";
BA_ "GenMsgInstanced" BO_ 2626813953 "False";
BA_ "GenMsgInstanced" BO_ 2626813954 "False";
BA_ "GenMsgInstanced" BO_ 2626813955 "False";
BA_ "GenMsgInstanced" BO_ 2626813956 "False";
BA_ "GenMsgInstanced" BO_ 2626813957 "False";
BA_ "GenMsgInstanced" BO_ 2626813958 "False";
BA_ "GenMsgInstanced" BO_ 2626813959 "False";
BA_ "GenMsgInstanced" BO_ 2626818048 "False";
BA_ "GenMsgInstanced" BO_ 2626818049 "False";
BA_ "GenMsgInstanced" BO_ 2626818050 "False";
BA_ "GenMsgInstanced" BO_ 2626818051 "False";
BA_ "GenMsgInstanced" BO_ 2626818052 "False";
BA_ "GenMsgInstanced" BO_ 2626818053 "False";
BA_ "GenMsgInstanced" BO_ 2626818054 "False";
BA_ "GenMsgInstanced" BO_ 2626818055 "False";
BA_ "GenMsgInstanced" BO_ 2626822144 "False";
BA_ "GenMsgInstanced" BO_ 2626822145 "False";
BA_ "GenMsgInstanced" BO_ 2626822146 "False";
BA_ "GenMsgInstanced" BO_ 2626822147 "False";
BA_ "GenMsgInstanced" BO_ 2626822148 "False";
BA_ "GenMsgInstanced" BO_ 2626822149 "False";
BA_ "GenMsgInstanced" BO_ 2626822150 "False";
BA_ "GenMsgInstanced" BO_ 2626822151 "False";
BA_ "GenMsgInstanced" BO_ 2626826240 "False";
BA_ "GenMsgInstanced" BO_ 2626826241 "False";
BA_ "GenMsgInstanced" BO_ 2626826242 "False";
BA_ "GenMsgInstanced" BO_ 2626826243 "False";
BA_ "GenMsgInstanced" BO_ 2626826244 "False";
BA_ "GenMsgInstanced" BO_ 2626826245 "False";
BA_ "GenMsgInstanced" BO_ 2626826246 "False";
BA_ "GenMsgInstanced" BO_ 2626826247 "False";
BA_ "GenMsgInstanced" BO_ 2626945024 "False";
BA_ "GenMsgInstanced" BO_ 2626945025 "False";
BA_ "GenMsgInstanced" BO_ 2626945026 "False";
BA_ "GenMsgInstanced" BO_ 2626945027 "False";
BA_ "GenMsgInstanced" BO_ 2626945028 "False";
BA_ "GenMsgInstanced" BO_ 2626945029 "False";
BA_ "GenMsgInstanced" BO_ 2626945030 "False";
BA_ "GenMsgInstanced" BO_ 2626945031 "False";
BA_ "GenMsgInstanced" BO_ 2629828608 "False";
BA_ "GenMsgInstanced" BO_ 2629828609 "False";
BA_ "GenMsgInstanced" BO_ 2629828610 "False";
BA_ "GenMsgInstanced" BO_ 2629828611 "False";
BA_ "GenMsgInstanced" BO_ 2629828612 "False";
BA_ "GenMsgInstanced" BO_ 2629828613 "False";
BA_ "GenMsgInstanced" BO_ 2629828614 "False";
BA_ "GenMsgInstanced" BO_ 2629828615 "False";
BA_ "GenMsgInstanced" BO_ 2630090752 "False";
BA_ "GenMsgInstanced" BO_ 2630090753 "False";
BA_ "GenMsgInstanced" BO_ 2630090754 "False";
BA_ "GenMsgInstanced" BO_ 2630090755 "False";
BA_ "GenMsgInstanced" BO_ 2630090756 "False";
BA_ "GenMsgInstanced" BO_ 2630090757 "False";
BA_ "GenMsgInstanced" BO_ 2630090758 "False";
BA_ "GenMsgInstanced" BO_ 2630090759 "False";
BA_ "GenMsgInstanced" BO_ 2630352896 "False";
BA_ "GenMsgInstanced" BO_ 2630352897 "False";
BA_ "GenMsgInstanced" BO_ 2630352898 "False";
BA_ "GenMsgInstanced" BO_ 2630352899 "False";
BA_ "GenMsgInstanced" BO_ 2630352900 "False";
BA_ "GenMsgInstanced" BO_ 2630352901 "False";
BA_ "GenMsgInstanced" BO_ 2630352902 "False";
BA_ "GenMsgInstanced" BO_ 2630352903 "False";
BA_ "GenMsgInstanced" BO_ 2630615040 "False";
BA_ "GenMsgInstanced" BO_ 2630615041 "False";
BA_ "GenMsgInstanced" BO_ 2630615042 "False";
BA_ "GenMsgInstanced" BO_ 2630615043 "False";
BA_ "GenMsgInstanced" BO_ 2630615044 "False";
BA_ "GenMsgInstanced" BO_ 2630615045 "False";
BA_ "GenMsgInstanced" BO_ 2630615046 "False";
BA_ "GenMsgInstanced" BO_ 2630615047 "False";
BA_ "GenMsgInstanced" BO_ 2630877184 "False";
BA_ "GenMsgInstanced" BO_ 2630877185 "False";
BA_ "GenMsgInstanced" BO_ 2630877186 "False";
BA_ "GenMsgInstanced" BO_ 2630877187 "False";
BA_ "GenMsgInstanced" BO_ 2630877188 "False";
BA_ "GenMsgInstanced" BO_ 2630877189 "False";
BA_ "GenMsgInstanced" BO_ 2630877190 "False";
BA_ "GenMsgInstanced" BO_ 2630877191 "False";
BA_ "GenMsgInstanced" BO_ 2642411520 "False";
BA_ "GenMsgInstanced" BO_ 2642411521 "False";
BA_ "GenMsgInstanced" BO_ 2642411522 "False";
BA_ "GenMsgInstanced" BO_ 2642411523 "False";
BA_ "GenMsgInstanced" BO_ 2642411524 "False";
BA_ "GenMsgInstanced" BO_ 2642411525 "False";
BA_ "GenMsgInstanced" BO_ 2642411526 "False";
BA_ "GenMsgInstanced" BO_ 2642411527 "False";
BA_ "GenMsgInstanced" BO_ 2642935808 "False";
BA_ "GenMsgInstanced" BO_ 2642935809 "False";
BA_ "GenMsgInstanced" BO_ 2642935810 "False";
BA_ "GenMsgInstanced" BO_ 2642935811 "False";
BA_ "GenMsgInstanced" BO_ 2642935812 "False";
BA_ "GenMsgInstanced" BO_ 2642935813 "False";
BA_ "GenMsgInstanced" BO_ 2642935814 "False";
BA_ "GenMsgInstanced" BO_ 2642935815 "False";
BA_ "GenMsgInstanced" BO_ 2643001344 "False";
BA_ "GenMsgInstanced" BO_ 2671771648 "False";
BA_ "GenMsgInstanced" BO_ 2671771649 "False";
BA_ "GenMsgInstanced" BO_ 2671771650 "False";
BA_ "GenMsgInstanced" BO_ 2671771651 "False";
BA_ "GenMsgInstanced" BO_ 2671771652 "False";
BA_ "GenMsgInstanced" BO_ 2671771653 "False";
BA_ "GenMsgInstanced" BO_ 2671771654 "False";
BA_ "GenMsgInstanced" BO_ 2671771655 "False";
BA_ "GenMsgInstanced" BO_ 2672033792 "False";
BA_ "GenMsgInstanced" BO_ 2672033793 "False";
BA_ "GenMsgInstanced" BO_ 2672033794 "False";
BA_ "GenMsgInstanced" BO_ 2672033795 "False";
BA_ "GenMsgInstanced" BO_ 2672033796 "False";
BA_ "GenMsgInstanced" BO_ 2672033797 "False";
BA_ "GenMsgInstanced" BO_ 2672033798 "False";
BA_ "GenMsgInstanced" BO_ 2672033799 "False";
BA_ "GenMsgInstanced" BO_ 2672295936 "False";
BA_ "GenMsgInstanced" BO_ 2672295937 "False";
BA_ "GenMsgInstanced" BO_ 2672295938 "False";
BA_ "GenMsgInstanced" BO_ 2672295939 "False";
BA_ "GenMsgInstanced" BO_ 2672295940 "False";
BA_ "GenMsgInstanced" BO_ 2672295941 "False";
BA_ "GenMsgInstanced" BO_ 2672295942 "False";
BA_ "GenMsgInstanced" BO_ 2672295943 "False";
BA_ "GenSigType" SG_ 2626158596 BATT_vBrick05_4 1;
BA_ "GenSigType" SG_ 2626158596 BATT_vBrick06_4 1;
BA_ "GenSigType" SG_ 2626158596 BATT_vBrick07_4 1;
BA_ "GenSigType" SG_ 2626158596 BATT_vBrick08_4 1;
BA_ "GenSigType" SG_ 2626158597 BATT_vBrick05_5 1;
BA_ "GenSigType" SG_ 2626158597 BATT_vBrick06_5 1;
BA_ "GenSigType" SG_ 2626158597 BATT_vBrick07_5 1;
BA_ "GenSigType" SG_ 2626158597 BATT_vBrick08_5 1;
BA_ "GenSigType" SG_ 2626158598 BATT_vBrick05_6 1;
BA_ "GenSigType" SG_ 2626158598 BATT_vBrick06_6 1;
BA_ "GenSigType" SG_ 2626158598 BATT_vBrick07_6 1;
BA_ "GenSigType" SG_ 2626158598 BATT_vBrick08_6 1;
BA_ "GenSigType" SG_ 2626158599 BATT_vBrick07_7 1;
BA_ "GenSigType" SG_ 2626158599 BATT_vBrick05_7 1;
BA_ "GenSigType" SG_ 2626158599 BATT_vBrick08_7 1;
BA_ "GenSigType" SG_ 2626158599 BATT_vBrick06_7 1;
BA_ "GenSigType" SG_ 2626420736 BATT_vBrick12_0 1;
BA_ "GenSigType" SG_ 2626420736 BATT_vBrick11_0 1;
BA_ "GenSigType" SG_ 2626420736 BATT_vBrick10_0 1;
BA_ "GenSigType" SG_ 2626420736 BATT_vBrick09_0 1;
BA_ "GenSigType" SG_ 2626420737 BATT_vBrick12_1 1;
BA_ "GenSigType" SG_ 2626420737 BATT_vBrick11_1 1;
BA_ "GenSigType" SG_ 2626420737 BATT_vBrick10_1 1;
BA_ "GenSigType" SG_ 2626420737 BATT_vBrick09_1 1;
BA_ "GenSigType" SG_ 2626420738 BATT_vBrick10_2 1;
BA_ "GenSigType" SG_ 2626420738 BATT_vBrick12_2 1;
BA_ "GenSigType" SG_ 2626420738 BATT_vBrick11_2 1;
BA_ "GenSigType" SG_ 2626420738 BATT_vBrick09_2 1;
BA_ "GenSigType" SG_ 2626420739 BATT_vBrick10_3 1;
BA_ "GenSigType" SG_ 2626420739 BATT_vBrick12_3 1;
BA_ "GenSigType" SG_ 2626420739 BATT_vBrick11_3 1;
BA_ "GenSigType" SG_ 2626420739 BATT_vBrick09_3 1;
BA_ "GenSigType" SG_ 2626420740 BATT_vBrick10_4 1;
BA_ "GenSigType" SG_ 2626420740 BATT_vBrick12_4 1;
BA_ "GenSigType" SG_ 2626420740 BATT_vBrick11_4 1;
BA_ "GenSigType" SG_ 2626420740 BATT_vBrick09_4 1;
BA_ "GenSigType" SG_ 2626420741 BATT_vBrick12_5 1;
BA_ "GenSigType" SG_ 2626420741 BATT_vBrick11_5 1;
BA_ "GenSigType" SG_ 2626420741 BATT_vBrick10_5 1;
BA_ "GenSigType" SG_ 2626420741 BATT_vBrick09_5 1;
BA_ "GenSigType" SG_ 2626420742 BATT_vBrick12_6 1;
BA_ "GenSigType" SG_ 2626420742 BATT_vBrick11_6 1;
BA_ "GenSigType" SG_ 2626420742 BATT_vBrick10_6 1;
BA_ "GenSigType" SG_ 2626420742 BATT_vBrick09_6 1;
BA_ "GenSigType" SG_ 2626420743 BATT_vBrick11_7 1;
BA_ "GenSigType" SG_ 2626420743 BATT_vBrick10_7 1;
BA_ "GenSigType" SG_ 2626420743 BATT_vBrick09_7 1;
BA_ "GenSigType" SG_ 2626420743 BATT_vBrick12_7 1;
BA_ "GenSigType" SG_ 2626682880 BATT_vBrick13_0 1;
BA_ "GenSigType" SG_ 2626682880 BATT_vBrick14_0 1;
BA_ "GenSigType" SG_ 2626682881 BATT_vBrick14_1 1;
BA_ "GenSigType" SG_ 2626682881 BATT_vBrick13_1 1;
BA_ "GenSigType" SG_ 2626682882 BATT_vBrick13_2 1;
BA_ "GenSigType" SG_ 2626682882 BATT_vBrick14_2 1;
BA_ "GenSigType" SG_ 2626682883 BATT_vBrick13_3 1;
BA_ "GenSigType" SG_ 2626682883 BATT_vBrick14_3 1;
BA_ "GenSigType" SG_ 2626682884 BATT_vBrick13_4 1;
BA_ "GenSigType" SG_ 2626682884 BATT_vBrick14_4 1;
BA_ "GenSigType" SG_ 2626682885 BATT_vBrick14_5 1;
BA_ "GenSigType" SG_ 2626682885 BATT_vBrick13_5 1;
BA_ "GenSigType" SG_ 2626682886 BATT_vBrick14_6 1;
BA_ "GenSigType" SG_ 2626682886 BATT_vBrick13_6 1;
BA_ "GenSigType" SG_ 2626682887 BATT_vBrick13_7 1;
BA_ "GenSigType" SG_ 2626682887 BATT_vBrick14_7 1;
BA_ "GenSigType" SG_ 2626748416 BATT_HarnessImpedance_9_0 1;
BA_ "GenSigType" SG_ 2626748416 BATT_HarnessImpedance_8_0 1;
BA_ "GenSigType" SG_ 2626748416 BATT_HarnessImpedance_0_0 1;
BA_ "GenSigType" SG_ 2626748416 BATT_HarnessImpedance_13_0 1;
BA_ "GenSigType" SG_ 2626748416 BATT_HarnessImpedance_12_0 1;
BA_ "GenSigType" SG_ 2626748416 BATT_HarnessImpedance_11_0 1;
BA_ "GenSigType" SG_ 2626748416 BATT_HarnessImpedance_10_0 1;
BA_ "GenSigType" SG_ 2626748416 BATT_HarnessImpedance_2_0 1;
BA_ "GenSigType" SG_ 2626748416 BATT_HarnessImpedance_1_0 1;
BA_ "GenSigType" SG_ 2626748416 BATT_HarnessImpedance_5_0 1;
BA_ "GenSigType" SG_ 2626748416 BATT_HarnessImpedance_14_0 1;
BA_ "GenSigType" SG_ 2626748416 BATT_HarnessImpedance_4_0 1;
BA_ "GenSigType" SG_ 2626748416 BATT_HarnessImpedance_3_0 1;
BA_ "GenSigType" SG_ 2626748416 BATT_HarnessImpedance_7_0 1;
BA_ "GenSigType" SG_ 2626748416 BATT_HarnessImpedance_6_0 1;
BA_ "GenSigType" SG_ 2626748417 BATT_HarnessImpedance_14_1 1;
BA_ "GenSigType" SG_ 2626748417 BATT_HarnessImpedance_8_1 1;
BA_ "GenSigType" SG_ 2626748417 BATT_HarnessImpedance_7_1 1;
BA_ "GenSigType" SG_ 2626748417 BATT_HarnessImpedance_11_1 1;
BA_ "GenSigType" SG_ 2626748417 BATT_HarnessImpedance_10_1 1;
BA_ "GenSigType" SG_ 2626748417 BATT_HarnessImpedance_9_1 1;
BA_ "GenSigType" SG_ 2626748417 BATT_HarnessImpedance_0_1 1;
BA_ "GenSigType" SG_ 2626748417 BATT_HarnessImpedance_13_1 1;
BA_ "GenSigType" SG_ 2626748417 BATT_HarnessImpedance_12_1 1;
BA_ "GenSigType" SG_ 2626748417 BATT_HarnessImpedance_2_1 1;
BA_ "GenSigType" SG_ 2626748417 BATT_HarnessImpedance_1_1 1;
BA_ "GenSigType" SG_ 2626748417 BATT_HarnessImpedance_4_1 1;
BA_ "GenSigType" SG_ 2626748417 BATT_HarnessImpedance_3_1 1;
BA_ "GenSigType" SG_ 2626748417 BATT_HarnessImpedance_6_1 1;
BA_ "GenSigType" SG_ 2626748417 BATT_HarnessImpedance_5_1 1;
BA_ "GenSigType" SG_ 2626748418 BATT_HarnessImpedance_14_2 1;
BA_ "GenSigType" SG_ 2626748418 BATT_HarnessImpedance_13_2 1;
BA_ "GenSigType" SG_ 2626748418 BATT_HarnessImpedance_12_2 1;
BA_ "GenSigType" SG_ 2626748418 BATT_HarnessImpedance_11_2 1;
BA_ "GenSigType" SG_ 2626748418 BATT_HarnessImpedance_10_2 1;
BA_ "GenSigType" SG_ 2626748418 BATT_HarnessImpedance_9_2 1;
BA_ "GenSigType" SG_ 2626748418 BATT_HarnessImpedance_8_2 1;
BA_ "GenSigType" SG_ 2626748418 BATT_HarnessImpedance_7_2 1;
BA_ "GenSigType" SG_ 2626748418 BATT_HarnessImpedance_6_2 1;
BA_ "GenSigType" SG_ 2626748418 BATT_HarnessImpedance_5_2 1;
BA_ "GenSigType" SG_ 2626748418 BATT_HarnessImpedance_4_2 1;
BA_ "GenSigType" SG_ 2626748418 BATT_HarnessImpedance_3_2 1;
BA_ "GenSigType" SG_ 2626748418 BATT_HarnessImpedance_2_2 1;
BA_ "GenSigType" SG_ 2626748418 BATT_HarnessImpedance_1_2 1;
BA_ "GenSigType" SG_ 2626748418 BATT_HarnessImpedance_0_2 1;
BA_ "GenSigType" SG_ 2626748419 BATT_HarnessImpedance_14_3 1;
BA_ "GenSigType" SG_ 2626748419 BATT_HarnessImpedance_13_3 1;
BA_ "GenSigType" SG_ 2626748419 BATT_HarnessImpedance_12_3 1;
BA_ "GenSigType" SG_ 2626748419 BATT_HarnessImpedance_11_3 1;
BA_ "GenSigType" SG_ 2626748419 BATT_HarnessImpedance_10_3 1;
BA_ "GenSigType" SG_ 2626748419 BATT_HarnessImpedance_9_3 1;
BA_ "GenSigType" SG_ 2626748419 BATT_HarnessImpedance_8_3 1;
BA_ "GenSigType" SG_ 2626748419 BATT_HarnessImpedance_7_3 1;
BA_ "GenSigType" SG_ 2626748419 BATT_HarnessImpedance_6_3 1;
BA_ "GenSigType" SG_ 2626748419 BATT_HarnessImpedance_1_3 1;
BA_ "GenSigType" SG_ 2626748419 BATT_HarnessImpedance_5_3 1;
BA_ "GenSigType" SG_ 2626748419 BATT_HarnessImpedance_4_3 1;
BA_ "GenSigType" SG_ 2626748419 BATT_HarnessImpedance_3_3 1;
BA_ "GenSigType" SG_ 2626748419 BATT_HarnessImpedance_2_3 1;
BA_ "GenSigType" SG_ 2626748419 BATT_HarnessImpedance_0_3 1;
BA_ "GenSigType" SG_ 2626748420 BATT_HarnessImpedance_0_4 1;
BA_ "GenSigType" SG_ 2626748420 BATT_HarnessImpedance_2_4 1;
BA_ "GenSigType" SG_ 2626748420 BATT_HarnessImpedance_1_4 1;
BA_ "GenSigType" SG_ 2626748420 BATT_HarnessImpedance_5_4 1;
BA_ "GenSigType" SG_ 2626748420 BATT_HarnessImpedance_4_4 1;
BA_ "GenSigType" SG_ 2626748420 BATT_HarnessImpedance_3_4 1;
BA_ "GenSigType" SG_ 2626748420 BATT_HarnessImpedance_7_4 1;
BA_ "GenSigType" SG_ 2626748420 BATT_HarnessImpedance_6_4 1;
BA_ "GenSigType" SG_ 2626748420 BATT_HarnessImpedance_9_4 1;
BA_ "GenSigType" SG_ 2626748420 BATT_HarnessImpedance_8_4 1;
BA_ "GenSigType" SG_ 2626748420 BATT_HarnessImpedance_11_4 1;
BA_ "GenSigType" SG_ 2626748420 BATT_HarnessImpedance_10_4 1;
BA_ "GenSigType" SG_ 2626748420 BATT_HarnessImpedance_13_4 1;
BA_ "GenSigType" SG_ 2626748420 BATT_HarnessImpedance_12_4 1;
BA_ "GenSigType" SG_ 2626748420 BATT_HarnessImpedance_14_4 1;
BA_ "GenSigType" SG_ 2626748421 BATT_HarnessImpedance_11_5 1;
BA_ "GenSigType" SG_ 2626748421 BATT_HarnessImpedance_10_5 1;
BA_ "GenSigType" SG_ 2626748421 BATT_HarnessImpedance_7_5 1;
BA_ "GenSigType" SG_ 2626748421 BATT_HarnessImpedance_6_5 1;
BA_ "GenSigType" SG_ 2626748421 BATT_HarnessImpedance_13_5 1;
BA_ "GenSigType" SG_ 2626748421 BATT_HarnessImpedance_12_5 1;
BA_ "GenSigType" SG_ 2626748421 BATT_HarnessImpedance_9_5 1;
BA_ "GenSigType" SG_ 2626748421 BATT_HarnessImpedance_8_5 1;
BA_ "GenSigType" SG_ 2626748421 BATT_HarnessImpedance_14_5 1;
BA_ "GenSigType" SG_ 2626748421 BATT_HarnessImpedance_1_5 1;
BA_ "GenSigType" SG_ 2626748421 BATT_HarnessImpedance_0_5 1;
BA_ "GenSigType" SG_ 2626748421 BATT_HarnessImpedance_3_5 1;
BA_ "GenSigType" SG_ 2626748421 BATT_HarnessImpedance_2_5 1;
BA_ "GenSigType" SG_ 2626748421 BATT_HarnessImpedance_5_5 1;
BA_ "GenSigType" SG_ 2626748421 BATT_HarnessImpedance_4_5 1;
BA_ "GenSigType" SG_ 2626748422 BATT_HarnessImpedance_9_6 1;
BA_ "GenSigType" SG_ 2626748422 BATT_HarnessImpedance_8_6 1;
BA_ "GenSigType" SG_ 2626748422 BATT_HarnessImpedance_12_6 1;
BA_ "GenSigType" SG_ 2626748422 BATT_HarnessImpedance_11_6 1;
BA_ "GenSigType" SG_ 2626748422 BATT_HarnessImpedance_10_6 1;
BA_ "GenSigType" SG_ 2626748422 BATT_HarnessImpedance_14_6 1;
BA_ "GenSigType" SG_ 2626748422 BATT_HarnessImpedance_13_6 1;
BA_ "GenSigType" SG_ 2626748422 BATT_HarnessImpedance_7_6 1;
BA_ "GenSigType" SG_ 2626748422 BATT_HarnessImpedance_6_6 1;
BA_ "GenSigType" SG_ 2626748422 BATT_HarnessImpedance_3_6 1;
BA_ "GenSigType" SG_ 2626748422 BATT_HarnessImpedance_2_6 1;
BA_ "GenSigType" SG_ 2626748422 BATT_HarnessImpedance_0_6 1;
BA_ "GenSigType" SG_ 2626748422 BATT_HarnessImpedance_1_6 1;
BA_ "GenSigType" SG_ 2626748422 BATT_HarnessImpedance_5_6 1;
BA_ "GenSigType" SG_ 2626748422 BATT_HarnessImpedance_4_6 1;
BA_ "GenSigType" SG_ 2626748423 BATT_HarnessImpedance_13_7 1;
BA_ "GenSigType" SG_ 2626748423 BATT_HarnessImpedance_14_7 1;
BA_ "GenSigType" SG_ 2626748423 BATT_HarnessImpedance_5_7 1;
BA_ "GenSigType" SG_ 2626748423 BATT_HarnessImpedance_12_7 1;
BA_ "GenSigType" SG_ 2626748423 BATT_HarnessImpedance_4_7 1;
BA_ "GenSigType" SG_ 2626748423 BATT_HarnessImpedance_7_7 1;
BA_ "GenSigType" SG_ 2626748423 BATT_HarnessImpedance_6_7 1;
BA_ "GenSigType" SG_ 2626748423 BATT_HarnessImpedance_9_7 1;
BA_ "GenSigType" SG_ 2626748423 BATT_HarnessImpedance_1_7 1;
BA_ "GenSigType" SG_ 2626748423 BATT_HarnessImpedance_8_7 1;
BA_ "GenSigType" SG_ 2626748423 BATT_HarnessImpedance_0_7 1;
BA_ "GenSigType" SG_ 2626748423 BATT_HarnessImpedance_11_7 1;
BA_ "GenSigType" SG_ 2626748423 BATT_HarnessImpedance_3_7 1;
BA_ "GenSigType" SG_ 2626748423 BATT_HarnessImpedance_10_7 1;
BA_ "GenSigType" SG_ 2626748423 BATT_HarnessImpedance_2_7 1;
BA_ "GenSigType" SG_ 2626813952 BATT_HrnsImpDelta_1_0 1;
BA_ "GenSigType" SG_ 2626813952 BATT_HrnsImpDelta_3_0 1;
BA_ "GenSigType" SG_ 2626813952 BATT_HrnsImpDelta_2_0 1;
BA_ "GenSigType" SG_ 2626813952 BATT_HrnsImpDelta_0_0 1;
BA_ "GenSigType" SG_ 2626813953 BATT_HrnsImpDelta_1_1 1;
BA_ "GenSigType" SG_ 2626813953 BATT_HrnsImpDelta_0_1 1;
BA_ "GenSigType" SG_ 2626813953 BATT_HrnsImpDelta_2_1 1;
BA_ "GenSigType" SG_ 2626813953 BATT_HrnsImpDelta_3_1 1;
BA_ "GenSigType" SG_ 2626813954 BATT_HrnsImpDelta_0_2 1;
BA_ "GenSigType" SG_ 2626813954 BATT_HrnsImpDelta_1_2 1;
BA_ "GenSigType" SG_ 2626813954 BATT_HrnsImpDelta_2_2 1;
BA_ "GenSigType" SG_ 2626813954 BATT_HrnsImpDelta_3_2 1;
BA_ "GenSigType" SG_ 2626813955 BATT_HrnsImpDelta_3_3 1;
BA_ "GenSigType" SG_ 2626813955 BATT_HrnsImpDelta_2_3 1;
BA_ "GenSigType" SG_ 2626813955 BATT_HrnsImpDelta_0_3 1;
BA_ "GenSigType" SG_ 2626813955 BATT_HrnsImpDelta_1_3 1;
BA_ "GenSigType" SG_ 2626813956 BATT_HrnsImpDelta_0_4 1;
BA_ "GenSigType" SG_ 2626813956 BATT_HrnsImpDelta_3_4 1;
BA_ "GenSigType" SG_ 2626813956 BATT_HrnsImpDelta_1_4 1;
BA_ "GenSigType" SG_ 2626813956 BATT_HrnsImpDelta_2_4 1;
BA_ "GenSigType" SG_ 2626813957 BATT_HrnsImpDelta_0_5 1;
BA_ "GenSigType" SG_ 2626813957 BATT_HrnsImpDelta_3_5 1;
BA_ "GenSigType" SG_ 2626813957 BATT_HrnsImpDelta_2_5 1;
BA_ "GenSigType" SG_ 2626813957 BATT_HrnsImpDelta_1_5 1;
BA_ "GenSigType" SG_ 2626813958 BATT_HrnsImpDelta_2_6 1;
BA_ "GenSigType" SG_ 2626813958 BATT_HrnsImpDelta_3_6 1;
BA_ "GenSigType" SG_ 2626813958 BATT_HrnsImpDelta_1_6 1;
BA_ "GenSigType" SG_ 2626813958 BATT_HrnsImpDelta_0_6 1;
BA_ "GenSigType" SG_ 2626813959 BATT_HrnsImpDelta_0_7 1;
BA_ "GenSigType" SG_ 2626813959 BATT_HrnsImpDelta_3_7 1;
BA_ "GenSigType" SG_ 2626813959 BATT_HrnsImpDelta_1_7 1;
BA_ "GenSigType" SG_ 2626813959 BATT_HrnsImpDelta_2_7 1;
BA_ "GenSigType" SG_ 2626818048 BATT_HrnsImpDelta_5_0 1;
BA_ "GenSigType" SG_ 2626818048 BATT_HrnsImpDelta_7_0 1;
BA_ "GenSigType" SG_ 2626818048 BATT_HrnsImpDelta_6_0 1;
BA_ "GenSigType" SG_ 2626818048 BATT_HrnsImpDelta_4_0 1;
BA_ "GenSigType" SG_ 2626818049 BATT_HrnsImpDelta_7_1 1;
BA_ "GenSigType" SG_ 2626818049 BATT_HrnsImpDelta_4_1 1;
BA_ "GenSigType" SG_ 2626818049 BATT_HrnsImpDelta_5_1 1;
BA_ "GenSigType" SG_ 2626818049 BATT_HrnsImpDelta_6_1 1;
BA_ "GenSigType" SG_ 2626818050 BATT_HrnsImpDelta_6_2 1;
BA_ "GenSigType" SG_ 2626818050 BATT_HrnsImpDelta_5_2 1;
BA_ "GenSigType" SG_ 2626818050 BATT_HrnsImpDelta_7_2 1;
BA_ "GenSigType" SG_ 2626818050 BATT_HrnsImpDelta_4_2 1;
BA_ "GenSigType" SG_ 2626818051 BATT_HrnsImpDelta_4_3 1;
BA_ "GenSigType" SG_ 2626818051 BATT_HrnsImpDelta_5_3 1;
BA_ "GenSigType" SG_ 2626818051 BATT_HrnsImpDelta_6_3 1;
BA_ "GenSigType" SG_ 2626818051 BATT_HrnsImpDelta_7_3 1;
BA_ "GenSigType" SG_ 2626818052 BATT_HrnsImpDelta_6_4 1;
BA_ "GenSigType" SG_ 2626818052 BATT_HrnsImpDelta_7_4 1;
BA_ "GenSigType" SG_ 2626818052 BATT_HrnsImpDelta_4_4 1;
BA_ "GenSigType" SG_ 2626818052 BATT_HrnsImpDelta_5_4 1;
BA_ "GenSigType" SG_ 2626818053 BATT_HrnsImpDelta_6_5 1;
BA_ "GenSigType" SG_ 2626818053 BATT_HrnsImpDelta_4_5 1;
BA_ "GenSigType" SG_ 2626818053 BATT_HrnsImpDelta_5_5 1;
BA_ "GenSigType" SG_ 2626818053 BATT_HrnsImpDelta_7_5 1;
BA_ "GenSigType" SG_ 2626818054 BATT_HrnsImpDelta_4_6 1;
BA_ "GenSigType" SG_ 2626818054 BATT_HrnsImpDelta_5_6 1;
BA_ "GenSigType" SG_ 2626818054 BATT_HrnsImpDelta_7_6 1;
BA_ "GenSigType" SG_ 2626818054 BATT_HrnsImpDelta_6_6 1;
BA_ "GenSigType" SG_ 2626818055 BATT_HrnsImpDelta_5_7 1;
BA_ "GenSigType" SG_ 2626818055 BATT_HrnsImpDelta_7_7 1;
BA_ "GenSigType" SG_ 2626818055 BATT_HrnsImpDelta_6_7 1;
BA_ "GenSigType" SG_ 2626818055 BATT_HrnsImpDelta_4_7 1;
BA_ "GenSigType" SG_ 2626822144 BATT_HrnsImpDelta_11_0 1;
BA_ "GenSigType" SG_ 2626822144 BATT_HrnsImpDelta_9_0 1;
BA_ "GenSigType" SG_ 2626822144 BATT_HrnsImpDelta_10_0 1;
BA_ "GenSigType" SG_ 2626822144 BATT_HrnsImpDelta_8_0 1;
BA_ "GenSigType" SG_ 2626822145 BATT_HrnsImpDelta_11_1 1;
BA_ "GenSigType" SG_ 2626822145 BATT_HrnsImpDelta_10_1 1;
BA_ "GenSigType" SG_ 2626822145 BATT_HrnsImpDelta_9_1 1;
BA_ "GenSigType" SG_ 2626822145 BATT_HrnsImpDelta_8_1 1;
BA_ "GenSigType" SG_ 2626822146 BATT_HrnsImpDelta_8_2 1;
BA_ "GenSigType" SG_ 2626822146 BATT_HrnsImpDelta_11_2 1;
BA_ "GenSigType" SG_ 2626822146 BATT_HrnsImpDelta_10_2 1;
BA_ "GenSigType" SG_ 2626822146 BATT_HrnsImpDelta_9_2 1;
BA_ "GenSigType" SG_ 2626822147 BATT_HrnsImpDelta_8_3 1;
BA_ "GenSigType" SG_ 2626822147 BATT_HrnsImpDelta_11_3 1;
BA_ "GenSigType" SG_ 2626822147 BATT_HrnsImpDelta_10_3 1;
BA_ "GenSigType" SG_ 2626822147 BATT_HrnsImpDelta_9_3 1;
BA_ "GenSigType" SG_ 2626822148 BATT_HrnsImpDelta_8_4 1;
BA_ "GenSigType" SG_ 2626822148 BATT_HrnsImpDelta_9_4 1;
BA_ "GenSigType" SG_ 2626822148 BATT_HrnsImpDelta_10_4 1;
BA_ "GenSigType" SG_ 2626822148 BATT_HrnsImpDelta_11_4 1;
BA_ "GenSigType" SG_ 2626822149 BATT_HrnsImpDelta_10_5 1;
BA_ "GenSigType" SG_ 2626822149 BATT_HrnsImpDelta_11_5 1;
BA_ "GenSigType" SG_ 2626822149 BATT_HrnsImpDelta_8_5 1;
BA_ "GenSigType" SG_ 2626822149 BATT_HrnsImpDelta_9_5 1;
BA_ "GenSigType" SG_ 2626822150 BATT_HrnsImpDelta_10_6 1;
BA_ "GenSigType" SG_ 2626822150 BATT_HrnsImpDelta_8_6 1;
BA_ "GenSigType" SG_ 2626822150 BATT_HrnsImpDelta_9_6 1;
BA_ "GenSigType" SG_ 2626822150 BATT_HrnsImpDelta_11_6 1;
BA_ "GenSigType" SG_ 2626822151 BATT_HrnsImpDelta_8_7 1;
BA_ "GenSigType" SG_ 2626822151 BATT_HrnsImpDelta_11_7 1;
BA_ "GenSigType" SG_ 2626822151 BATT_HrnsImpDelta_10_7 1;
BA_ "GenSigType" SG_ 2626822151 BATT_HrnsImpDelta_9_7 1;
BA_ "GenSigType" SG_ 2626826240 BATT_HrnsImpDelta_14_0 1;
BA_ "GenSigType" SG_ 2626826240 BATT_HrnsImpDelta_13_0 1;
BA_ "GenSigType" SG_ 2626826240 BATT_HrnsImpDelta_12_0 1;
BA_ "GenSigType" SG_ 2626826241 BATT_HrnsImpDelta_13_1 1;
BA_ "GenSigType" SG_ 2626826241 BATT_HrnsImpDelta_12_1 1;
BA_ "GenSigType" SG_ 2626826241 BATT_HrnsImpDelta_14_1 1;
BA_ "GenSigType" SG_ 2626826242 BATT_HrnsImpDelta_12_2 1;
BA_ "GenSigType" SG_ 2626826242 BATT_HrnsImpDelta_14_2 1;
BA_ "GenSigType" SG_ 2626826242 BATT_HrnsImpDelta_13_2 1;
BA_ "GenSigType" SG_ 2626826243 BATT_HrnsImpDelta_13_3 1;
BA_ "GenSigType" SG_ 2626826243 BATT_HrnsImpDelta_14_3 1;
BA_ "GenSigType" SG_ 2626826243 BATT_HrnsImpDelta_12_3 1;
BA_ "GenSigType" SG_ 2626826244 BATT_HrnsImpDelta_14_4 1;
BA_ "GenSigType" SG_ 2626826244 BATT_HrnsImpDelta_12_4 1;
BA_ "GenSigType" SG_ 2626826244 BATT_HrnsImpDelta_13_4 1;
BA_ "GenSigType" SG_ 2626826245 BATT_HrnsImpDelta_12_5 1;
BA_ "GenSigType" SG_ 2626826245 BATT_HrnsImpDelta_13_5 1;
BA_ "GenSigType" SG_ 2626826245 BATT_HrnsImpDelta_14_5 1;
BA_ "GenSigType" SG_ 2626826246 BATT_HrnsImpDelta_12_6 1;
BA_ "GenSigType" SG_ 2626826246 BATT_HrnsImpDelta_13_6 1;
BA_ "GenSigType" SG_ 2626826246 BATT_HrnsImpDelta_14_6 1;
BA_ "GenSigType" SG_ 2626826247 BATT_HrnsImpDelta_12_7 1;
BA_ "GenSigType" SG_ 2626826247 BATT_HrnsImpDelta_13_7 1;
BA_ "GenSigType" SG_ 2626826247 BATT_HrnsImpDelta_14_7 1;
BA_ "GenSigType" SG_ 2629828608 BATT_ahChgTotal_0 1;
BA_ "GenSigType" SG_ 2629828608 BATT_ahDchTotal_0 1;
BA_ "GenSigType" SG_ 2629828609 BATT_ahDchTotal_1 1;
BA_ "GenSigType" SG_ 2629828609 BATT_ahChgTotal_1 1;
BA_ "GenSigType" SG_ 2629828610 BATT_ahDchTotal_2 1;
BA_ "GenSigType" SG_ 2629828610 BATT_ahChgTotal_2 1;
BA_ "GenSigType" SG_ 2629828611 BATT_ahDchTotal_3 1;
BA_ "GenSigType" SG_ 2629828611 BATT_ahChgTotal_3 1;
BA_ "GenSigType" SG_ 2629828612 BATT_ahChgTotal_4 1;
BA_ "GenSigType" SG_ 2629828612 BATT_ahDchTotal_4 1;
BA_ "GenSigType" SG_ 2629828613 BATT_ahChgTotal_5 1;
BA_ "GenSigType" SG_ 2629828613 BATT_ahDchTotal_5 1;
BA_ "GenSigType" SG_ 2629828614 BATT_ahChgTotal_6 1;
BA_ "GenSigType" SG_ 2629828614 BATT_ahDchTotal_6 1;
BA_ "GenSigType" SG_ 2629828615 BATT_ahDchTotal_7 1;
BA_ "GenSigType" SG_ 2629828615 BATT_ahChgTotal_7 1;
BA_ "GenSigType" SG_ 2630090752 BATT_socBrick04_0 1;
BA_ "GenSigType" SG_ 2630090752 BATT_socBrick03_0 1;
BA_ "GenSigType" SG_ 2630090752 BATT_socBrick02_0 1;
BA_ "GenSigType" SG_ 2630090752 BATT_socBrick01_0 1;
BA_ "GenSigType" SG_ 2630090753 BATT_socBrick04_1 1;
BA_ "GenSigType" SG_ 2630090753 BATT_socBrick03_1 1;
BA_ "GenSigType" SG_ 2630090753 BATT_socBrick02_1 1;
BA_ "GenSigType" SG_ 2630090753 BATT_socBrick01_1 1;
BA_ "GenSigType" SG_ 2630090754 BATT_socBrick04_2 1;
BA_ "GenSigType" SG_ 2630090754 BATT_socBrick03_2 1;
BA_ "GenSigType" SG_ 2630090754 BATT_socBrick02_2 1;
BA_ "GenSigType" SG_ 2630090754 BATT_socBrick01_2 1;
BA_ "GenSigType" SG_ 2630090755 BATT_socBrick04_3 1;
BA_ "GenSigType" SG_ 2630090755 BATT_socBrick03_3 1;
BA_ "GenSigType" SG_ 2630090755 BATT_socBrick02_3 1;
BA_ "GenSigType" SG_ 2630090755 BATT_socBrick01_3 1;
BA_ "GenSigType" SG_ 2630090756 BATT_socBrick04_4 1;
BA_ "GenSigType" SG_ 2630090756 BATT_socBrick03_4 1;
BA_ "GenSigType" SG_ 2630090756 BATT_socBrick02_4 1;
BA_ "GenSigType" SG_ 2630090756 BATT_socBrick01_4 1;
BA_ "GenSigType" SG_ 2630090757 BATT_socBrick04_5 1;
BA_ "GenSigType" SG_ 2630090757 BATT_socBrick03_5 1;
BA_ "GenSigType" SG_ 2630090757 BATT_socBrick02_5 1;
BA_ "GenSigType" SG_ 2630090757 BATT_socBrick01_5 1;
BA_ "GenSigType" SG_ 2630090758 BATT_socBrick04_6 1;
BA_ "GenSigType" SG_ 2630090758 BATT_socBrick03_6 1;
BA_ "GenSigType" SG_ 2630090758 BATT_socBrick02_6 1;
BA_ "GenSigType" SG_ 2630090758 BATT_socBrick01_6 1;
BA_ "GenSigType" SG_ 2630090759 BATT_socBrick04_7 1;
BA_ "GenSigType" SG_ 2630090759 BATT_socBrick03_7 1;
BA_ "GenSigType" SG_ 2630090759 BATT_socBrick02_7 1;
BA_ "GenSigType" SG_ 2630090759 BATT_socBrick01_7 1;
BA_ "GenSigType" SG_ 2630352896 BATT_socBrick08_0 1;
BA_ "GenSigType" SG_ 2630352896 BATT_socBrick07_0 1;
BA_ "GenSigType" SG_ 2630352896 BATT_socBrick06_0 1;
BA_ "GenSigType" SG_ 2630352896 BATT_socBrick05_0 1;
BA_ "GenSigType" SG_ 2630352897 BATT_socBrick08_1 1;
BA_ "GenSigType" SG_ 2630352897 BATT_socBrick07_1 1;
BA_ "GenSigType" SG_ 2630352897 BATT_socBrick06_1 1;
BA_ "GenSigType" SG_ 2630352897 BATT_socBrick05_1 1;
BA_ "GenSigType" SG_ 2630352898 BATT_socBrick08_2 1;
BA_ "GenSigType" SG_ 2630352898 BATT_socBrick07_2 1;
BA_ "GenSigType" SG_ 2630352898 BATT_socBrick06_2 1;
BA_ "GenSigType" SG_ 2630352898 BATT_socBrick05_2 1;
BA_ "GenSigType" SG_ 2630352899 BATT_socBrick08_3 1;
BA_ "GenSigType" SG_ 2630352899 BATT_socBrick07_3 1;
BA_ "GenSigType" SG_ 2630352899 BATT_socBrick06_3 1;
BA_ "GenSigType" SG_ 2630352899 BATT_socBrick05_3 1;
BA_ "GenSigType" SG_ 2630352900 BATT_socBrick08_4 1;
BA_ "GenSigType" SG_ 2630352900 BATT_socBrick07_4 1;
BA_ "GenSigType" SG_ 2630352900 BATT_socBrick06_4 1;
BA_ "GenSigType" SG_ 2630352900 BATT_socBrick05_4 1;
BA_ "GenSigType" SG_ 2630352901 BATT_socBrick08_5 1;
BA_ "GenSigType" SG_ 2630352901 BATT_socBrick07_5 1;
BA_ "GenSigType" SG_ 2630352901 BATT_socBrick06_5 1;
BA_ "GenSigType" SG_ 2630352901 BATT_socBrick05_5 1;
BA_ "GenSigType" SG_ 2630352902 BATT_socBrick08_6 1;
BA_ "GenSigType" SG_ 2630352902 BATT_socBrick07_6 1;
BA_ "GenSigType" SG_ 2630352902 BATT_socBrick06_6 1;
BA_ "GenSigType" SG_ 2630352902 BATT_socBrick05_6 1;
BA_ "GenSigType" SG_ 2630352903 BATT_socBrick08_7 1;
BA_ "GenSigType" SG_ 2630352903 BATT_socBrick07_7 1;
BA_ "GenSigType" SG_ 2630352903 BATT_socBrick06_7 1;
BA_ "GenSigType" SG_ 2630352903 BATT_socBrick05_7 1;
BA_ "GenSigType" SG_ 2630615040 BATT_socBrick12_0 1;
BA_ "GenSigType" SG_ 2630615040 BATT_socBrick11_0 1;
BA_ "GenSigType" SG_ 2630615040 BATT_socBrick09_0 1;
BA_ "GenSigType" SG_ 2630615040 BATT_socBrick10_0 1;
BA_ "GenSigType" SG_ 2630615041 BATT_socBrick12_1 1;
BA_ "GenSigType" SG_ 2630615041 BATT_socBrick11_1 1;
BA_ "GenSigType" SG_ 2630615041 BATT_socBrick09_1 1;
BA_ "GenSigType" SG_ 2630615041 BATT_socBrick10_1 1;
BA_ "GenSigType" SG_ 2630615042 BATT_socBrick12_2 1;
BA_ "GenSigType" SG_ 2630615042 BATT_socBrick11_2 1;
BA_ "GenSigType" SG_ 2630615042 BATT_socBrick09_2 1;
BA_ "GenSigType" SG_ 2630615042 BATT_socBrick10_2 1;
BA_ "GenSigType" SG_ 2630615043 BATT_socBrick12_3 1;
BA_ "GenSigType" SG_ 2630615043 BATT_socBrick11_3 1;
BA_ "GenSigType" SG_ 2630615043 BATT_socBrick09_3 1;
BA_ "GenSigType" SG_ 2630615043 BATT_socBrick10_3 1;
BA_ "GenSigType" SG_ 2630615044 BATT_socBrick12_4 1;
BA_ "GenSigType" SG_ 2630615044 BATT_socBrick11_4 1;
BA_ "GenSigType" SG_ 2630615044 BATT_socBrick09_4 1;
BA_ "GenSigType" SG_ 2630615044 BATT_socBrick10_4 1;
BA_ "GenSigType" SG_ 2630615045 BATT_socBrick12_5 1;
BA_ "GenSigType" SG_ 2630615045 BATT_socBrick11_5 1;
BA_ "GenSigType" SG_ 2630615045 BATT_socBrick09_5 1;
BA_ "GenSigType" SG_ 2630615045 BATT_socBrick10_5 1;
BA_ "GenSigType" SG_ 2630615046 BATT_socBrick12_6 1;
BA_ "GenSigType" SG_ 2630615046 BATT_socBrick11_6 1;
BA_ "GenSigType" SG_ 2630615046 BATT_socBrick09_6 1;
BA_ "GenSigType" SG_ 2630615046 BATT_socBrick10_6 1;
BA_ "GenSigType" SG_ 2630615047 BATT_socBrick12_7 1;
BA_ "GenSigType" SG_ 2630615047 BATT_socBrick11_7 1;
BA_ "GenSigType" SG_ 2630615047 BATT_socBrick09_7 1;
BA_ "GenSigType" SG_ 2630615047 BATT_socBrick10_7 1;
BA_ "GenSigType" SG_ 2630877184 BATT_socLoLimit_0 1;
BA_ "GenSigType" SG_ 2630877184 BATT_socBrick13_0 1;
BA_ "GenSigType" SG_ 2630877184 BATT_socHiLimit_0 1;
BA_ "GenSigType" SG_ 2630877184 BATT_socBrick14_0 1;
BA_ "GenSigType" SG_ 2630877184 BATT_socState_0 1;
BA_ "GenSigType" SG_ 2630877185 BATT_socBrick13_1 1;
BA_ "GenSigType" SG_ 2630877185 BATT_socHiLimit_1 1;
BA_ "GenSigType" SG_ 2630877185 BATT_socBrick14_1 1;
BA_ "GenSigType" SG_ 2630877185 BATT_socLoLimit_1 1;
BA_ "GenSigType" SG_ 2630877185 BATT_socState_1 1;
BA_ "GenSigType" SG_ 2630877186 BATT_socHiLimit_2 1;
BA_ "GenSigType" SG_ 2630877186 BATT_socState_2 1;
BA_ "GenSigType" SG_ 2630877186 BATT_socLoLimit_2 1;
BA_ "GenSigType" SG_ 2630877186 BATT_socBrick13_2 1;
BA_ "GenSigType" SG_ 2630877186 BATT_socBrick14_2 1;
BA_ "GenSigType" SG_ 2630877187 BATT_socState_3 1;
BA_ "GenSigType" SG_ 2630877187 BATT_socLoLimit_3 1;
BA_ "GenSigType" SG_ 2630877187 BATT_socHiLimit_3 1;
BA_ "GenSigType" SG_ 2630877187 BATT_socBrick14_3 1;
BA_ "GenSigType" SG_ 2630877187 BATT_socBrick13_3 1;
BA_ "GenSigType" SG_ 2630877188 BATT_socLoLimit_4 1;
BA_ "GenSigType" SG_ 2630877188 BATT_socHiLimit_4 1;
BA_ "GenSigType" SG_ 2630877188 BATT_socBrick14_4 1;
BA_ "GenSigType" SG_ 2630877188 BATT_socState_4 1;
BA_ "GenSigType" SG_ 2630877188 BATT_socBrick13_4 1;
BA_ "GenSigType" SG_ 2630877189 BATT_socState_5 1;
BA_ "GenSigType" SG_ 2630877189 BATT_socLoLimit_5 1;
BA_ "GenSigType" SG_ 2630877189 BATT_socBrick13_5 1;
BA_ "GenSigType" SG_ 2630877189 BATT_socHiLimit_5 1;
BA_ "GenSigType" SG_ 2630877189 BATT_socBrick14_5 1;
BA_ "GenSigType" SG_ 2630877190 BATT_socBrick14_6 1;
BA_ "GenSigType" SG_ 2630877190 BATT_socBrick13_6 1;
BA_ "GenSigType" SG_ 2630877190 BATT_socHiLimit_6 1;
BA_ "GenSigType" SG_ 2630877190 BATT_socLoLimit_6 1;
BA_ "GenSigType" SG_ 2630877190 BATT_socState_6 1;
BA_ "GenSigType" SG_ 2630877191 BATT_socBrick14_7 1;
BA_ "GenSigType" SG_ 2630877191 BATT_socBrick13_7 1;
BA_ "GenSigType" SG_ 2630877191 BATT_socState_7 1;
BA_ "GenSigType" SG_ 2630877191 BATT_socLoLimit_7 1;
BA_ "GenSigType" SG_ 2630877191 BATT_socHiLimit_7 1;
BA_ "GenSigType" SG_ 2642935808 BATT_canRXFifoWaterMark_0 1;
BA_ "GenSigType" SG_ 2642935808 BATT_canRXFifoSizeUsed_0 1;
BA_ "GenSigType" SG_ 2642935808 BATT_canTXFifoWaterMark_0 1;
BA_ "GenSigType" SG_ 2642935808 BATT_canTXFifoSizeUsed_0 1;
BA_ "GenSigType" SG_ 2642935809 BATT_canRXFifoWaterMark_1 1;
BA_ "GenSigType" SG_ 2642935809 BATT_canRXFifoSizeUsed_1 1;
BA_ "GenSigType" SG_ 2642935809 BATT_canTXFifoWaterMark_1 1;
BA_ "GenSigType" SG_ 2642935809 BATT_canTXFifoSizeUsed_1 1;
BA_ "GenSigType" SG_ 2642935810 BATT_canTXFifoWaterMark_2 1;
BA_ "GenSigType" SG_ 2642935810 BATT_canRXFifoSizeUsed_2 1;
BA_ "GenSigType" SG_ 2642935810 BATT_canTXFifoSizeUsed_2 1;
BA_ "GenSigType" SG_ 2642935810 BATT_canRXFifoWaterMark_2 1;
BA_ "GenSigType" SG_ 2642935811 BATT_canRXFifoWaterMark_3 1;
BA_ "GenSigType" SG_ 2642935811 BATT_canTXFifoWaterMark_3 1;
BA_ "GenSigType" SG_ 2642935811 BATT_canRXFifoSizeUsed_3 1;
BA_ "GenSigType" SG_ 2642935811 BATT_canTXFifoSizeUsed_3 1;
BA_ "GenSigType" SG_ 2642935812 BATT_canTXFifoWaterMark_4 1;
BA_ "GenSigType" SG_ 2642935812 BATT_canRXFifoWaterMark_4 1;
BA_ "GenSigType" SG_ 2642935812 BATT_canTXFifoSizeUsed_4 1;
BA_ "GenSigType" SG_ 2642935812 BATT_canRXFifoSizeUsed_4 1;
BA_ "GenSigType" SG_ 2642935813 BATT_canTXFifoSizeUsed_5 1;
BA_ "GenSigType" SG_ 2642935813 BATT_canTXFifoWaterMark_5 1;
BA_ "GenSigType" SG_ 2642935813 BATT_canRXFifoSizeUsed_5 1;
BA_ "GenSigType" SG_ 2642935813 BATT_canRXFifoWaterMark_5 1;
BA_ "GenSigType" SG_ 2642935814 BATT_canRXFifoWaterMark_6 1;
BA_ "GenSigType" SG_ 2642935814 BATT_canTXFifoWaterMark_6 1;
BA_ "GenSigType" SG_ 2642935814 BATT_canRXFifoSizeUsed_6 1;
BA_ "GenSigType" SG_ 2642935814 BATT_canTXFifoSizeUsed_6 1;
BA_ "GenSigType" SG_ 2642935815 BATT_canTXFifoSizeUsed_7 1;
BA_ "GenSigType" SG_ 2642935815 BATT_canTXFifoWaterMark_7 1;
BA_ "GenSigType" SG_ 2642935815 BATT_canRXFifoSizeUsed_7 1;
BA_ "GenSigType" SG_ 2642935815 BATT_canRXFifoWaterMark_7 1;
BA_ "GenSigType" SG_ 2643001344 BATT_deltaQTaskOsTimeDelta 0;
BA_ "GenSigType" SG_ 2643001344 BATT_deltaQEvent 0;
BA_ "GenSigType" SG_ 2643001344 BATT_deltaQFifoSizeUsed 0;
BA_ "GenSigType" SG_ 2643001344 BATT_deltaQFifoWaterMark 0;
BA_ "GenSigType" SG_ 2643001344 BATT_deltaQTaskOsTime 0;
BA_ "GenSigType" SG_ 2643001344 BATT_deltaQError 0;
BA_ "GenSigType" SG_ 2643001344 BATT_deltaQState 0;
BA_ "GenSigType" SG_ 2671771648 BATT_boardADC_PACK_0 0;
BA_ "GenSigType" SG_ 2671771648 BATT_boardADC_COMMON_DRAIN_0 0;
BA_ "GenSigType" SG_ 2671771648 BATT_boardADC_LOAD_0 0;
BA_ "GenSigType" SG_ 2671771649 BATT_boardADC_LOAD_1 0;
BA_ "GenSigType" SG_ 2671771649 BATT_boardADC_COMMON_DRAIN_1 0;
BA_ "GenSigType" SG_ 2671771649 BATT_boardADC_PACK_1 0;
BA_ "GenSigType" SG_ 2671771650 BATT_boardADC_LOAD_2 0;
BA_ "GenSigType" SG_ 2671771650 BATT_boardADC_COMMON_DRAIN_2 0;
BA_ "GenSigType" SG_ 2671771650 BATT_boardADC_PACK_2 0;
BA_ "GenSigType" SG_ 2671771651 BATT_boardADC_COMMON_DRAIN_3 0;
BA_ "GenSigType" SG_ 2671771651 BATT_boardADC_LOAD_3 0;
BA_ "GenSigType" SG_ 2671771651 BATT_boardADC_PACK_3 0;
BA_ "GenSigType" SG_ 2671771652 BATT_boardADC_LOAD_4 0;
BA_ "GenSigType" SG_ 2671771652 BATT_boardADC_COMMON_DRAIN_4 0;
BA_ "GenSigType" SG_ 2671771652 BATT_boardADC_PACK_4 0;
BA_ "GenSigType" SG_ 2671771653 BATT_boardADC_PACK_5 0;
BA_ "GenSigType" SG_ 2671771653 BATT_boardADC_LOAD_5 0;
BA_ "GenSigType" SG_ 2671771653 BATT_boardADC_COMMON_DRAIN_5 0;
BA_ "GenSigType" SG_ 2671771654 BATT_boardADC_PACK_6 0;
BA_ "GenSigType" SG_ 2671771654 BATT_boardADC_COMMON_DRAIN_6 0;
BA_ "GenSigType" SG_ 2671771654 BATT_boardADC_LOAD_6 0;
BA_ "GenSigType" SG_ 2671771655 BATT_boardADC_COMMON_DRAIN_7 0;
BA_ "GenSigType" SG_ 2671771655 BATT_boardADC_LOAD_7 0;
BA_ "GenSigType" SG_ 2671771655 BATT_boardADC_PACK_7 0;
BA_ "GenSigType" SG_ 2672033792 BATT_boardADC_12V_0 0;
BA_ "GenSigType" SG_ 2672033792 BATT_boardADC_3V3_0 0;
BA_ "GenSigType" SG_ 2672033792 BATT_boardADC_5V_0 0;
BA_ "GenSigType" SG_ 2672033793 BATT_boardADC_12V_1 0;
BA_ "GenSigType" SG_ 2672033793 BATT_boardADC_5V_1 0;
BA_ "GenSigType" SG_ 2672033793 BATT_boardADC_3V3_1 0;
BA_ "GenSigType" SG_ 2672033794 BATT_boardADC_3V3_2 0;
BA_ "GenSigType" SG_ 2672033794 BATT_boardADC_12V_2 0;
BA_ "GenSigType" SG_ 2672033794 BATT_boardADC_5V_2 0;
BA_ "GenSigType" SG_ 2672033795 BATT_boardADC_12V_3 0;
BA_ "GenSigType" SG_ 2672033795 BATT_boardADC_3V3_3 0;
BA_ "GenSigType" SG_ 2672033795 BATT_boardADC_5V_3 0;
BA_ "GenSigType" SG_ 2672033796 BATT_boardADC_12V_4 0;
BA_ "GenSigType" SG_ 2672033796 BATT_boardADC_5V_4 0;
BA_ "GenSigType" SG_ 2672033796 BATT_boardADC_3V3_4 0;
BA_ "GenSigType" SG_ 2672033797 BATT_boardADC_12V_5 0;
BA_ "GenSigType" SG_ 2672033797 BATT_boardADC_5V_5 0;
BA_ "GenSigType" SG_ 2672033797 BATT_boardADC_3V3_5 0;
BA_ "GenSigType" SG_ 2672033798 BATT_boardADC_12V_6 0;
BA_ "GenSigType" SG_ 2672033798 BATT_boardADC_5V_6 0;
BA_ "GenSigType" SG_ 2672033798 BATT_boardADC_3V3_6 0;
BA_ "GenSigType" SG_ 2672033799 BATT_boardADC_3V3_7 0;
BA_ "GenSigType" SG_ 2672033799 BATT_boardADC_5V_7 0;
BA_ "GenSigType" SG_ 2672033799 BATT_boardADC_12V_7 0;
BA_ "GenSigType" SG_ 2672295936 BATT_boardADC_SHUNT_TEMP_0 0;
BA_ "GenSigType" SG_ 2672295936 BATT_boardADC_AMB_TEMP_0 0;
BA_ "GenSigType" SG_ 2672295936 BATT_boardADC_FET_TEMP_0 0;
BA_ "GenSigType" SG_ 2672295937 BATT_boardADC_SHUNT_TEMP_1 0;
BA_ "GenSigType" SG_ 2672295937 BATT_boardADC_AMB_TEMP_1 0;
BA_ "GenSigType" SG_ 2672295937 BATT_boardADC_FET_TEMP_1 0;
BA_ "GenSigType" SG_ 2672295938 BATT_boardADC_AMB_TEMP_2 0;
BA_ "GenSigType" SG_ 2672295938 BATT_boardADC_SHUNT_TEMP_2 0;
BA_ "GenSigType" SG_ 2672295938 BATT_boardADC_FET_TEMP_2 0;
BA_ "GenSigType" SG_ 2672295939 BATT_boardADC_SHUNT_TEMP_3 0;
BA_ "GenSigType" SG_ 2672295939 BATT_boardADC_FET_TEMP_3 0;
BA_ "GenSigType" SG_ 2672295939 BATT_boardADC_AMB_TEMP_3 0;
BA_ "GenSigType" SG_ 2672295940 BATT_boardADC_FET_TEMP_4 0;
BA_ "GenSigType" SG_ 2672295940 BATT_boardADC_SHUNT_TEMP_4 0;
BA_ "GenSigType" SG_ 2672295940 BATT_boardADC_AMB_TEMP_4 0;
BA_ "GenSigType" SG_ 2672295941 BATT_boardADC_FET_TEMP_5 0;
BA_ "GenSigType" SG_ 2672295941 BATT_boardADC_AMB_TEMP_5 0;
BA_ "GenSigType" SG_ 2672295941 BATT_boardADC_SHUNT_TEMP_5 0;
BA_ "GenSigType" SG_ 2672295942 BATT_boardADC_AMB_TEMP_6 0;
BA_ "GenSigType" SG_ 2672295942 BATT_boardADC_FET_TEMP_6 0;
BA_ "GenSigType" SG_ 2672295942 BATT_boardADC_SHUNT_TEMP_6 0;
BA_ "GenSigType" SG_ 2672295943 BATT_boardADC_FET_TEMP_7 0;
BA_ "GenSigType" SG_ 2672295943 BATT_boardADC_AMB_TEMP_7 0;
BA_ "GenSigType" SG_ 2672295943 BATT_boardADC_SHUNT_TEMP_7 0;
BA_ "GenSigSNA" SG_ 2626158596 BATT_vBrick05_4 65535;
BA_ "GenSigSNA" SG_ 2626158596 BATT_vBrick06_4 65535;
BA_ "GenSigSNA" SG_ 2626158596 BATT_vBrick07_4 65535;
BA_ "GenSigSNA" SG_ 2626158596 BATT_vBrick08_4 65535;
BA_ "GenSigSNA" SG_ 2626158597 BATT_vBrick05_5 65535;
BA_ "GenSigSNA" SG_ 2626158597 BATT_vBrick06_5 65535;
BA_ "GenSigSNA" SG_ 2626158597 BATT_vBrick07_5 65535;
BA_ "GenSigSNA" SG_ 2626158597 BATT_vBrick08_5 65535;
BA_ "GenSigSNA" SG_ 2626158598 BATT_vBrick05_6 65535;
BA_ "GenSigSNA" SG_ 2626158598 BATT_vBrick06_6 65535;
BA_ "GenSigSNA" SG_ 2626158598 BATT_vBrick07_6 65535;
BA_ "GenSigSNA" SG_ 2626158598 BATT_vBrick08_6 65535;
BA_ "GenSigSNA" SG_ 2626158599 BATT_vBrick07_7 65535;
BA_ "GenSigSNA" SG_ 2626158599 BATT_vBrick05_7 65535;
BA_ "GenSigSNA" SG_ 2626158599 BATT_vBrick08_7 65535;
BA_ "GenSigSNA" SG_ 2626158599 BATT_vBrick06_7 65535;
BA_ "GenSigSNA" SG_ 2626420736 BATT_vBrick12_0 65535;
BA_ "GenSigSNA" SG_ 2626420736 BATT_vBrick11_0 65535;
BA_ "GenSigSNA" SG_ 2626420736 BATT_vBrick10_0 65535;
BA_ "GenSigSNA" SG_ 2626420736 BATT_vBrick09_0 65535;
BA_ "GenSigSNA" SG_ 2626420737 BATT_vBrick12_1 65535;
BA_ "GenSigSNA" SG_ 2626420737 BATT_vBrick11_1 65535;
BA_ "GenSigSNA" SG_ 2626420737 BATT_vBrick10_1 65535;
BA_ "GenSigSNA" SG_ 2626420737 BATT_vBrick09_1 65535;
BA_ "GenSigSNA" SG_ 2626420738 BATT_vBrick10_2 65535;
BA_ "GenSigSNA" SG_ 2626420738 BATT_vBrick12_2 65535;
BA_ "GenSigSNA" SG_ 2626420738 BATT_vBrick11_2 65535;
BA_ "GenSigSNA" SG_ 2626420738 BATT_vBrick09_2 65535;
BA_ "GenSigSNA" SG_ 2626420739 BATT_vBrick10_3 65535;
BA_ "GenSigSNA" SG_ 2626420739 BATT_vBrick12_3 65535;
BA_ "GenSigSNA" SG_ 2626420739 BATT_vBrick11_3 65535;
BA_ "GenSigSNA" SG_ 2626420739 BATT_vBrick09_3 65535;
BA_ "GenSigSNA" SG_ 2626420740 BATT_vBrick10_4 65535;
BA_ "GenSigSNA" SG_ 2626420740 BATT_vBrick12_4 65535;
BA_ "GenSigSNA" SG_ 2626420740 BATT_vBrick11_4 65535;
BA_ "GenSigSNA" SG_ 2626420740 BATT_vBrick09_4 65535;
BA_ "GenSigSNA" SG_ 2626420741 BATT_vBrick12_5 65535;
BA_ "GenSigSNA" SG_ 2626420741 BATT_vBrick11_5 65535;
BA_ "GenSigSNA" SG_ 2626420741 BATT_vBrick10_5 65535;
BA_ "GenSigSNA" SG_ 2626420741 BATT_vBrick09_5 65535;
BA_ "GenSigSNA" SG_ 2626420742 BATT_vBrick12_6 65535;
BA_ "GenSigSNA" SG_ 2626420742 BATT_vBrick11_6 65535;
BA_ "GenSigSNA" SG_ 2626420742 BATT_vBrick10_6 65535;
BA_ "GenSigSNA" SG_ 2626420742 BATT_vBrick09_6 65535;
BA_ "GenSigSNA" SG_ 2626420743 BATT_vBrick11_7 65535;
BA_ "GenSigSNA" SG_ 2626420743 BATT_vBrick10_7 65535;
BA_ "GenSigSNA" SG_ 2626420743 BATT_vBrick09_7 65535;
BA_ "GenSigSNA" SG_ 2626420743 BATT_vBrick12_7 65535;
BA_ "GenSigSNA" SG_ 2626682880 BATT_vBrick13_0 65535;
BA_ "GenSigSNA" SG_ 2626682880 BATT_vBrick14_0 65535;
BA_ "GenSigSNA" SG_ 2626682881 BATT_vBrick14_1 65535;
BA_ "GenSigSNA" SG_ 2626682881 BATT_vBrick13_1 65535;
BA_ "GenSigSNA" SG_ 2626682882 BATT_vBrick13_2 65535;
BA_ "GenSigSNA" SG_ 2626682882 BATT_vBrick14_2 65535;
BA_ "GenSigSNA" SG_ 2626682883 BATT_vBrick13_3 65535;
BA_ "GenSigSNA" SG_ 2626682883 BATT_vBrick14_3 65535;
BA_ "GenSigSNA" SG_ 2626682884 BATT_vBrick13_4 65535;
BA_ "GenSigSNA" SG_ 2626682884 BATT_vBrick14_4 65535;
BA_ "GenSigSNA" SG_ 2626682885 BATT_vBrick14_5 65535;
BA_ "GenSigSNA" SG_ 2626682885 BATT_vBrick13_5 65535;
BA_ "GenSigSNA" SG_ 2626682886 BATT_vBrick14_6 65535;
BA_ "GenSigSNA" SG_ 2626682886 BATT_vBrick13_6 65535;
BA_ "GenSigSNA" SG_ 2626682887 BATT_vBrick13_7 65535;
BA_ "GenSigSNA" SG_ 2626682887 BATT_vBrick14_7 65535;
BA_ "GenSigSNA" SG_ 2626748416 BATT_HarnessImpedance_9_0 65535;
BA_ "GenSigSNA" SG_ 2626748416 BATT_HarnessImpedance_8_0 65535;
BA_ "GenSigSNA" SG_ 2626748416 BATT_HarnessImpedance_0_0 65535;
BA_ "GenSigSNA" SG_ 2626748416 BATT_HarnessImpedance_13_0 65535;
BA_ "GenSigSNA" SG_ 2626748416 BATT_HarnessImpedance_12_0 65535;
BA_ "GenSigSNA" SG_ 2626748416 BATT_HarnessImpedance_11_0 65535;
BA_ "GenSigSNA" SG_ 2626748416 BATT_HarnessImpedance_10_0 65535;
BA_ "GenSigSNA" SG_ 2626748416 BATT_HarnessImpedance_2_0 65535;
BA_ "GenSigSNA" SG_ 2626748416 BATT_HarnessImpedance_1_0 65535;
BA_ "GenSigSNA" SG_ 2626748416 BATT_HarnessImpedance_5_0 65535;
BA_ "GenSigSNA" SG_ 2626748416 BATT_HarnessImpedance_14_0 65535;
BA_ "GenSigSNA" SG_ 2626748416 BATT_HarnessImpedance_4_0 65535;
BA_ "GenSigSNA" SG_ 2626748416 BATT_HarnessImpedance_3_0 65535;
BA_ "GenSigSNA" SG_ 2626748416 BATT_HarnessImpedance_7_0 65535;
BA_ "GenSigSNA" SG_ 2626748416 BATT_HarnessImpedance_6_0 65535;
BA_ "GenSigSNA" SG_ 2626748417 BATT_HarnessImpedance_14_1 65535;
BA_ "GenSigSNA" SG_ 2626748417 BATT_HarnessImpedance_8_1 65535;
BA_ "GenSigSNA" SG_ 2626748417 BATT_HarnessImpedance_7_1 65535;
BA_ "GenSigSNA" SG_ 2626748417 BATT_HarnessImpedance_11_1 65535;
BA_ "GenSigSNA" SG_ 2626748417 BATT_HarnessImpedance_10_1 65535;
BA_ "GenSigSNA" SG_ 2626748417 BATT_HarnessImpedance_9_1 65535;
BA_ "GenSigSNA" SG_ 2626748417 BATT_HarnessImpedance_0_1 65535;
BA_ "GenSigSNA" SG_ 2626748417 BATT_HarnessImpedance_13_1 65535;
BA_ "GenSigSNA" SG_ 2626748417 BATT_HarnessImpedance_12_1 65535;
BA_ "GenSigSNA" SG_ 2626748417 BATT_HarnessImpedance_2_1 65535;
BA_ "GenSigSNA" SG_ 2626748417 BATT_HarnessImpedance_1_1 65535;
BA_ "GenSigSNA" SG_ 2626748417 BATT_HarnessImpedance_4_1 65535;
BA_ "GenSigSNA" SG_ 2626748417 BATT_HarnessImpedance_3_1 65535;
BA_ "GenSigSNA" SG_ 2626748417 BATT_HarnessImpedance_6_1 65535;
BA_ "GenSigSNA" SG_ 2626748417 BATT_HarnessImpedance_5_1 65535;
BA_ "GenSigSNA" SG_ 2626748418 BATT_HarnessImpedance_14_2 65535;
BA_ "GenSigSNA" SG_ 2626748418 BATT_HarnessImpedance_13_2 65535;
BA_ "GenSigSNA" SG_ 2626748418 BATT_HarnessImpedance_12_2 65535;
BA_ "GenSigSNA" SG_ 2626748418 BATT_HarnessImpedance_11_2 65535;
BA_ "GenSigSNA" SG_ 2626748418 BATT_HarnessImpedance_10_2 65535;
BA_ "GenSigSNA" SG_ 2626748418 BATT_HarnessImpedance_9_2 65535;
BA_ "GenSigSNA" SG_ 2626748418 BATT_HarnessImpedance_8_2 65535;
BA_ "GenSigSNA" SG_ 2626748418 BATT_HarnessImpedance_7_2 65535;
BA_ "GenSigSNA" SG_ 2626748418 BATT_HarnessImpedance_6_2 65535;
BA_ "GenSigSNA" SG_ 2626748418 BATT_HarnessImpedance_5_2 65535;
BA_ "GenSigSNA" SG_ 2626748418 BATT_HarnessImpedance_4_2 65535;
BA_ "GenSigSNA" SG_ 2626748418 BATT_HarnessImpedance_3_2 65535;
BA_ "GenSigSNA" SG_ 2626748418 BATT_HarnessImpedance_2_2 65535;
BA_ "GenSigSNA" SG_ 2626748418 BATT_HarnessImpedance_1_2 65535;
BA_ "GenSigSNA" SG_ 2626748418 BATT_HarnessImpedance_0_2 65535;
BA_ "GenSigSNA" SG_ 2626748419 BATT_HarnessImpedance_14_3 65535;
BA_ "GenSigSNA" SG_ 2626748419 BATT_HarnessImpedance_13_3 65535;
BA_ "GenSigSNA" SG_ 2626748419 BATT_HarnessImpedance_12_3 65535;
BA_ "GenSigSNA" SG_ 2626748419 BATT_HarnessImpedance_11_3 65535;
BA_ "GenSigSNA" SG_ 2626748419 BATT_HarnessImpedance_10_3 65535;
BA_ "GenSigSNA" SG_ 2626748419 BATT_HarnessImpedance_9_3 65535;
BA_ "GenSigSNA" SG_ 2626748419 BATT_HarnessImpedance_8_3 65535;
BA_ "GenSigSNA" SG_ 2626748419 BATT_HarnessImpedance_7_3 65535;
BA_ "GenSigSNA" SG_ 2626748419 BATT_HarnessImpedance_6_3 65535;
BA_ "GenSigSNA" SG_ 2626748419 BATT_HarnessImpedance_1_3 65535;
BA_ "GenSigSNA" SG_ 2626748419 BATT_HarnessImpedance_5_3 65535;
BA_ "GenSigSNA" SG_ 2626748419 BATT_HarnessImpedance_4_3 65535;
BA_ "GenSigSNA" SG_ 2626748419 BATT_HarnessImpedance_3_3 65535;
BA_ "GenSigSNA" SG_ 2626748419 BATT_HarnessImpedance_2_3 65535;
BA_ "GenSigSNA" SG_ 2626748419 BATT_HarnessImpedance_0_3 65535;
BA_ "GenSigSNA" SG_ 2626748420 BATT_HarnessImpedance_0_4 65535;
BA_ "GenSigSNA" SG_ 2626748420 BATT_HarnessImpedance_2_4 65535;
BA_ "GenSigSNA" SG_ 2626748420 BATT_HarnessImpedance_1_4 65535;
BA_ "GenSigSNA" SG_ 2626748420 BATT_HarnessImpedance_5_4 65535;
BA_ "GenSigSNA" SG_ 2626748420 BATT_HarnessImpedance_4_4 65535;
BA_ "GenSigSNA" SG_ 2626748420 BATT_HarnessImpedance_3_4 65535;
BA_ "GenSigSNA" SG_ 2626748420 BATT_HarnessImpedance_7_4 65535;
BA_ "GenSigSNA" SG_ 2626748420 BATT_HarnessImpedance_6_4 65535;
BA_ "GenSigSNA" SG_ 2626748420 BATT_HarnessImpedance_9_4 65535;
BA_ "GenSigSNA" SG_ 2626748420 BATT_HarnessImpedance_8_4 65535;
BA_ "GenSigSNA" SG_ 2626748420 BATT_HarnessImpedance_11_4 65535;
BA_ "GenSigSNA" SG_ 2626748420 BATT_HarnessImpedance_10_4 65535;
BA_ "GenSigSNA" SG_ 2626748420 BATT_HarnessImpedance_13_4 65535;
BA_ "GenSigSNA" SG_ 2626748420 BATT_HarnessImpedance_12_4 65535;
BA_ "GenSigSNA" SG_ 2626748420 BATT_HarnessImpedance_14_4 65535;
BA_ "GenSigSNA" SG_ 2626748421 BATT_HarnessImpedance_11_5 65535;
BA_ "GenSigSNA" SG_ 2626748421 BATT_HarnessImpedance_10_5 65535;
BA_ "GenSigSNA" SG_ 2626748421 BATT_HarnessImpedance_7_5 65535;
BA_ "GenSigSNA" SG_ 2626748421 BATT_HarnessImpedance_6_5 65535;
BA_ "GenSigSNA" SG_ 2626748421 BATT_HarnessImpedance_13_5 65535;
BA_ "GenSigSNA" SG_ 2626748421 BATT_HarnessImpedance_12_5 65535;
BA_ "GenSigSNA" SG_ 2626748421 BATT_HarnessImpedance_9_5 65535;
BA_ "GenSigSNA" SG_ 2626748421 BATT_HarnessImpedance_8_5 65535;
BA_ "GenSigSNA" SG_ 2626748421 BATT_HarnessImpedance_14_5 65535;
BA_ "GenSigSNA" SG_ 2626748421 BATT_HarnessImpedance_1_5 65535;
BA_ "GenSigSNA" SG_ 2626748421 BATT_HarnessImpedance_0_5 65535;
BA_ "GenSigSNA" SG_ 2626748421 BATT_HarnessImpedance_3_5 65535;
BA_ "GenSigSNA" SG_ 2626748421 BATT_HarnessImpedance_2_5 65535;
BA_ "GenSigSNA" SG_ 2626748421 BATT_HarnessImpedance_5_5 65535;
BA_ "GenSigSNA" SG_ 2626748421 BATT_HarnessImpedance_4_5 65535;
BA_ "GenSigSNA" SG_ 2626748422 BATT_HarnessImpedance_9_6 65535;
BA_ "GenSigSNA" SG_ 2626748422 BATT_HarnessImpedance_8_6 65535;
BA_ "GenSigSNA" SG_ 2626748422 BATT_HarnessImpedance_12_6 65535;
BA_ "GenSigSNA" SG_ 2626748422 BATT_HarnessImpedance_11_6 65535;
BA_ "GenSigSNA" SG_ 2626748422 BATT_HarnessImpedance_10_6 65535;
BA_ "GenSigSNA" SG_ 2626748422 BATT_HarnessImpedance_14_6 65535;
BA_ "GenSigSNA" SG_ 2626748422 BATT_HarnessImpedance_13_6 65535;
BA_ "GenSigSNA" SG_ 2626748422 BATT_HarnessImpedance_7_6 65535;
BA_ "GenSigSNA" SG_ 2626748422 BATT_HarnessImpedance_6_6 65535;
BA_ "GenSigSNA" SG_ 2626748422 BATT_HarnessImpedance_3_6 65535;
BA_ "GenSigSNA" SG_ 2626748422 BATT_HarnessImpedance_2_6 65535;
BA_ "GenSigSNA" SG_ 2626748422 BATT_HarnessImpedance_0_6 65535;
BA_ "GenSigSNA" SG_ 2626748422 BATT_HarnessImpedance_1_6 65535;
BA_ "GenSigSNA" SG_ 2626748422 BATT_HarnessImpedance_5_6 65535;
BA_ "GenSigSNA" SG_ 2626748422 BATT_HarnessImpedance_4_6 65535;
BA_ "GenSigSNA" SG_ 2626748423 BATT_HarnessImpedance_13_7 65535;
BA_ "GenSigSNA" SG_ 2626748423 BATT_HarnessImpedance_14_7 65535;
BA_ "GenSigSNA" SG_ 2626748423 BATT_HarnessImpedance_5_7 65535;
BA_ "GenSigSNA" SG_ 2626748423 BATT_HarnessImpedance_12_7 65535;
BA_ "GenSigSNA" SG_ 2626748423 BATT_HarnessImpedance_4_7 65535;
BA_ "GenSigSNA" SG_ 2626748423 BATT_HarnessImpedance_7_7 65535;
BA_ "GenSigSNA" SG_ 2626748423 BATT_HarnessImpedance_6_7 65535;
BA_ "GenSigSNA" SG_ 2626748423 BATT_HarnessImpedance_9_7 65535;
BA_ "GenSigSNA" SG_ 2626748423 BATT_HarnessImpedance_1_7 65535;
BA_ "GenSigSNA" SG_ 2626748423 BATT_HarnessImpedance_8_7 65535;
BA_ "GenSigSNA" SG_ 2626748423 BATT_HarnessImpedance_0_7 65535;
BA_ "GenSigSNA" SG_ 2626748423 BATT_HarnessImpedance_11_7 65535;
BA_ "GenSigSNA" SG_ 2626748423 BATT_HarnessImpedance_3_7 65535;
BA_ "GenSigSNA" SG_ 2626748423 BATT_HarnessImpedance_10_7 65535;
BA_ "GenSigSNA" SG_ 2626748423 BATT_HarnessImpedance_2_7 65535;
BA_ "GenSigSNA" SG_ 2626813952 BATT_HrnsImpDelta_1_0 65535;
BA_ "GenSigSNA" SG_ 2626813952 BATT_HrnsImpDelta_3_0 65535;
BA_ "GenSigSNA" SG_ 2626813952 BATT_HrnsImpDelta_2_0 65535;
BA_ "GenSigSNA" SG_ 2626813952 BATT_HrnsImpDelta_0_0 65535;
BA_ "GenSigSNA" SG_ 2626813953 BATT_HrnsImpDelta_1_1 65535;
BA_ "GenSigSNA" SG_ 2626813953 BATT_HrnsImpDelta_0_1 65535;
BA_ "GenSigSNA" SG_ 2626813953 BATT_HrnsImpDelta_2_1 65535;
BA_ "GenSigSNA" SG_ 2626813953 BATT_HrnsImpDelta_3_1 65535;
BA_ "GenSigSNA" SG_ 2626813954 BATT_HrnsImpDelta_0_2 65535;
BA_ "GenSigSNA" SG_ 2626813954 BATT_HrnsImpDelta_1_2 65535;
BA_ "GenSigSNA" SG_ 2626813954 BATT_HrnsImpDelta_2_2 65535;
BA_ "GenSigSNA" SG_ 2626813954 BATT_HrnsImpDelta_3_2 65535;
BA_ "GenSigSNA" SG_ 2626813955 BATT_HrnsImpDelta_3_3 65535;
BA_ "GenSigSNA" SG_ 2626813955 BATT_HrnsImpDelta_2_3 65535;
BA_ "GenSigSNA" SG_ 2626813955 BATT_HrnsImpDelta_0_3 65535;
BA_ "GenSigSNA" SG_ 2626813955 BATT_HrnsImpDelta_1_3 65535;
BA_ "GenSigSNA" SG_ 2626813956 BATT_HrnsImpDelta_0_4 65535;
BA_ "GenSigSNA" SG_ 2626813956 BATT_HrnsImpDelta_3_4 65535;
BA_ "GenSigSNA" SG_ 2626813956 BATT_HrnsImpDelta_1_4 65535;
BA_ "GenSigSNA" SG_ 2626813956 BATT_HrnsImpDelta_2_4 65535;
BA_ "GenSigSNA" SG_ 2626813957 BATT_HrnsImpDelta_0_5 65535;
BA_ "GenSigSNA" SG_ 2626813957 BATT_HrnsImpDelta_3_5 65535;
BA_ "GenSigSNA" SG_ 2626813957 BATT_HrnsImpDelta_2_5 65535;
BA_ "GenSigSNA" SG_ 2626813957 BATT_HrnsImpDelta_1_5 65535;
BA_ "GenSigSNA" SG_ 2626813958 BATT_HrnsImpDelta_2_6 65535;
BA_ "GenSigSNA" SG_ 2626813958 BATT_HrnsImpDelta_3_6 65535;
BA_ "GenSigSNA" SG_ 2626813958 BATT_HrnsImpDelta_1_6 65535;
BA_ "GenSigSNA" SG_ 2626813958 BATT_HrnsImpDelta_0_6 65535;
BA_ "GenSigSNA" SG_ 2626813959 BATT_HrnsImpDelta_0_7 65535;
BA_ "GenSigSNA" SG_ 2626813959 BATT_HrnsImpDelta_3_7 65535;
BA_ "GenSigSNA" SG_ 2626813959 BATT_HrnsImpDelta_1_7 65535;
BA_ "GenSigSNA" SG_ 2626813959 BATT_HrnsImpDelta_2_7 65535;
BA_ "GenSigSNA" SG_ 2626818048 BATT_HrnsImpDelta_5_0 65535;
BA_ "GenSigSNA" SG_ 2626818048 BATT_HrnsImpDelta_7_0 65535;
BA_ "GenSigSNA" SG_ 2626818048 BATT_HrnsImpDelta_6_0 65535;
BA_ "GenSigSNA" SG_ 2626818048 BATT_HrnsImpDelta_4_0 65535;
BA_ "GenSigSNA" SG_ 2626818049 BATT_HrnsImpDelta_7_1 65535;
BA_ "GenSigSNA" SG_ 2626818049 BATT_HrnsImpDelta_4_1 65535;
BA_ "GenSigSNA" SG_ 2626818049 BATT_HrnsImpDelta_5_1 65535;
BA_ "GenSigSNA" SG_ 2626818049 BATT_HrnsImpDelta_6_1 65535;
BA_ "GenSigSNA" SG_ 2626818050 BATT_HrnsImpDelta_6_2 65535;
BA_ "GenSigSNA" SG_ 2626818050 BATT_HrnsImpDelta_5_2 65535;
BA_ "GenSigSNA" SG_ 2626818050 BATT_HrnsImpDelta_7_2 65535;
BA_ "GenSigSNA" SG_ 2626818050 BATT_HrnsImpDelta_4_2 65535;
BA_ "GenSigSNA" SG_ 2626818051 BATT_HrnsImpDelta_4_3 65535;
BA_ "GenSigSNA" SG_ 2626818051 BATT_HrnsImpDelta_5_3 65535;
BA_ "GenSigSNA" SG_ 2626818051 BATT_HrnsImpDelta_6_3 65535;
BA_ "GenSigSNA" SG_ 2626818051 BATT_HrnsImpDelta_7_3 65535;
BA_ "GenSigSNA" SG_ 2626818052 BATT_HrnsImpDelta_6_4 65535;
BA_ "GenSigSNA" SG_ 2626818052 BATT_HrnsImpDelta_7_4 65535;
BA_ "GenSigSNA" SG_ 2626818052 BATT_HrnsImpDelta_4_4 65535;
BA_ "GenSigSNA" SG_ 2626818052 BATT_HrnsImpDelta_5_4 65535;
BA_ "GenSigSNA" SG_ 2626818053 BATT_HrnsImpDelta_6_5 65535;
BA_ "GenSigSNA" SG_ 2626818053 BATT_HrnsImpDelta_4_5 65535;
BA_ "GenSigSNA" SG_ 2626818053 BATT_HrnsImpDelta_5_5 65535;
BA_ "GenSigSNA" SG_ 2626818053 BATT_HrnsImpDelta_7_5 65535;
BA_ "GenSigSNA" SG_ 2626818054 BATT_HrnsImpDelta_4_6 65535;
BA_ "GenSigSNA" SG_ 2626818054 BATT_HrnsImpDelta_5_6 65535;
BA_ "GenSigSNA" SG_ 2626818054 BATT_HrnsImpDelta_7_6 65535;
BA_ "GenSigSNA" SG_ 2626818054 BATT_HrnsImpDelta_6_6 65535;
BA_ "GenSigSNA" SG_ 2626818055 BATT_HrnsImpDelta_5_7 65535;
BA_ "GenSigSNA" SG_ 2626818055 BATT_HrnsImpDelta_7_7 65535;
BA_ "GenSigSNA" SG_ 2626818055 BATT_HrnsImpDelta_6_7 65535;
BA_ "GenSigSNA" SG_ 2626818055 BATT_HrnsImpDelta_4_7 65535;
BA_ "GenSigSNA" SG_ 2626822144 BATT_HrnsImpDelta_11_0 65535;
BA_ "GenSigSNA" SG_ 2626822144 BATT_HrnsImpDelta_9_0 65535;
BA_ "GenSigSNA" SG_ 2626822144 BATT_HrnsImpDelta_10_0 65535;
BA_ "GenSigSNA" SG_ 2626822144 BATT_HrnsImpDelta_8_0 65535;
BA_ "GenSigSNA" SG_ 2626822145 BATT_HrnsImpDelta_11_1 65535;
BA_ "GenSigSNA" SG_ 2626822145 BATT_HrnsImpDelta_10_1 65535;
BA_ "GenSigSNA" SG_ 2626822145 BATT_HrnsImpDelta_9_1 65535;
BA_ "GenSigSNA" SG_ 2626822145 BATT_HrnsImpDelta_8_1 65535;
BA_ "GenSigSNA" SG_ 2626822146 BATT_HrnsImpDelta_8_2 65535;
BA_ "GenSigSNA" SG_ 2626822146 BATT_HrnsImpDelta_11_2 65535;
BA_ "GenSigSNA" SG_ 2626822146 BATT_HrnsImpDelta_10_2 65535;
BA_ "GenSigSNA" SG_ 2626822146 BATT_HrnsImpDelta_9_2 65535;
BA_ "GenSigSNA" SG_ 2626822147 BATT_HrnsImpDelta_8_3 65535;
BA_ "GenSigSNA" SG_ 2626822147 BATT_HrnsImpDelta_11_3 65535;
BA_ "GenSigSNA" SG_ 2626822147 BATT_HrnsImpDelta_10_3 65535;
BA_ "GenSigSNA" SG_ 2626822147 BATT_HrnsImpDelta_9_3 65535;
BA_ "GenSigSNA" SG_ 2626822148 BATT_HrnsImpDelta_8_4 65535;
BA_ "GenSigSNA" SG_ 2626822148 BATT_HrnsImpDelta_9_4 65535;
BA_ "GenSigSNA" SG_ 2626822148 BATT_HrnsImpDelta_10_4 65535;
BA_ "GenSigSNA" SG_ 2626822148 BATT_HrnsImpDelta_11_4 65535;
BA_ "GenSigSNA" SG_ 2626822149 BATT_HrnsImpDelta_10_5 65535;
BA_ "GenSigSNA" SG_ 2626822149 BATT_HrnsImpDelta_11_5 65535;
BA_ "GenSigSNA" SG_ 2626822149 BATT_HrnsImpDelta_8_5 65535;
BA_ "GenSigSNA" SG_ 2626822149 BATT_HrnsImpDelta_9_5 65535;
BA_ "GenSigSNA" SG_ 2626822150 BATT_HrnsImpDelta_10_6 65535;
BA_ "GenSigSNA" SG_ 2626822150 BATT_HrnsImpDelta_8_6 65535;
BA_ "GenSigSNA" SG_ 2626822150 BATT_HrnsImpDelta_9_6 65535;
BA_ "GenSigSNA" SG_ 2626822150 BATT_HrnsImpDelta_11_6 65535;
BA_ "GenSigSNA" SG_ 2626822151 BATT_HrnsImpDelta_8_7 65535;
BA_ "GenSigSNA" SG_ 2626822151 BATT_HrnsImpDelta_11_7 65535;
BA_ "GenSigSNA" SG_ 2626822151 BATT_HrnsImpDelta_10_7 65535;
BA_ "GenSigSNA" SG_ 2626822151 BATT_HrnsImpDelta_9_7 65535;
BA_ "GenSigSNA" SG_ 2626826240 BATT_HrnsImpDelta_14_0 65535;
BA_ "GenSigSNA" SG_ 2626826240 BATT_HrnsImpDelta_13_0 65535;
BA_ "GenSigSNA" SG_ 2626826240 BATT_HrnsImpDelta_12_0 65535;
BA_ "GenSigSNA" SG_ 2626826241 BATT_HrnsImpDelta_13_1 65535;
BA_ "GenSigSNA" SG_ 2626826241 BATT_HrnsImpDelta_12_1 65535;
BA_ "GenSigSNA" SG_ 2626826241 BATT_HrnsImpDelta_14_1 65535;
BA_ "GenSigSNA" SG_ 2626826242 BATT_HrnsImpDelta_12_2 65535;
BA_ "GenSigSNA" SG_ 2626826242 BATT_HrnsImpDelta_14_2 65535;
BA_ "GenSigSNA" SG_ 2626826242 BATT_HrnsImpDelta_13_2 65535;
BA_ "GenSigSNA" SG_ 2626826243 BATT_HrnsImpDelta_13_3 65535;
BA_ "GenSigSNA" SG_ 2626826243 BATT_HrnsImpDelta_14_3 65535;
BA_ "GenSigSNA" SG_ 2626826243 BATT_HrnsImpDelta_12_3 65535;
BA_ "GenSigSNA" SG_ 2626826244 BATT_HrnsImpDelta_14_4 65535;
BA_ "GenSigSNA" SG_ 2626826244 BATT_HrnsImpDelta_12_4 65535;
BA_ "GenSigSNA" SG_ 2626826244 BATT_HrnsImpDelta_13_4 65535;
BA_ "GenSigSNA" SG_ 2626826245 BATT_HrnsImpDelta_12_5 65535;
BA_ "GenSigSNA" SG_ 2626826245 BATT_HrnsImpDelta_13_5 65535;
BA_ "GenSigSNA" SG_ 2626826245 BATT_HrnsImpDelta_14_5 65535;
BA_ "GenSigSNA" SG_ 2626826246 BATT_HrnsImpDelta_12_6 65535;
BA_ "GenSigSNA" SG_ 2626826246 BATT_HrnsImpDelta_13_6 65535;
BA_ "GenSigSNA" SG_ 2626826246 BATT_HrnsImpDelta_14_6 65535;
BA_ "GenSigSNA" SG_ 2626826247 BATT_HrnsImpDelta_12_7 65535;
BA_ "GenSigSNA" SG_ 2626826247 BATT_HrnsImpDelta_13_7 65535;
BA_ "GenSigSNA" SG_ 2626826247 BATT_HrnsImpDelta_14_7 65535;
BA_ "GenSigSNA" SG_ 2630090752 BATT_socBrick04_0 1023;
BA_ "GenSigSNA" SG_ 2630090752 BATT_socBrick03_0 1023;
BA_ "GenSigSNA" SG_ 2630090752 BATT_socBrick02_0 1023;
BA_ "GenSigSNA" SG_ 2630090752 BATT_socBrick01_0 1023;
BA_ "GenSigSNA" SG_ 2630090753 BATT_socBrick04_1 1023;
BA_ "GenSigSNA" SG_ 2630090753 BATT_socBrick03_1 1023;
BA_ "GenSigSNA" SG_ 2630090753 BATT_socBrick02_1 1023;
BA_ "GenSigSNA" SG_ 2630090753 BATT_socBrick01_1 1023;
BA_ "GenSigSNA" SG_ 2630090754 BATT_socBrick04_2 1023;
BA_ "GenSigSNA" SG_ 2630090754 BATT_socBrick03_2 1023;
BA_ "GenSigSNA" SG_ 2630090754 BATT_socBrick02_2 1023;
BA_ "GenSigSNA" SG_ 2630090754 BATT_socBrick01_2 1023;
BA_ "GenSigSNA" SG_ 2630090755 BATT_socBrick04_3 1023;
BA_ "GenSigSNA" SG_ 2630090755 BATT_socBrick03_3 1023;
BA_ "GenSigSNA" SG_ 2630090755 BATT_socBrick02_3 1023;
BA_ "GenSigSNA" SG_ 2630090755 BATT_socBrick01_3 1023;
BA_ "GenSigSNA" SG_ 2630090756 BATT_socBrick04_4 1023;
BA_ "GenSigSNA" SG_ 2630090756 BATT_socBrick03_4 1023;
BA_ "GenSigSNA" SG_ 2630090756 BATT_socBrick02_4 1023;
BA_ "GenSigSNA" SG_ 2630090756 BATT_socBrick01_4 1023;
BA_ "GenSigSNA" SG_ 2630090757 BATT_socBrick04_5 1023;
BA_ "GenSigSNA" SG_ 2630090757 BATT_socBrick03_5 1023;
BA_ "GenSigSNA" SG_ 2630090757 BATT_socBrick02_5 1023;
BA_ "GenSigSNA" SG_ 2630090757 BATT_socBrick01_5 1023;
BA_ "GenSigSNA" SG_ 2630090758 BATT_socBrick04_6 1023;
BA_ "GenSigSNA" SG_ 2630090758 BATT_socBrick03_6 1023;
BA_ "GenSigSNA" SG_ 2630090758 BATT_socBrick02_6 1023;
BA_ "GenSigSNA" SG_ 2630090758 BATT_socBrick01_6 1023;
BA_ "GenSigSNA" SG_ 2630090759 BATT_socBrick04_7 1023;
BA_ "GenSigSNA" SG_ 2630090759 BATT_socBrick03_7 1023;
BA_ "GenSigSNA" SG_ 2630090759 BATT_socBrick02_7 1023;
BA_ "GenSigSNA" SG_ 2630090759 BATT_socBrick01_7 1023;
BA_ "GenSigSNA" SG_ 2630352896 BATT_socBrick08_0 1023;
BA_ "GenSigSNA" SG_ 2630352896 BATT_socBrick07_0 1023;
BA_ "GenSigSNA" SG_ 2630352896 BATT_socBrick06_0 1023;
BA_ "GenSigSNA" SG_ 2630352896 BATT_socBrick05_0 1023;
BA_ "GenSigSNA" SG_ 2630352897 BATT_socBrick08_1 1023;
BA_ "GenSigSNA" SG_ 2630352897 BATT_socBrick07_1 1023;
BA_ "GenSigSNA" SG_ 2630352897 BATT_socBrick06_1 1023;
BA_ "GenSigSNA" SG_ 2630352897 BATT_socBrick05_1 1023;
BA_ "GenSigSNA" SG_ 2630352898 BATT_socBrick08_2 1023;
BA_ "GenSigSNA" SG_ 2630352898 BATT_socBrick07_2 1023;
BA_ "GenSigSNA" SG_ 2630352898 BATT_socBrick06_2 1023;
BA_ "GenSigSNA" SG_ 2630352898 BATT_socBrick05_2 1023;
BA_ "GenSigSNA" SG_ 2630352899 BATT_socBrick08_3 1023;
BA_ "GenSigSNA" SG_ 2630352899 BATT_socBrick07_3 1023;
BA_ "GenSigSNA" SG_ 2630352899 BATT_socBrick06_3 1023;
BA_ "GenSigSNA" SG_ 2630352899 BATT_socBrick05_3 1023;
BA_ "GenSigSNA" SG_ 2630352900 BATT_socBrick08_4 1023;
BA_ "GenSigSNA" SG_ 2630352900 BATT_socBrick07_4 1023;
BA_ "GenSigSNA" SG_ 2630352900 BATT_socBrick06_4 1023;
BA_ "GenSigSNA" SG_ 2630352900 BATT_socBrick05_4 1023;
BA_ "GenSigSNA" SG_ 2630352901 BATT_socBrick08_5 1023;
BA_ "GenSigSNA" SG_ 2630352901 BATT_socBrick07_5 1023;
BA_ "GenSigSNA" SG_ 2630352901 BATT_socBrick06_5 1023;
BA_ "GenSigSNA" SG_ 2630352901 BATT_socBrick05_5 1023;
BA_ "GenSigSNA" SG_ 2630352902 BATT_socBrick08_6 1023;
BA_ "GenSigSNA" SG_ 2630352902 BATT_socBrick07_6 1023;
BA_ "GenSigSNA" SG_ 2630352902 BATT_socBrick06_6 1023;
BA_ "GenSigSNA" SG_ 2630352902 BATT_socBrick05_6 1023;
BA_ "GenSigSNA" SG_ 2630352903 BATT_socBrick08_7 1023;
BA_ "GenSigSNA" SG_ 2630352903 BATT_socBrick07_7 1023;
BA_ "GenSigSNA" SG_ 2630352903 BATT_socBrick06_7 1023;
BA_ "GenSigSNA" SG_ 2630352903 BATT_socBrick05_7 1023;
BA_ "GenSigSNA" SG_ 2630615040 BATT_socBrick12_0 1023;
BA_ "GenSigSNA" SG_ 2630615040 BATT_socBrick11_0 1023;
BA_ "GenSigSNA" SG_ 2630615040 BATT_socBrick09_0 1023;
BA_ "GenSigSNA" SG_ 2630615040 BATT_socBrick10_0 1023;
BA_ "GenSigSNA" SG_ 2630615041 BATT_socBrick12_1 1023;
BA_ "GenSigSNA" SG_ 2630615041 BATT_socBrick11_1 1023;
BA_ "GenSigSNA" SG_ 2630615041 BATT_socBrick09_1 1023;
BA_ "GenSigSNA" SG_ 2630615041 BATT_socBrick10_1 1023;
BA_ "GenSigSNA" SG_ 2630615042 BATT_socBrick12_2 1023;
BA_ "GenSigSNA" SG_ 2630615042 BATT_socBrick11_2 1023;
BA_ "GenSigSNA" SG_ 2630615042 BATT_socBrick09_2 1023;
BA_ "GenSigSNA" SG_ 2630615042 BATT_socBrick10_2 1023;
BA_ "GenSigSNA" SG_ 2630615043 BATT_socBrick12_3 1023;
BA_ "GenSigSNA" SG_ 2630615043 BATT_socBrick11_3 1023;
BA_ "GenSigSNA" SG_ 2630615043 BATT_socBrick09_3 1023;
BA_ "GenSigSNA" SG_ 2630615043 BATT_socBrick10_3 1023;
BA_ "GenSigSNA" SG_ 2630615044 BATT_socBrick12_4 1023;
BA_ "GenSigSNA" SG_ 2630615044 BATT_socBrick11_4 1023;
BA_ "GenSigSNA" SG_ 2630615044 BATT_socBrick09_4 1023;
BA_ "GenSigSNA" SG_ 2630615044 BATT_socBrick10_4 1023;
BA_ "GenSigSNA" SG_ 2630615045 BATT_socBrick12_5 1023;
BA_ "GenSigSNA" SG_ 2630615045 BATT_socBrick11_5 1023;
BA_ "GenSigSNA" SG_ 2630615045 BATT_socBrick09_5 1023;
BA_ "GenSigSNA" SG_ 2630615045 BATT_socBrick10_5 1023;
BA_ "GenSigSNA" SG_ 2630615046 BATT_socBrick12_6 1023;
BA_ "GenSigSNA" SG_ 2630615046 BATT_socBrick11_6 1023;
BA_ "GenSigSNA" SG_ 2630615046 BATT_socBrick09_6 1023;
BA_ "GenSigSNA" SG_ 2630615046 BATT_socBrick10_6 1023;
BA_ "GenSigSNA" SG_ 2630615047 BATT_socBrick12_7 1023;
BA_ "GenSigSNA" SG_ 2630615047 BATT_socBrick11_7 1023;
BA_ "GenSigSNA" SG_ 2630615047 BATT_socBrick09_7 1023;
BA_ "GenSigSNA" SG_ 2630615047 BATT_socBrick10_7 1023;
BA_ "GenSigSNA" SG_ 2630877184 BATT_socBrick13_0 1023;
BA_ "GenSigSNA" SG_ 2630877184 BATT_socBrick14_0 1023;
BA_ "GenSigSNA" SG_ 2630877185 BATT_socBrick13_1 1023;
BA_ "GenSigSNA" SG_ 2630877185 BATT_socBrick14_1 1023;
BA_ "GenSigSNA" SG_ 2630877186 BATT_socBrick13_2 1023;
BA_ "GenSigSNA" SG_ 2630877186 BATT_socBrick14_2 1023;
BA_ "GenSigSNA" SG_ 2630877187 BATT_socBrick14_3 1023;
BA_ "GenSigSNA" SG_ 2630877187 BATT_socBrick13_3 1023;
BA_ "GenSigSNA" SG_ 2630877188 BATT_socBrick14_4 1023;
BA_ "GenSigSNA" SG_ 2630877188 BATT_socBrick13_4 1023;
BA_ "GenSigSNA" SG_ 2630877189 BATT_socBrick13_5 1023;
BA_ "GenSigSNA" SG_ 2630877189 BATT_socBrick14_5 1023;
BA_ "GenSigSNA" SG_ 2630877190 BATT_socBrick14_6 1023;
BA_ "GenSigSNA" SG_ 2630877190 BATT_socBrick13_6 1023;
BA_ "GenSigSNA" SG_ 2630877191 BATT_socBrick14_7 1023;
BA_ "GenSigSNA" SG_ 2630877191 BATT_socBrick13_7 1023;
VAL_ 2626158596 BATT_vBrick05_4  65535 "SNA"  ;
VAL_ 2626158596 BATT_vBrick06_4  65535 "SNA"  ;
VAL_ 2626158596 BATT_vBrick07_4  65535 "SNA"  ;
VAL_ 2626158596 BATT_vBrick08_4  65535 "SNA"  ;
VAL_ 2626158597 BATT_vBrick05_5  65535 "SNA"  ;
VAL_ 2626158597 BATT_vBrick06_5  65535 "SNA"  ;
VAL_ 2626158597 BATT_vBrick07_5  65535 "SNA"  ;
VAL_ 2626158597 BATT_vBrick08_5  65535 "SNA"  ;
VAL_ 2626158598 BATT_vBrick05_6  65535 "SNA"  ;
VAL_ 2626158598 BATT_vBrick06_6  65535 "SNA"  ;
VAL_ 2626158598 BATT_vBrick07_6  65535 "SNA"  ;
VAL_ 2626158598 BATT_vBrick08_6  65535 "SNA"  ;
VAL_ 2626158599 BATT_vBrick07_7  65535 "SNA"  ;
VAL_ 2626158599 BATT_vBrick05_7  65535 "SNA"  ;
VAL_ 2626158599 BATT_vBrick08_7  65535 "SNA"  ;
VAL_ 2626158599 BATT_vBrick06_7  65535 "SNA"  ;
VAL_ 2626420736 BATT_vBrick12_0  65535 "SNA"  ;
VAL_ 2626420736 BATT_vBrick11_0  65535 "SNA"  ;
VAL_ 2626420736 BATT_vBrick10_0  65535 "SNA"  ;
VAL_ 2626420736 BATT_vBrick09_0  65535 "SNA"  ;
VAL_ 2626420737 BATT_vBrick12_1  65535 "SNA"  ;
VAL_ 2626420737 BATT_vBrick11_1  65535 "SNA"  ;
VAL_ 2626420737 BATT_vBrick10_1  65535 "SNA"  ;
VAL_ 2626420737 BATT_vBrick09_1  65535 "SNA"  ;
VAL_ 2626420738 BATT_vBrick10_2  65535 "SNA"  ;
VAL_ 2626420738 BATT_vBrick12_2  65535 "SNA"  ;
VAL_ 2626420738 BATT_vBrick11_2  65535 "SNA"  ;
VAL_ 2626420738 BATT_vBrick09_2  65535 "SNA"  ;
VAL_ 2626420739 BATT_vBrick10_3  65535 "SNA"  ;
VAL_ 2626420739 BATT_vBrick12_3  65535 "SNA"  ;
VAL_ 2626420739 BATT_vBrick11_3  65535 "SNA"  ;
VAL_ 2626420739 BATT_vBrick09_3  65535 "SNA"  ;
VAL_ 2626420740 BATT_vBrick10_4  65535 "SNA"  ;
VAL_ 2626420740 BATT_vBrick12_4  65535 "SNA"  ;
VAL_ 2626420740 BATT_vBrick11_4  65535 "SNA"  ;
VAL_ 2626420740 BATT_vBrick09_4  65535 "SNA"  ;
VAL_ 2626420741 BATT_vBrick12_5  65535 "SNA"  ;
VAL_ 2626420741 BATT_vBrick11_5  65535 "SNA"  ;
VAL_ 2626420741 BATT_vBrick10_5  65535 "SNA"  ;
VAL_ 2626420741 BATT_vBrick09_5  65535 "SNA"  ;
VAL_ 2626420742 BATT_vBrick12_6  65535 "SNA"  ;
VAL_ 2626420742 BATT_vBrick11_6  65535 "SNA"  ;
VAL_ 2626420742 BATT_vBrick10_6  65535 "SNA"  ;
VAL_ 2626420742 BATT_vBrick09_6  65535 "SNA"  ;
VAL_ 2626420743 BATT_vBrick11_7  65535 "SNA"  ;
VAL_ 2626420743 BATT_vBrick10_7  65535 "SNA"  ;
VAL_ 2626420743 BATT_vBrick09_7  65535 "SNA"  ;
VAL_ 2626420743 BATT_vBrick12_7  65535 "SNA"  ;
VAL_ 2626682880 BATT_vBrick13_0  65535 "SNA"  ;
VAL_ 2626682880 BATT_vBrick14_0  65535 "SNA"  ;
VAL_ 2626682881 BATT_vBrick14_1  65535 "SNA"  ;
VAL_ 2626682881 BATT_vBrick13_1  65535 "SNA"  ;
VAL_ 2626682882 BATT_vBrick13_2  65535 "SNA"  ;
VAL_ 2626682882 BATT_vBrick14_2  65535 "SNA"  ;
VAL_ 2626682883 BATT_vBrick13_3  65535 "SNA"  ;
VAL_ 2626682883 BATT_vBrick14_3  65535 "SNA"  ;
VAL_ 2626682884 BATT_vBrick13_4  65535 "SNA"  ;
VAL_ 2626682884 BATT_vBrick14_4  65535 "SNA"  ;
VAL_ 2626682885 BATT_vBrick14_5  65535 "SNA"  ;
VAL_ 2626682885 BATT_vBrick13_5  65535 "SNA"  ;
VAL_ 2626682886 BATT_vBrick14_6  65535 "SNA"  ;
VAL_ 2626682886 BATT_vBrick13_6  65535 "SNA"  ;
VAL_ 2626682887 BATT_vBrick13_7  65535 "SNA"  ;
VAL_ 2626682887 BATT_vBrick14_7  65535 "SNA"  ;
VAL_ 2630090752 BATT_socBrick04_0  1023 "SNA"  ;
VAL_ 2630090752 BATT_socBrick03_0  1023 "SNA"  ;
VAL_ 2630090752 BATT_socBrick02_0  1023 "SNA"  ;
VAL_ 2630090752 BATT_socBrick01_0  1023 "SNA"  ;
VAL_ 2630090753 BATT_socBrick04_1  1023 "SNA"  ;
VAL_ 2630090753 BATT_socBrick03_1  1023 "SNA"  ;
VAL_ 2630090753 BATT_socBrick02_1  1023 "SNA"  ;
VAL_ 2630090753 BATT_socBrick01_1  1023 "SNA"  ;
VAL_ 2630090754 BATT_socBrick04_2  1023 "SNA"  ;
VAL_ 2630090754 BATT_socBrick03_2  1023 "SNA"  ;
VAL_ 2630090754 BATT_socBrick02_2  1023 "SNA"  ;
VAL_ 2630090754 BATT_socBrick01_2  1023 "SNA"  ;
VAL_ 2630090755 BATT_socBrick04_3  1023 "SNA"  ;
VAL_ 2630090755 BATT_socBrick03_3  1023 "SNA"  ;
VAL_ 2630090755 BATT_socBrick02_3  1023 "SNA"  ;
VAL_ 2630090755 BATT_socBrick01_3  1023 "SNA"  ;
VAL_ 2630090756 BATT_socBrick04_4  1023 "SNA"  ;
VAL_ 2630090756 BATT_socBrick03_4  1023 "SNA"  ;
VAL_ 2630090756 BATT_socBrick02_4  1023 "SNA"  ;
VAL_ 2630090756 BATT_socBrick01_4  1023 "SNA"  ;
VAL_ 2630090757 BATT_socBrick04_5  1023 "SNA"  ;
VAL_ 2630090757 BATT_socBrick03_5  1023 "SNA"  ;
VAL_ 2630090757 BATT_socBrick02_5  1023 "SNA"  ;
VAL_ 2630090757 BATT_socBrick01_5  1023 "SNA"  ;
VAL_ 2630090758 BATT_socBrick04_6  1023 "SNA"  ;
VAL_ 2630090758 BATT_socBrick03_6  1023 "SNA"  ;
VAL_ 2630090758 BATT_socBrick02_6  1023 "SNA"  ;
VAL_ 2630090758 BATT_socBrick01_6  1023 "SNA"  ;
VAL_ 2630090759 BATT_socBrick04_7  1023 "SNA"  ;
VAL_ 2630090759 BATT_socBrick03_7  1023 "SNA"  ;
VAL_ 2630090759 BATT_socBrick02_7  1023 "SNA"  ;
VAL_ 2630090759 BATT_socBrick01_7  1023 "SNA"  ;
VAL_ 2630352896 BATT_socBrick08_0  1023 "SNA"  ;
VAL_ 2630352896 BATT_socBrick07_0  1023 "SNA"  ;
VAL_ 2630352896 BATT_socBrick06_0  1023 "SNA"  ;
VAL_ 2630352896 BATT_socBrick05_0  1023 "SNA"  ;
VAL_ 2630352897 BATT_socBrick08_1  1023 "SNA"  ;
VAL_ 2630352897 BATT_socBrick07_1  1023 "SNA"  ;
VAL_ 2630352897 BATT_socBrick06_1  1023 "SNA"  ;
VAL_ 2630352897 BATT_socBrick05_1  1023 "SNA"  ;
VAL_ 2630352898 BATT_socBrick08_2  1023 "SNA"  ;
VAL_ 2630352898 BATT_socBrick07_2  1023 "SNA"  ;
VAL_ 2630352898 BATT_socBrick06_2  1023 "SNA"  ;
VAL_ 2630352898 BATT_socBrick05_2  1023 "SNA"  ;
VAL_ 2630352899 BATT_socBrick08_3  1023 "SNA"  ;
VAL_ 2630352899 BATT_socBrick07_3  1023 "SNA"  ;
VAL_ 2630352899 BATT_socBrick06_3  1023 "SNA"  ;
VAL_ 2630352899 BATT_socBrick05_3  1023 "SNA"  ;
VAL_ 2630352900 BATT_socBrick08_4  1023 "SNA"  ;
VAL_ 2630352900 BATT_socBrick07_4  1023 "SNA"  ;
VAL_ 2630352900 BATT_socBrick06_4  1023 "SNA"  ;
VAL_ 2630352900 BATT_socBrick05_4  1023 "SNA"  ;
VAL_ 2630352901 BATT_socBrick08_5  1023 "SNA"  ;
VAL_ 2630352901 BATT_socBrick07_5  1023 "SNA"  ;
VAL_ 2630352901 BATT_socBrick06_5  1023 "SNA"  ;
VAL_ 2630352901 BATT_socBrick05_5  1023 "SNA"  ;
VAL_ 2630352902 BATT_socBrick08_6  1023 "SNA"  ;
VAL_ 2630352902 BATT_socBrick07_6  1023 "SNA"  ;
VAL_ 2630352902 BATT_socBrick06_6  1023 "SNA"  ;
VAL_ 2630352902 BATT_socBrick05_6  1023 "SNA"  ;
VAL_ 2630352903 BATT_socBrick08_7  1023 "SNA"  ;
VAL_ 2630352903 BATT_socBrick07_7  1023 "SNA"  ;
VAL_ 2630352903 BATT_socBrick06_7  1023 "SNA"  ;
VAL_ 2630352903 BATT_socBrick05_7  1023 "SNA"  ;
VAL_ 2630615040 BATT_socBrick12_0  1023 "SNA"  ;
VAL_ 2630615040 BATT_socBrick11_0  1023 "SNA"  ;
VAL_ 2630615040 BATT_socBrick09_0  1023 "SNA"  ;
VAL_ 2630615040 BATT_socBrick10_0  1023 "SNA"  ;
VAL_ 2630615041 BATT_socBrick12_1  1023 "SNA"  ;
VAL_ 2630615041 BATT_socBrick11_1  1023 "SNA"  ;
VAL_ 2630615041 BATT_socBrick09_1  1023 "SNA"  ;
VAL_ 2630615041 BATT_socBrick10_1  1023 "SNA"  ;
VAL_ 2630615042 BATT_socBrick12_2  1023 "SNA"  ;
VAL_ 2630615042 BATT_socBrick11_2  1023 "SNA"  ;
VAL_ 2630615042 BATT_socBrick09_2  1023 "SNA"  ;
VAL_ 2630615042 BATT_socBrick10_2  1023 "SNA"  ;
VAL_ 2630615043 BATT_socBrick12_3  1023 "SNA"  ;
VAL_ 2630615043 BATT_socBrick11_3  1023 "SNA"  ;
VAL_ 2630615043 BATT_socBrick09_3  1023 "SNA"  ;
VAL_ 2630615043 BATT_socBrick10_3  1023 "SNA"  ;
VAL_ 2630615044 BATT_socBrick12_4  1023 "SNA"  ;
VAL_ 2630615044 BATT_socBrick11_4  1023 "SNA"  ;
VAL_ 2630615044 BATT_socBrick09_4  1023 "SNA"  ;
VAL_ 2630615044 BATT_socBrick10_4  1023 "SNA"  ;
VAL_ 2630615045 BATT_socBrick12_5  1023 "SNA"  ;
VAL_ 2630615045 BATT_socBrick11_5  1023 "SNA"  ;
VAL_ 2630615045 BATT_socBrick09_5  1023 "SNA"  ;
VAL_ 2630615045 BATT_socBrick10_5  1023 "SNA"  ;
VAL_ 2630615046 BATT_socBrick12_6  1023 "SNA"  ;
VAL_ 2630615046 BATT_socBrick11_6  1023 "SNA"  ;
VAL_ 2630615046 BATT_socBrick09_6  1023 "SNA"  ;
VAL_ 2630615046 BATT_socBrick10_6  1023 "SNA"  ;
VAL_ 2630615047 BATT_socBrick12_7  1023 "SNA"  ;
VAL_ 2630615047 BATT_socBrick11_7  1023 "SNA"  ;
VAL_ 2630615047 BATT_socBrick09_7  1023 "SNA"  ;
VAL_ 2630615047 BATT_socBrick10_7  1023 "SNA"  ;
VAL_ 2630877184 BATT_socBrick13_0  1023 "SNA"  ;
VAL_ 2630877184 BATT_socBrick14_0  1023 "SNA"  ;
VAL_ 2630877184 BATT_socState_0  3 "Normal"  2 "OCV Correction"  1 "OCV Reset"  0 "Startup"  ;
VAL_ 2630877185 BATT_socBrick13_1  1023 "SNA"  ;
VAL_ 2630877185 BATT_socBrick14_1  1023 "SNA"  ;
VAL_ 2630877185 BATT_socState_1  3 "Normal"  2 "OCV Correction"  1 "OCV Reset"  0 "Startup"  ;
VAL_ 2630877186 BATT_socState_2  3 "Normal"  2 "OCV Correction"  1 "OCV Reset"  0 "Startup"  ;
VAL_ 2630877186 BATT_socBrick13_2  1023 "SNA"  ;
VAL_ 2630877186 BATT_socBrick14_2  1023 "SNA"  ;
VAL_ 2630877187 BATT_socState_3  3 "Normal"  2 "OCV Correction"  1 "OCV Reset"  0 "Startup"  ;
VAL_ 2630877187 BATT_socBrick14_3  1023 "SNA"  ;
VAL_ 2630877187 BATT_socBrick13_3  1023 "SNA"  ;
VAL_ 2630877188 BATT_socBrick14_4  1023 "SNA"  ;
VAL_ 2630877188 BATT_socState_4  3 "Normal"  2 "OCV Correction"  1 "OCV Reset"  0 "Startup"  ;
VAL_ 2630877188 BATT_socBrick13_4  1023 "SNA"  ;
VAL_ 2630877189 BATT_socState_5  3 "Normal"  2 "OCV Correction"  1 "OCV Reset"  0 "Startup"  ;
VAL_ 2630877189 BATT_socBrick13_5  1023 "SNA"  ;
VAL_ 2630877189 BATT_socBrick14_5  1023 "SNA"  ;
VAL_ 2630877190 BATT_socBrick14_6  1023 "SNA"  ;
VAL_ 2630877190 BATT_socBrick13_6  1023 "SNA"  ;
VAL_ 2630877190 BATT_socState_6  3 "Normal"  2 "OCV Correction"  1 "OCV Reset"  0 "Startup"  ;
VAL_ 2630877191 BATT_socBrick14_7  1023 "SNA"  ;
VAL_ 2630877191 BATT_socBrick13_7  1023 "SNA"  ;
VAL_ 2630877191 BATT_socState_7  3 "Normal"  2 "OCV Correction"  1 "OCV Reset"  0 "Startup"  ;
VAL_ 2643001344 BATT_deltaQEvent  8 "NMT Start TO"  7 "User Data TO"  6 "Heartbeat TO"  5 "RPDO Send Timer"  4 "Precharge Timer"  3 "Stop Request"  2 "Start Request"  1 "User Data Received"  0 "CAN Data Received"  ;
VAL_ 2643001344 BATT_deltaQError  5 "UnexpectedDisconnect"  4 "BadRequest"  3 "RequestTimeout"  2 "Charger"  1 "Comms"  0 "None"  ;
VAL_ 2643001344 BATT_deltaQState  5 "Error"  4 "Stopping"  3 "Charging"  2 "Connected"  1 "NMTStart"  0 "Disconnected"  ;
